VERSION "dbc-export 1 2026.26.6.5"

NS_ :

BS_:

BU_: APP APS BMS CC CMP CMPD CP DAS DI DIF DIR EPBL EPBR EVSE FC GTW HCML HCMR HVP ICR PCS PCS2 PLG PM PMF PMR PTC SCCM SCM SCS SDCR TAS UMC V2G VC VCBATT VCBATT0 VCBATT1 VCBATT2 VCFRONT VCFRONT1 VCFRONT2 VCLEFT VCRIGHT VCSEAT2L VCSEAT2R VCSEC

BO_ 1290 HVP_alertLog: 8 HVP
 SG_ HVP_alertID M : 0|7@1+ (1,0) [0|127] "" Vector__XXX
 SG_ HVP_alertSet : 15|1@1+ (1,0) [0|1] "" Vector__XXX
 SG_ HVP_a005_current m5 : 16|24@1- (0.001,0) [-8388.608|8388.607] "A" Vector__XXX
 SG_ HVP_a006_current m6 : 16|24@1- (0.001,0) [-8388.608|8388.607] "A" Vector__XXX
 SG_ HVP_a007_current m7 : 16|24@1- (0.001,0) [-8388.608|8388.607] "A" Vector__XXX
 SG_ HVP_a008_temperature m8 : 16|16@1- (0.01,0) [-327.68|327.67] "C" Vector__XXX
 SG_ HVP_a008_sensorId m8 : 32|6@1+ (1,1) [1|64] "" Vector__XXX
 SG_ HVP_a008_primaryChainSensor m8 : 38|1@1+ (1,0) [0|1] "" Vector__XXX
 SG_ HVP_a009_brickVoltage m9 : 16|16@1- (0.001,0) [-32.768|32.767] "V" Vector__XXX
 SG_ HVP_a009_brickId m9 : 32|7@1+ (1,1) [1|128] "" Vector__XXX
 SG_ HVP_a009_primaryChainSensor m9 : 39|1@1+ (1,0) [0|1] "" Vector__XXX
 SG_ HVP_a010_brickVoltage m10 : 16|16@1- (0.001,0) [-32.768|32.767] "V" Vector__XXX
 SG_ HVP_a010_brickId m10 : 32|7@1+ (1,1) [1|128] "" Vector__XXX
 SG_ HVP_a010_primaryChainSensor m10 : 39|1@1+ (1,0) [0|1] "" Vector__XXX
 SG_ HVP_a012_breakLocationA m12 : 16|5@1+ (1,0) [0|31] "" Vector__XXX
 SG_ HVP_a012_bmbCommStatusTypeA m12 : 21|2@1+ (1,0) [0|3] "" Vector__XXX
 SG_ HVP_a012_breakLocationB m12 : 24|5@1+ (1,0) [0|31] "" Vector__XXX
 SG_ HVP_a012_bmbCommStatusTypeB m12 : 29|2@1+ (1,0) [0|3] "" Vector__XXX
 SG_ HVP_a013_breakLocationA m13 : 16|5@1+ (1,0) [0|31] "" Vector__XXX
 SG_ HVP_a013_bmbCommStatusTypeA m13 : 21|2@1+ (1,0) [0|3] "" Vector__XXX
 SG_ HVP_a013_breakLocationB m13 : 24|5@1+ (1,0) [0|31] "" Vector__XXX
 SG_ HVP_a013_bmbCommStatusTypeB m13 : 29|2@1+ (1,0) [0|3] "" Vector__XXX
 SG_ HVP_a013_bmbChainBreakType m13 : 32|3@1+ (1,0) [0|7] "" Vector__XXX
 SG_ HVP_a018_dcLinkVoltage m18 : 16|16@1+ (0.01,0) [0|655.35] "V" Vector__XXX
 SG_ HVP_a018_battery12V m18 : 32|12@1+ (0.1,0) [0|409.5] "V" Vector__XXX
 SG_ HVP_a018_remainingPcsPowerCycles m18 : 44|2@1+ (1,0) [0|3] "" Vector__XXX
 SG_ HVP_a018_remainingPcsRecoveriesA m18 : 46|2@1+ (1,0) [0|3] "" Vector__XXX
 SG_ HVP_a018_hvcHardwareSupportsCycl m18 : 48|1@1+ (1,0) [0|1] "" Vector__XXX
 SG_ HVP_a018_pcsHardwareOkToBePowerC m18 : 49|1@1+ (1,0) [0|1] "" Vector__XXX
 SG_ HVP_a018_gpioLogicPowerEnable m18 : 50|1@1+ (1,0) [0|1] "" Vector__XXX
 SG_ HVP_a018_gpioDcDcEnable m18 : 51|1@1+ (1,0) [0|1] "" Vector__XXX
 SG_ HVP_a018_gpioChgEnable m18 : 52|1@1+ (1,0) [0|1] "" Vector__XXX
 SG_ HVP_a020_energyReserveV m20 : 16|16@1+ (0.001,0) [0|65.534] "V" Vector__XXX
 SG_ HVP_a020_shuntCurrentAux m20 : 32|16@1- (0.1,0) [-3276.8|3276.7] "A" Vector__XXX
 SG_ HVP_a020_shuntTemperature m20 : 48|16@1- (0.01,0) [-327.68|327.67] "C" Vector__XXX
 SG_ HVP_a021_pyroStatus m21 : 16|2@1+ (1,0) [0|3] "" Vector__XXX
 SG_ HVP_a021_ErTestFailed m21 : 18|1@1+ (1,0) [0|1] "" Vector__XXX
 SG_ HVP_a021_HighSideSwitchTestFaile m21 : 19|1@1+ (1,0) [0|1] "" Vector__XXX
 SG_ HVP_a021_LowSideSwitchTestFailed m21 : 20|1@1+ (1,0) [0|1] "" Vector__XXX
 SG_ HVP_a021_RefCurrentTestFailed m21 : 21|1@1+ (1,0) [0|1] "" Vector__XXX
 SG_ HVP_a021_PyroLeakTestFailed m21 : 22|1@1+ (1,0) [0|1] "" Vector__XXX
 SG_ HVP_a021_SquibResTestFailed m21 : 23|1@1+ (1,0) [0|1] "" Vector__XXX
 SG_ HVP_a021_VstTestFailed m21 : 24|1@1+ (1,0) [0|1] "" Vector__XXX
 SG_ HVP_a021_SquibResistance m21 : 25|16@1+ (0.001,0) [0|65.534] "Ohm" Vector__XXX
 SG_ HVP_a021_OneShotSequence m21 : 41|1@1+ (1,0) [0|1] "" Vector__XXX
 SG_ HVP_a021_HighSide m21 : 42|1@1+ (1,0) [0|1] "" Vector__XXX
 SG_ HVP_a021_LowSide m21 : 43|1@1+ (1,0) [0|1] "" Vector__XXX
 SG_ HVP_a021_Aout m21 : 44|14@1+ (0.001,0) [0|16.382] "V" Vector__XXX
 SG_ HVP_a022_pyroStatus m22 : 16|2@1+ (1,0) [0|3] "" Vector__XXX
 SG_ HVP_a022_PyroLeakTestFailed m22 : 18|1@1+ (1,0) [0|1] "" Vector__XXX
 SG_ HVP_a022_OneShotSequence m22 : 19|1@1+ (1,0) [0|1] "" Vector__XXX
 SG_ HVP_a022_HighSide m22 : 20|1@1+ (1,0) [0|1] "" Vector__XXX
 SG_ HVP_a022_LowSide m22 : 21|1@1+ (1,0) [0|1] "" Vector__XXX
 SG_ HVP_a022_Aout m22 : 24|14@1+ (0.001,0) [0|16.382] "V" Vector__XXX
 SG_ HVP_a022_SquibResistance m22 : 40|16@1+ (0.001,0) [0|65.534] "Ohm" Vector__XXX
 SG_ HVP_a024_voltage m24 : 16|16@1+ (0.1,0) [0|6553.5] "V" Vector__XXX
 SG_ HVP_a025_voltage1 m25 : 16|16@1+ (0.1,0) [0|6553.5] "V" Vector__XXX
 SG_ HVP_a025_voltage2 m25 : 32|16@1+ (0.1,0) [0|6553.5] "V" Vector__XXX
 SG_ HVP_a025_packVoltage m25 : 48|16@1+ (0.1,0) [0|6553.5] "V" Vector__XXX
 SG_ HVP_a026_hvilStatus m26 : 16|4@1+ (1,0) [0|15] "" Vector__XXX
 SG_ HVP_a026_inputVoltage m26 : 24|8@1+ (0.04,0) [0|10.2] "V" Vector__XXX
 SG_ HVP_a026_outputVoltage m26 : 32|8@1+ (0.04,0) [0|10.2] "V" Vector__XXX
 SG_ HVP_a026_internalVoltage m26 : 40|8@1+ (0.04,0) [0|10.16] "V" Vector__XXX
 SG_ HVP_a026_dirVoltage m26 : 48|8@1+ (0.04,0) [0|10.16] "V" Vector__XXX
 SG_ HVP_a026_difVoltage m26 : 56|8@1+ (0.04,0) [0|10.16] "V" Vector__XXX
 SG_ HVP_a028_packVoltage m28 : 16|16@1+ (0.1,0) [0|6553.5] "V" Vector__XXX
 SG_ HVP_a028_sumOfBrickV m28 : 32|16@1+ (0.1,0) [0|6553.5] "V" Vector__XXX
 SG_ HVP_a030_packPositiveLinkV m30 : 16|16@1- (0.1,0) [-3276.8|3276.7] "V" Vector__XXX
 SG_ HVP_a030_dcPositiveLinkV m30 : 32|16@1- (0.1,0) [-3276.8|3276.7] "V" Vector__XXX
 SG_ HVP_a031_packNegativeLinkV m31 : 16|16@1- (0.1,0) [-3276.8|3276.7] "V" Vector__XXX
 SG_ HVP_a031_dcNegativeLinkV m31 : 32|16@1- (0.1,0) [-3276.8|3276.7] "V" Vector__XXX
 SG_ HVP_a033_contactorPowerV m33 : 16|16@1+ (0.1,0) [0|6553.5] "V" Vector__XXX
 SG_ HVP_a033_coilCurrent m33 : 32|16@1+ (0.1,0) [0|6553.5] "A" Vector__XXX
 SG_ HVP_a033_pwmDutyCylePositive m33 : 48|8@1+ (1,0) [0|255] "Percentage" Vector__XXX
 SG_ HVP_a033_pwmDutyCyleNegative m33 : 56|8@1+ (1,0) [0|255] "Percentage" Vector__XXX
 SG_ HVP_a035_contactorPowerV m35 : 16|16@1+ (0.1,0) [0|6553.5] "V" Vector__XXX
 SG_ HVP_a035_coilCurrent m35 : 32|16@1+ (0.1,0) [0|6553.5] "A" Vector__XXX
 SG_ HVP_a035_pwmDutyCylePositive m35 : 48|8@1+ (1,0) [0|255] "Percentage" Vector__XXX
 SG_ HVP_a035_pwmDutyCyleNegative m35 : 56|8@1+ (1,0) [0|255] "Percentage" Vector__XXX
 SG_ HVP_a036_pyroFiringHandle m36 : 16|4@1+ (1,0) [0|15] "" Vector__XXX
 SG_ HVP_a036_pyroFiringTime m36 : 24|16@1+ (1,0) [0|65535] "" Vector__XXX
 SG_ HVP_a036_pyroFiringAttempt m36 : 40|4@1+ (1,0) [0|15] "" Vector__XXX
 SG_ HVP_a037_pyroFiringHandle m37 : 16|4@1+ (1,0) [0|15] "" Vector__XXX
 SG_ HVP_a039_posContactorFailed m39 : 16|1@1+ (1,0) [0|1] "" Vector__XXX
 SG_ HVP_a039_negContactorFailed m39 : 17|1@1+ (1,0) [0|1] "" Vector__XXX
 SG_ HVP_a040_powerVoltage m40 : 16|8@1+ (0.1,0) [0|25.5] "V" Vector__XXX
 SG_ HVP_a040_coilCurrent m40 : 24|8@1+ (0.1,0) [0|25.5] "A" Vector__XXX
 SG_ HVP_a040_posCtrVoltageDrop m40 : 32|15@1- (0.1,0) [-1638.4|1638.3] "V" Vector__XXX
 SG_ HVP_a040_negCtrVoltageDrop m40 : 47|15@1- (0.1,0) [-1638.4|1638.3] "V" Vector__XXX
 SG_ HVP_a040_posCtrAuxOpen m40 : 62|1@1+ (1,0) [0|1] "" Vector__XXX
 SG_ HVP_a040_negCtrAuxOpen m40 : 63|1@1+ (1,0) [0|1] "" Vector__XXX
 SG_ HVP_a041_overCurrent m41 : 16|1@1+ (1,0) [0|1] "" Vector__XXX
 SG_ HVP_a041_overChargeCurrent m41 : 17|1@1+ (1,0) [0|1] "" Vector__XXX
 SG_ HVP_a041_overDischargeCurrent m41 : 18|1@1+ (1,0) [0|1] "" Vector__XXX
 SG_ HVP_a041_overVoltage m41 : 19|1@1+ (1,0) [0|1] "" Vector__XXX
 SG_ HVP_a041_overTemperature m41 : 20|1@1+ (1,0) [0|1] "" Vector__XXX
 SG_ HVP_a041_underVoltage m41 : 21|1@1+ (1,0) [0|1] "" Vector__XXX
 SG_ HVP_a041_crashEvent m41 : 22|1@1+ (1,0) [0|1] "" Vector__XXX
 SG_ HVP_a041_packContactorHw m41 : 23|1@1+ (1,0) [0|1] "" Vector__XXX
 SG_ HVP_a041_notAllowedtoEnergize m41 : 24|1@1+ (1,0) [0|1] "" Vector__XXX
 SG_ HVP_a041_bmbMia m41 : 25|1@1+ (1,0) [0|1] "" Vector__XXX
 SG_ HVP_a041_hvilFault m41 : 26|1@1+ (1,0) [0|1] "" Vector__XXX
 SG_ HVP_a041_contactorStateWelded m41 : 27|1@1+ (1,0) [0|1] "" Vector__XXX
 SG_ HVP_a041_shuntHwMia m41 : 28|1@1+ (1,0) [0|1] "" Vector__XXX
 SG_ HVP_a041_shuntCurrentMia m41 : 29|1@1+ (1,0) [0|1] "" Vector__XXX
 SG_ HVP_a041_packVoltageMismatch m41 : 30|1@1+ (1,0) [0|1] "" Vector__XXX
 SG_ HVP_a041_gpoRequestActive m41 : 31|1@1+ (1,0) [0|1] "" Vector__XXX
 SG_ HVP_a041_fcContactorClosing m41 : 32|1@1+ (1,0) [0|1] "" Vector__XXX
 SG_ HVP_a041_fcContactorOpening m41 : 33|1@1+ (1,0) [0|1] "" Vector__XXX
 SG_ HVP_a041_resetRequestRequired m41 : 34|1@1+ (1,0) [0|1] "" Vector__XXX
 SG_ HVP_a041_pyroFault m41 : 35|1@1+ (1,0) [0|1] "" Vector__XXX
 SG_ HVP_a041_dcLinkOverVoltage m41 : 36|1@1+ (1,0) [0|1] "" Vector__XXX
 SG_ HVP_a042_overCurrent m42 : 16|1@1+ (1,0) [0|1] "" Vector__XXX
 SG_ HVP_a042_overChargeCurrent m42 : 17|1@1+ (1,0) [0|1] "" Vector__XXX
 SG_ HVP_a042_overDischargeCurrent m42 : 18|1@1+ (1,0) [0|1] "" Vector__XXX
 SG_ HVP_a042_overVoltage m42 : 19|1@1+ (1,0) [0|1] "" Vector__XXX
 SG_ HVP_a042_overTemperature m42 : 20|1@1+ (1,0) [0|1] "" Vector__XXX
 SG_ HVP_a042_crashEvent m42 : 21|1@1+ (1,0) [0|1] "" Vector__XXX
 SG_ HVP_a042_fcContactorHw m42 : 22|1@1+ (1,0) [0|1] "" Vector__XXX
 SG_ HVP_a042_notAllowedtoEnergize m42 : 23|1@1+ (1,0) [0|1] "" Vector__XXX
 SG_ HVP_a042_bmsHvsMia m42 : 24|1@1+ (1,0) [0|1] "" Vector__XXX
 SG_ HVP_a042_cpMia m42 : 25|1@1+ (1,0) [0|1] "" Vector__XXX
 SG_ HVP_a042_cpFault m42 : 26|1@1+ (1,0) [0|1] "" Vector__XXX
 SG_ HVP_a042_supply12V m42 : 27|1@1+ (1,0) [0|1] "" Vector__XXX
 SG_ HVP_a042_supplyVer m42 : 28|1@1+ (1,0) [0|1] "" Vector__XXX
 SG_ HVP_a042_packVoltageMismatch m42 : 29|1@1+ (1,0) [0|1] "" Vector__XXX
 SG_ HVP_a042_hvilFault m42 : 30|1@1+ (1,0) [0|1] "" Vector__XXX
 SG_ HVP_a042_contactorStateWelded m42 : 31|1@1+ (1,0) [0|1] "" Vector__XXX
 SG_ HVP_a042_shuntHwMia m42 : 32|1@1+ (1,0) [0|1] "" Vector__XXX
 SG_ HVP_a042_shuntCurrentMia m42 : 33|1@1+ (1,0) [0|1] "" Vector__XXX
 SG_ HVP_a042_packContactorClosing m42 : 34|1@1+ (1,0) [0|1] "" Vector__XXX
 SG_ HVP_a042_packContactorOpening m42 : 35|1@1+ (1,0) [0|1] "" Vector__XXX
 SG_ HVP_a042_resetRequestRequired m42 : 36|1@1+ (1,0) [0|1] "" Vector__XXX
 SG_ HVP_a042_cpVersionMismatch m42 : 37|1@1+ (1,0) [0|1] "" Vector__XXX
 SG_ HVP_a043_overCurrent m43 : 16|1@1+ (1,0) [0|1] "" Vector__XXX
 SG_ HVP_a043_overChargeCurrent m43 : 17|1@1+ (1,0) [0|1] "" Vector__XXX
 SG_ HVP_a043_overDischargeCurrent m43 : 18|1@1+ (1,0) [0|1] "" Vector__XXX
 SG_ HVP_a043_overVoltage m43 : 19|1@1+ (1,0) [0|1] "" Vector__XXX
 SG_ HVP_a043_overTemperature m43 : 20|1@1+ (1,0) [0|1] "" Vector__XXX
 SG_ HVP_a043_underVoltage m43 : 21|1@1+ (1,0) [0|1] "" Vector__XXX
 SG_ HVP_a043_crashEvent m43 : 22|1@1+ (1,0) [0|1] "" Vector__XXX
 SG_ HVP_a043_packContactorHw m43 : 23|1@1+ (1,0) [0|1] "" Vector__XXX
 SG_ HVP_a043_notAllowedtoEnergize m43 : 24|1@1+ (1,0) [0|1] "" Vector__XXX
 SG_ HVP_a043_bmbMia m43 : 25|1@1+ (1,0) [0|1] "" Vector__XXX
 SG_ HVP_a043_contactorOpened m43 : 26|1@1+ (1,0) [0|1] "" Vector__XXX
 SG_ HVP_a044_overCurrent m44 : 16|1@1+ (1,0) [0|1] "" Vector__XXX
 SG_ HVP_a044_overChargeCurrent m44 : 17|1@1+ (1,0) [0|1] "" Vector__XXX
 SG_ HVP_a044_overDischargeCurrent m44 : 18|1@1+ (1,0) [0|1] "" Vector__XXX
 SG_ HVP_a044_overVoltage m44 : 19|1@1+ (1,0) [0|1] "" Vector__XXX
 SG_ HVP_a044_overTemperature m44 : 20|1@1+ (1,0) [0|1] "" Vector__XXX
 SG_ HVP_a044_crashEvent m44 : 21|1@1+ (1,0) [0|1] "" Vector__XXX
 SG_ HVP_a044_fcContactorHw m44 : 22|1@1+ (1,0) [0|1] "" Vector__XXX
 SG_ HVP_a044_notAllowedtoEnergize m44 : 23|1@1+ (1,0) [0|1] "" Vector__XXX
 SG_ HVP_a044_bmsHvsMia m44 : 24|1@1+ (1,0) [0|1] "" Vector__XXX
 SG_ HVP_a044_cpMia m44 : 25|1@1+ (1,0) [0|1] "" Vector__XXX
 SG_ HVP_a044_cpFault m44 : 26|1@1+ (1,0) [0|1] "" Vector__XXX
 SG_ HVP_a044_supply12V m44 : 27|1@1+ (1,0) [0|1] "" Vector__XXX
 SG_ HVP_a044_supplyVer m44 : 28|1@1+ (1,0) [0|1] "" Vector__XXX
 SG_ HVP_a044_packVoltageMismatch m44 : 29|1@1+ (1,0) [0|1] "" Vector__XXX
 SG_ HVP_a044_contactorOpened m44 : 30|1@1+ (1,0) [0|1] "" Vector__XXX
 SG_ HVP_a044_cpVersionMismatch m44 : 31|1@1+ (1,0) [0|1] "" Vector__XXX
 SG_ HVP_a045_dcLinkVoltage m45 : 16|16@1+ (0.1,0) [0|6553.5] "V" Vector__XXX
 SG_ HVP_a046_shuntCurrent m46 : 16|16@1- (0.1,0) [-3276.8|3276.7] "A" Vector__XXX
 SG_ HVP_a046_shuntTemperature m46 : 32|16@1- (0.01,0) [-327.68|327.67] "C" Vector__XXX
 SG_ HVP_a046_asicTemperature m46 : 48|16@1- (0.01,0) [-327.68|327.67] "C" Vector__XXX
 SG_ HVP_a047_shuntCurrent m47 : 16|16@1- (0.1,0) [-3276.8|3276.7] "A" Vector__XXX
 SG_ HVP_a047_auxCurrent m47 : 32|16@1- (0.1,0) [-3276.8|3276.7] "A" Vector__XXX
 SG_ HVP_a049_contactorPowerV m49 : 16|16@1+ (0.1,0) [0|6553.5] "V" Vector__XXX
 SG_ HVP_a049_coilCurrent m49 : 32|16@1+ (0.1,0) [0|6553.5] "A" Vector__XXX
 SG_ HVP_a049_posCtrState m49 : 48|3@1+ (1,0) [1|7] "" Vector__XXX
 SG_ HVP_a049_negCtrState m49 : 51|3@1+ (1,0) [1|7] "" Vector__XXX
 SG_ HVP_a050_contactorPowerV m50 : 16|16@1+ (0.1,0) [0|6553.5] "V" Vector__XXX
 SG_ HVP_a050_coilCurrent m50 : 32|16@1+ (0.1,0) [0|6553.5] "A" Vector__XXX
 SG_ HVP_a050_posCtrState m50 : 48|3@1+ (1,0) [1|7] "" Vector__XXX
 SG_ HVP_a050_negCtrState m50 : 51|3@1+ (1,0) [1|7] "" Vector__XXX
 SG_ HVP_a051_shuntTemperature m51 : 16|16@1- (0.01,0) [-327.68|327.67] "C" Vector__XXX
 SG_ HVP_a051_shuntCurrent m51 : 32|16@1- (0.1,0) [-3276.8|3276.7] "A" Vector__XXX
 SG_ HVP_a051_energyReserveV m51 : 48|16@1+ (0.001,0) [0|65.534] "V" Vector__XXX
 SG_ HVP_a053_packVoltage m53 : 16|16@1+ (0.01,0) [0|655.35] "V" Vector__XXX
 SG_ HVP_a053_dcLinkVoltage m53 : 32|16@1+ (0.01,0) [0|655.35] "V" Vector__XXX
 SG_ HVP_a056_diagnosis m56 : 16|2@1+ (1,0) [1|3] "" Vector__XXX
 SG_ HVP_a056_shuntCurrent m56 : 24|16@1- (0.1,0) [-3276.8|3276.7] "A" Vector__XXX
 SG_ HVP_a056_posPackContactorState m56 : 40|3@1+ (1,0) [1|7] "" Vector__XXX
 SG_ HVP_a056_negPackContactorState m56 : 43|3@1+ (1,0) [1|7] "" Vector__XXX
 SG_ HVP_a056_posFcContactorState m56 : 48|3@1+ (1,0) [1|7] "" Vector__XXX
 SG_ HVP_a056_negFcContactorState m56 : 51|3@1+ (1,0) [1|7] "" Vector__XXX
 SG_ HVP_a058_VrefSample m58 : 16|16@1+ (0.0001,0) [0|6.5535] "V" Vector__XXX
 SG_ HVP_a058_bmbDeviceId m58 : 32|4@1+ (1,1) [1|16] "" Vector__XXX
 SG_ HVP_a058_VrefStatus m58 : 36|2@1+ (1,0) [0|3] "" Vector__XXX
 SG_ HVP_a058_VrefType m58 : 38|2@1+ (1,0) [0|3] "" Vector__XXX
 SG_ HVP_a060_stackVoltage m60 : 16|16@1+ (0.00128,0) [0|83.8848] "V" Vector__XXX
 SG_ HVP_a060_sumBrickVoltage m60 : 32|16@1+ (0.00128,0) [0|83.8848] "V" Vector__XXX
 SG_ HVP_a060_stackId m60 : 48|8@1+ (1,1) [1|256] "" Vector__XXX
 SG_ HVP_a062_bmbDeviceMask m62 : 16|16@1+ (1,0) [0|65535] "" Vector__XXX
 SG_ HVP_a067_hvilTypeFromHvp m67 : 16|2@1+ (1,0) [0|3] "" Vector__XXX
 SG_ HVP_a067_hvilTypeFromGateway m67 : 18|2@1+ (1,0) [0|3] "" Vector__XXX
 SG_ HVP_a067_hvilTypeIsFromCal m67 : 20|1@1+ (1,0) [0|1] "" Vector__XXX
 SG_ HVP_a068_shuntTemperature m68 : 16|16@1- (0.01,0) [-327.68|327.67] "C" Vector__XXX
 SG_ HVP_a068_shuntCurrent m68 : 32|16@1- (0.1,0) [-3276.8|3276.7] "A" Vector__XXX
 SG_ HVP_a068_energyReserveV m68 : 48|16@1+ (0.001,0) [0|65.534] "V" Vector__XXX

BO_ 938 HVP_alertMatrix: 8 HVP
 SG_ HVP_matrixIndex M : 0|4@1+ (1,0) [0|15] "" Vector__XXX
 SG_ HVP_w001_WatchdogReset m0 : 4|1@1+ (1,0) [0|1] "" Vector__XXX
 SG_ HVP_w002_UnusedAlert2 m0 : 5|1@1+ (1,0) [0|1] "" Vector__XXX
 SG_ HVP_w003_SwAssertion m0 : 6|1@1+ (1,0) [0|1] "" Vector__XXX
 SG_ HVP_w004_CrashEvent m0 : 7|1@1+ (1,0) [0|1] "" Vector__XXX
 SG_ HVP_w005_OverDchgCurrentFault m0 : 8|1@1+ (1,0) [0|1] "" Vector__XXX
 SG_ HVP_w006_OverChargeCurrentFault m0 : 9|1@1+ (1,0) [0|1] "" Vector__XXX
 SG_ HVP_w007_OverCurrentFault m0 : 10|1@1+ (1,0) [0|1] "" Vector__XXX
 SG_ HVP_w008_OverTemperatureFault m0 : 11|1@1+ (1,0) [0|1] "" Vector__XXX
 SG_ HVP_w009_OverVoltageFault m0 : 12|1@1+ (1,0) [0|1] "" Vector__XXX
 SG_ HVP_w010_UnderVoltageFault m0 : 13|1@1+ (1,0) [0|1] "" Vector__XXX
 SG_ HVP_w011_PrimaryBmbMiaFault m0 : 14|1@1+ (1,0) [0|1] "" Vector__XXX
 SG_ HVP_w012_BmbDataIntegrityLoss m0 : 15|1@1+ (1,0) [0|1] "" Vector__XXX
 SG_ HVP_w013_BmbCommunication m0 : 16|1@1+ (1,0) [0|1] "" Vector__XXX
 SG_ HVP_w014_BmsMiaOnHviFault m0 : 17|1@1+ (1,0) [0|1] "" Vector__XXX
 SG_ HVP_w015_CpMiaFault m0 : 18|1@1+ (1,0) [0|1] "" Vector__XXX
 SG_ HVP_w016_PcsMiaFault m0 : 19|1@1+ (1,0) [0|1] "" Vector__XXX
 SG_ HVP_w017_GtwMiaFault m0 : 20|1@1+ (1,0) [0|1] "" Vector__XXX
 SG_ HVP_w018_powerCyclingPcs m0 : 21|1@1+ (1,0) [0|1] "" Vector__XXX
 SG_ HVP_w019_CpFault m0 : 22|1@1+ (1,0) [0|1] "" Vector__XXX
 SG_ HVP_w020_ShuntHwMiaFault m0 : 23|1@1+ (1,0) [0|1] "" Vector__XXX
 SG_ HVP_w021_PyroMiaFault m0 : 24|1@1+ (1,0) [0|1] "" Vector__XXX
 SG_ HVP_w022_PyroMiaWarning m0 : 25|1@1+ (1,0) [0|1] "" Vector__XXX
 SG_ HVP_w023_BmbResetRecovery m0 : 26|1@1+ (1,0) [0|1] "" Vector__XXX
 SG_ HVP_w024_Supply12vFault m0 : 27|1@1+ (1,0) [0|1] "" Vector__XXX
 SG_ HVP_w025_VerSupplyFault m0 : 28|1@1+ (1,0) [0|1] "" Vector__XXX
 SG_ HVP_w026_HvilFault m0 : 29|1@1+ (1,0) [0|1] "" Vector__XXX
 SG_ HVP_w027_BmsMiaOnHvsFault m0 : 30|1@1+ (1,0) [0|1] "" Vector__XXX
 SG_ HVP_w028_PackVoltMismatchFault m0 : 31|1@1+ (1,0) [0|1] "" Vector__XXX
 SG_ HVP_w029_EnsMiaFault m0 : 32|1@1+ (1,0) [0|1] "" Vector__XXX
 SG_ HVP_w030_PackPosCtrArcFault m0 : 33|1@1+ (1,0) [0|1] "" Vector__XXX
 SG_ HVP_w031_packNegCtrArcFault m0 : 34|1@1+ (1,0) [0|1] "" Vector__XXX
 SG_ HVP_w032_ShuntHwAndBmsMiaFault m0 : 35|1@1+ (1,0) [0|1] "" Vector__XXX
 SG_ HVP_w033_fcContHwFault m0 : 36|1@1+ (1,0) [0|1] "" Vector__XXX
 SG_ HVP_w034_cpMismatchFault m0 : 37|1@1+ (1,0) [0|1] "" Vector__XXX
 SG_ HVP_w035_packContHwFault m0 : 38|1@1+ (1,0) [0|1] "" Vector__XXX
 SG_ HVP_w036_pyroFuseBlown m0 : 39|1@1+ (1,0) [0|1] "" Vector__XXX
 SG_ HVP_w037_pyroFuseFailedToBlow m0 : 40|1@1+ (1,0) [0|1] "" Vector__XXX
 SG_ HVP_w038_CpilFault m0 : 41|1@1+ (1,0) [0|1] "" Vector__XXX
 SG_ HVP_w039_PackContactorFellOpen m0 : 42|1@1+ (1,0) [0|1] "" Vector__XXX
 SG_ HVP_w040_FcContactorFellOpen m0 : 43|1@1+ (1,0) [0|1] "" Vector__XXX
 SG_ HVP_w041_packCtrCloseBlocked m0 : 44|1@1+ (1,0) [0|1] "" Vector__XXX
 SG_ HVP_w042_fcCtrCloseBlocked m0 : 45|1@1+ (1,0) [0|1] "" Vector__XXX
 SG_ HVP_w043_packContactorForceOpen m0 : 46|1@1+ (1,0) [0|1] "" Vector__XXX
 SG_ HVP_w044_fcContactorForceOpen m0 : 47|1@1+ (1,0) [0|1] "" Vector__XXX
 SG_ HVP_w045_dcLinkOverVoltage m0 : 48|1@1+ (1,0) [0|1] "" Vector__XXX
 SG_ HVP_w046_shuntOverTemperature m0 : 49|1@1+ (1,0) [0|1] "" Vector__XXX
 SG_ HVP_w047_passivePyroDeploy m0 : 50|1@1+ (1,0) [0|1] "" Vector__XXX
 SG_ HVP_w048_swUnsupportedBmbAsicTyp m0 : 51|1@1+ (1,0) [0|1] "" Vector__XXX
 SG_ HVP_w049_packCtrCloseFailed m0 : 52|1@1+ (1,0) [0|1] "" Vector__XXX
 SG_ HVP_w050_fcCtrCloseFailed m0 : 53|1@1+ (1,0) [0|1] "" Vector__XXX
 SG_ HVP_w051_shuntThermistorMia m0 : 54|1@1+ (1,0) [0|1] "" Vector__XXX
 SG_ HVP_w052_BmbStatusRegError m0 : 55|1@1+ (1,0) [0|1] "" Vector__XXX
 SG_ HVP_w053_hvVoltageSensorRational m0 : 56|1@1+ (1,0) [0|1] "" Vector__XXX
 SG_ HVP_w054_swMissingConfigBlock m0 : 57|1@1+ (1,0) [0|1] "" Vector__XXX
 SG_ HVP_w055_swMissingPartNumber m0 : 58|1@1+ (1,0) [0|1] "" Vector__XXX
 SG_ HVP_w056_contactorFailedToOpen m0 : 59|1@1+ (1,0) [0|1] "" Vector__XXX
 SG_ HVP_w057_BatmanDiagnosticsError m0 : 60|1@1+ (1,0) [0|1] "" Vector__XXX
 SG_ HVP_w058_BmbVrefBad m0 : 61|1@1+ (1,0) [0|1] "" Vector__XXX
 SG_ HVP_w059_BmbVrefWarning m0 : 62|1@1+ (1,0) [0|1] "" Vector__XXX
 SG_ HVP_w060_StackVoltageSense m0 : 63|1@1+ (1,0) [0|1] "" Vector__XXX
 SG_ HVP_w061_ShuntCurrentRationality m1 : 4|1@1+ (1,0) [0|1] "" Vector__XXX
 SG_ HVP_w062_BmbOtpConfigError m1 : 5|1@1+ (1,0) [0|1] "" Vector__XXX
 SG_ HVP_w063_BmbBrickVRationality m1 : 6|1@1+ (1,0) [0|1] "" Vector__XXX
 SG_ HVP_w064_BmbAuxVRationality m1 : 7|1@1+ (1,0) [0|1] "" Vector__XXX
 SG_ HVP_w065_FastOpenVshDetected m1 : 8|1@1+ (1,0) [0|1] "" Vector__XXX
 SG_ HVP_w067_HvilCalNodeMismatch m1 : 10|1@1+ (1,0) [0|1] "" Vector__XXX
 SG_ HVP_w068_shuntUnexpectedThermist m1 : 11|1@1+ (1,0) [0|1] "" Vector__XXX
 SG_ HVP_w069_hviCanFrameRxDropped m1 : 12|1@1+ (1,0) [0|1] "" Vector__XXX
 SG_ HVP_w070_hvsCanFrameRxDropped m1 : 13|1@1+ (1,0) [0|1] "" Vector__XXX
 SG_ HVP_w071_PassivePyroVrefRational m1 : 14|1@1+ (1,0) [0|1] "" Vector__XXX

BO_ 522 HVP_contactorState: 6 HVP
 SG_ HVP_packContNegativeState : 0|3@1+ (1,0) [1|7] "" Vector__XXX
 SG_ HVP_packContPositiveState : 3|3@1+ (1,0) [1|7] "" Vector__XXX
 SG_ HVP_fcContPositiveAuxOpen : 6|1@1+ (1,0) [0|1] "" Vector__XXX
 SG_ HVP_fcContNegativeAuxOpen : 7|1@1+ (1,0) [0|1] "" Vector__XXX
 SG_ HVP_packContactorSetState : 8|4@1+ (1,0) [1|15] "" Vector__XXX
 SG_ HVP_fcContNegativeState : 12|3@1+ (1,0) [1|7] "" Vector__XXX
 SG_ HVP_contactorsBlocked : 15|1@1+ (1,0) [0|1] "" Vector__XXX
 SG_ HVP_fcContPositiveState : 16|3@1+ (1,0) [1|7] "" Vector__XXX
 SG_ HVP_fcContactorSetState : 19|4@1+ (1,0) [1|15] "" Vector__XXX
 SG_ HVP_fcCtrsRequestStatus : 24|2@1+ (1,0) [0|3] "" Vector__XXX
 SG_ HVP_fcCtrsResetRequestRequired : 26|1@1+ (1,0) [0|1] "" Vector__XXX
 SG_ HVP_fcCtrsOpenNowRequested : 27|1@1+ (1,0) [0|1] "" Vector__XXX
 SG_ HVP_fcCtrsOpenRequested : 28|1@1+ (1,0) [0|1] "" Vector__XXX
 SG_ HVP_fcCtrsClosingAllowed : 29|1@1+ (1,0) [0|1] "" Vector__XXX
 SG_ HVP_packCtrsRequestStatus : 30|2@1+ (1,0) [0|3] "" Vector__XXX
 SG_ HVP_packCtrsResetRequestRequired : 32|1@1+ (1,0) [0|1] "" Vector__XXX
 SG_ HVP_packCtrsOpenNowRequested : 33|1@1+ (1,0) [0|1] "" Vector__XXX
 SG_ HVP_packCtrsOpenRequested : 34|1@1+ (1,0) [0|1] "" Vector__XXX
 SG_ HVP_packCtrsClosingAllowed : 35|1@1+ (1,0) [0|1] "" Vector__XXX
 SG_ HVP_dcLinkAllowedToEnergize : 36|1@1+ (1,0) [0|1] "" Vector__XXX
 SG_ HVP_pyroTestInProgress : 37|1@1+ (1,0) [0|1] "" Vector__XXX
 SG_ HVP_hvilDiag : 40|4@1+ (1,0) [0|15] "" Vector__XXX
 SG_ HVP_fcLinkAllowedToEnergize : 44|2@1+ (1,0) [0|3] "" Vector__XXX

BO_ 1962 HVP_debugMessage: 8 HVP
 SG_ HVP_debugMessageMultiplexer M : 0|4@1+ (1,0) [0|15] "" Vector__XXX
 SG_ HVP_ecuLogUploadRequest m1 : 4|2@1+ (1,0) [0|3] "" Vector__XXX
 SG_ HVP_dcLinkVoltage m1 : 8|16@1- (0.1,0) [-3276.8|3276.7] "V" Vector__XXX
 SG_ HVP_packVoltage m1 : 24|16@1- (0.1,0) [-3276.8|3276.7] "V" Vector__XXX
 SG_ HVP_fcLinkVoltage m1 : 40|16@1- (0.1,0) [-3276.8|3276.7] "V" Vector__XXX
 SG_ HVP_10HzTask_stackUsage m1 : 56|7@1+ (1,0) [0|100] "%" Vector__XXX
 SG_ HVP_packContVoltage m2 : 4|12@1+ (0.1,0) [0|30] "V" Vector__XXX
 SG_ HVP_packNegativeV m2 : 16|16@1- (0.1,0) [-550|550] "V" Vector__XXX
 SG_ HVP_packPositiveV m2 : 32|16@1- (0.1,0) [-550|550] "V" Vector__XXX
 SG_ HVP_pyroAnalog m2 : 48|12@1+ (0.1,0) [0|3] "V" Vector__XXX
 SG_ HVP_shuntSetTCRCoeffA m2 : 60|1@1+ (1,0) [0|1] "" Vector__XXX
 SG_ HVP_shuntSetTCRCoeffB m2 : 61|1@1+ (1,0) [0|1] "" Vector__XXX
 SG_ HVP_shuntSetTCRCoeffC m2 : 62|1@1+ (1,0) [0|1] "" Vector__XXX
 SG_ HVP_shuntSetTCRCoeffD m2 : 63|1@1+ (1,0) [0|1] "" Vector__XXX
 SG_ HVP_fcContCoilCurrent m4 : 4|12@1+ (0.1,0) [0|7.5] "A" Vector__XXX
 SG_ HVP_fcContVoltage m4 : 16|12@1+ (0.1,0) [0|30] "V" Vector__XXX
 SG_ HVP_hvilInVoltage m4 : 28|12@1+ (0.1,0) [0|30] "V" Vector__XXX
 SG_ HVP_hvilOutVoltage m4 : 40|12@1+ (0.1,0) [0|30] "V" Vector__XXX
 SG_ HVP_shuntGainInvalidCountDbg m4 : 56|8@1+ (1,0) [0|255] "counts" Vector__XXX
 SG_ HVP_passivePyroRefVoltageMax m5 : 4|10@1+ (0.001,0.7) [0.7|1.722] "V" Vector__XXX
 SG_ HVP_passivePyroRefVoltageMin m5 : 14|10@1+ (0.001,0.7) [0.7|1.722] "V" Vector__XXX
 SG_ HVP_packContCoilCurrent m5 : 24|12@1+ (0.1,0) [0|7.5] "A" Vector__XXX
 SG_ HVP_battery12V m5 : 36|12@1+ (0.1,0) [0|30] "V" Vector__XXX
 SG_ HVP_fcLinkPositiveV m5 : 48|16@1- (0.1,0) [-550|550] "V" Vector__XXX

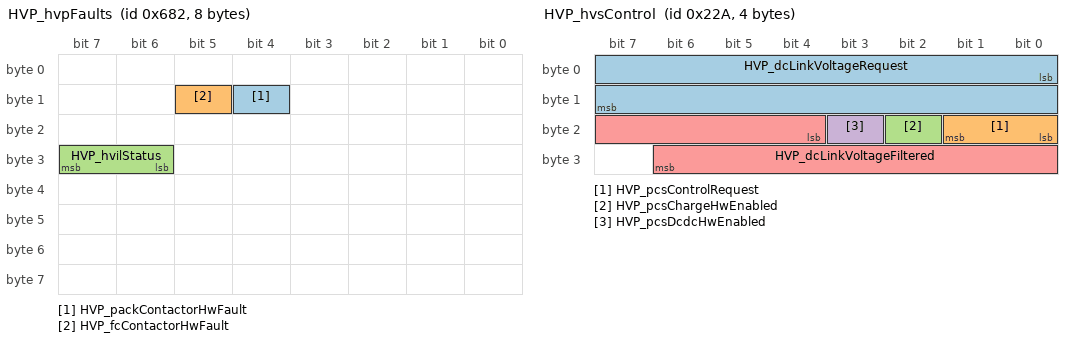
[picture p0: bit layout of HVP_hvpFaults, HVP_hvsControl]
BO_ 1666 HVP_hvpFaults: 8 HVP
 SG_ HVP_packContactorHwFault : 12|1@1+ (1,0) [0|1] "" Vector__XXX
 SG_ HVP_fcContactorHwFault : 13|1@1+ (1,0) [0|1] "" Vector__XXX
 SG_ HVP_hvilStatus : 30|2@1+ (1,0) [0|2] "" Vector__XXX

BO_ 554 HVP_hvsControl: 4 HVP
 SG_ HVP_dcLinkVoltageRequest : 0|16@1- (0.1,0) [-550|550] "V" Vector__XXX
 SG_ HVP_pcsControlRequest : 16|2@1+ (1,0) [0|3] "" Vector__XXX
 SG_ HVP_pcsChargeHwEnabled : 18|1@1+ (1,0) [0|1] "" Vector__XXX
 SG_ HVP_pcsDcdcHwEnabled : 19|1@1+ (1,0) [0|1] "" Vector__XXX
 SG_ HVP_dcLinkVoltageFiltered : 20|11@1- (1,0) [-550|550] "V" Vector__XXX

BO_ 784 HVP_info: 8 HVP
 SG_ HVP_infoIndex M : 0|8@1+ (1,0) [0|255] "" Vector__XXX
 SG_ HVP_buildType m10 : 8|3@1+ (1,0) [0|7] "" Vector__XXX
 SG_ HVP_buildConfigId m10 : 16|16@1+ (1,0) [0|65535] "" Vector__XXX
 SG_ HVP_hardwareId m10 : 32|16@1+ (1,0) [0|65535] "" Vector__XXX
 SG_ HVP_componentId m10 : 48|16@1+ (1,0) [0|65535] "" Vector__XXX
 SG_ HVP_pcbaId m11 : 16|8@1+ (1,0) [0|255] "" Vector__XXX
 SG_ HVP_assemblyId m11 : 24|8@1+ (1,0) [0|255] "" Vector__XXX
 SG_ HVP_usageId m11 : 32|16@1+ (1,0) [0|65535] "" Vector__XXX
 SG_ HVP_subUsageId m11 : 48|16@1+ (1,0) [0|65535] "" Vector__XXX
 SG_ HVP_platformType m13 : 8|8@1+ (1,0) [0|255] "" Vector__XXX
 SG_ HVP_appCrc m13 : 32|32@1+ (1,0) [0|4294967295] "" Vector__XXX
 SG_ HVP_appGitHash m17 : 8|56@1+ (1,0) [0|7.20575940379e+16] "" Vector__XXX
 SG_ HVP_bootGitHash m18 : 8|56@1+ (1,0) [0|7.20575940379e+16] "" Vector__XXX
 SG_ HVP_bootUdsProtoVersion m20 : 8|8@1+ (1,0) [0|255] "" Vector__XXX
 SG_ HVP_bootCrc m20 : 32|32@1+ (1,0) [0|4294967295] "" Vector__XXX

BO_ 1914 HVP_log1hz: 8 HVP
 SG_ HVP_log1HzIndex M : 0|3@1+ (1,0) [0|7] "" Vector__XXX
 SG_ HVP_bmbAsicType m0 : 3|2@1+ (1,0) [0|3] "" Vector__XXX
 SG_ HVP_shuntCurrentAuxLog m0 : 8|24@1- (0.001,0) [-8388.607|8388.607] "A" Vector__XXX
 SG_ HVP_pyroSquibResistance m0 : 32|16@1+ (0.001,0) [0|65.534] "Ohm" Vector__XXX
 SG_ HVP_shuntAsicChipXCoordinate m0 : 48|8@1+ (1,0) [0|255] "" Vector__XXX
 SG_ HVP_shuntAsicChipYCoordinate m0 : 56|8@1+ (1,0) [0|255] "" Vector__XXX
 SG_ HVP_hvilCalType m1 : 3|2@1+ (1,0) [0|3] "" Vector__XXX
 SG_ HVP_gpioPcsDcdcPwmEnable m1 : 5|1@1+ (1,0) [0|1] "" Vector__XXX
 SG_ HVP_gpioPcsChargePwmEnable m1 : 6|1@1+ (1,0) [0|1] "" Vector__XXX
 SG_ HVP_gpioPcsEnable m1 : 7|1@1+ (1,0) [0|1] "" Vector__XXX
 SG_ HVP_shuntAsicChipWaferNumber m1 : 8|8@1+ (1,0) [0|255] "" Vector__XXX
 SG_ HVP_energyReserveMin m1 : 16|16@1- (0.001,0) [-32.768|32.767] "V" Vector__XXX
 SG_ HVP_energyReserveMax m1 : 32|16@1- (0.001,0) [-32.768|32.767] "V" Vector__XXX
 SG_ HVP_energyReserveAvg m1 : 48|16@1- (0.001,0) [-32.768|32.767] "V" Vector__XXX

BO_ 1553 HVP_udsResponse: 8 HVP
 SG_ HVP_udsResponseData : 7|64@0+ (1,0) [0|1.84467440737e+19] "" Vector__XXX

BO_ 1208 ICR_alertLog: 8 ICR
 SG_ ICR_alertID M : 0|8@1+ (1,0) [0|255] "" Vector__XXX
 SG_ ICR_alertState : 15|1@1+ (1,0) [0|1] "" Vector__XXX
 SG_ ICR_a001_watchdogTaskAppDPM m1 : 16|1@1+ (1,0) [0|1] "" Vector__XXX
 SG_ ICR_a001_watchdogTaskMMWControl m1 : 17|1@1+ (1,0) [0|1] "" Vector__XXX
 SG_ ICR_a001_watchdogTaskSentinelInt m1 : 18|1@1+ (1,0) [0|1] "" Vector__XXX
 SG_ ICR_a001_watchdogTaskSentinelMod m1 : 19|1@1+ (1,0) [0|1] "" Vector__XXX
 SG_ ICR_a001_watchdogTaskComTXRAD m1 : 20|1@1+ (1,0) [0|1] "" Vector__XXX
 SG_ ICR_a001_watchdogTaskComRX m1 : 21|1@1+ (1,0) [0|1] "" Vector__XXX
 SG_ ICR_a001_watchdogTaskComTXVEH m1 : 22|1@1+ (1,0) [0|1] "" Vector__XXX
 SG_ ICR_a001_watchdogTaskComUDS m1 : 23|1@1+ (1,0) [0|1] "" Vector__XXX
 SG_ ICR_a001_watchdogTaskCommonError m1 : 24|1@1+ (1,0) [0|1] "" Vector__XXX
 SG_ ICR_a001_watchdogTaskUARTLog m1 : 25|1@1+ (1,0) [0|1] "" Vector__XXX
 SG_ ICR_a001_watchdogTaskDataDump m1 : 26|1@1+ (1,0) [0|1] "" Vector__XXX
 SG_ ICR_a001_watchdogRTOSAppRun10MS m1 : 27|1@1+ (1,0) [0|1] "" Vector__XXX
 SG_ ICR_a001_watchdogRTOSAppRun1MS m1 : 28|1@1+ (1,0) [0|1] "" Vector__XXX
 SG_ ICR_a001_InternalWatchdog m1 : 29|1@1+ (1,0) [0|1] "" Vector__XXX
 SG_ ICR_a015_NVMMMemOverflow m15 : 16|1@1+ (1,0) [0|1] "" Vector__XXX
 SG_ ICR_a015_NVMMFilesystemError m15 : 17|1@1+ (1,0) [0|1] "" Vector__XXX
 SG_ ICR_a015_NVMMRecordIDError m15 : 18|1@1+ (1,0) [0|1] "" Vector__XXX
 SG_ ICR_a059_voltageDrop m59 : 16|12@1+ (0.005443676,0) [0|22.29185322] "V" Vector__XXX
 SG_ ICR_a059_resistanceEstimate m59 : 28|12@1+ (0.00244,0) [0|9.9918] "Ohms" Vector__XXX
 SG_ ICR_a059_current m59 : 40|12@1+ (0.05,0) [0|204.75] "A" Vector__XXX
 SG_ ICR_a063_switchChannel m63 : 16|8@1+ (1,0) [0|255] "" Vector__XXX
 SG_ ICR_a063_switchType m63 : 24|8@1+ (1,0) [0|255] "" Vector__XXX
 SG_ ICR_a063_ADCVoltage m63 : 32|8@1+ (0.025,0) [0|6.375] "V" Vector__XXX
 SG_ ICR_a063_disconnected m63 : 40|1@1+ (1,0) [0|1] "" Vector__XXX
 SG_ ICR_a063_indeterminate m63 : 41|1@1+ (1,0) [0|1] "" Vector__XXX
 SG_ ICR_a063_stuckActive m63 : 42|1@1+ (1,0) [0|1] "" Vector__XXX
 SG_ ICR_a063_faulted m63 : 43|1@1+ (1,0) [0|1] "" Vector__XXX
 SG_ ICR_a133_nearClutter m133 : 16|8@1- (0.2,0) [-25.6|25.4] "dB" Vector__XXX
 SG_ ICR_a133_farClutter m133 : 24|8@1- (0.2,0) [-25.6|25.4] "dB" Vector__XXX
 SG_ ICR_a137_nearClutter m137 : 16|8@1- (0.2,0) [-25.6|25.4] "dB" Vector__XXX
 SG_ ICR_a137_farClutter m137 : 24|8@1- (0.2,0) [-25.6|25.4] "dB" Vector__XXX
 SG_ ICR_a139_nearClutter m139 : 16|8@1- (0.2,0) [-25.6|25.4] "dB" Vector__XXX
 SG_ ICR_a139_farClutter m139 : 24|8@1- (0.2,0) [-25.6|25.4] "dB" Vector__XXX
 SG_ ICR_a141_pmicQualityExcursion m141 : 16|1@1+ (1,0) [0|1] "" Vector__XXX
 SG_ ICR_a141_calDataNotCalibratedOrP m141 : 17|1@1+ (1,0) [0|1] "" Vector__XXX
 SG_ ICR_a141_calDataValRXPhaseAboveM m141 : 18|1@1+ (1,0) [0|1] "" Vector__XXX
 SG_ ICR_a141_calDataValRXPhaseMissin m141 : 19|1@1+ (1,0) [0|1] "" Vector__XXX
 SG_ ICR_a141_calDataValRangeBiasAbov m141 : 20|1@1+ (1,0) [0|1] "" Vector__XXX

BO_ 952 ICR_alertMatrix: 8 ICR
 SG_ ICR_matrixIndex M : 0|4@1+ (1,0) [0|15] "" Vector__XXX
 SG_ ICR_a001_WatchdogReset m0 : 4|1@1+ (1,0) [0|1] "" Vector__XXX
 SG_ ICR_a002_PowerLossReset m0 : 5|1@1+ (1,0) [0|1] "" Vector__XXX
 SG_ ICR_a003_SWAssertion m0 : 6|1@1+ (1,0) [0|1] "" Vector__XXX
 SG_ ICR_a005_CANTXError m0 : 8|1@1+ (1,0) [0|1] "" Vector__XXX
 SG_ ICR_a006_CANTX_cyclicError m0 : 9|1@1+ (1,0) [0|1] "" Vector__XXX
 SG_ ICR_a012_CPUReset m0 : 15|1@1+ (1,0) [0|1] "" Vector__XXX
 SG_ ICR_a013_AlertManagerFault m0 : 16|1@1+ (1,0) [0|1] "" Vector__XXX
 SG_ ICR_a015_NVMMError m0 : 18|1@1+ (1,0) [0|1] "" Vector__XXX
 SG_ ICR_a016_NVMMRecordError m0 : 19|1@1+ (1,0) [0|1] "" Vector__XXX
 SG_ ICR_a021_TaskSchedulerError m0 : 24|1@1+ (1,0) [0|1] "" Vector__XXX
 SG_ ICR_a022_TaskInitError m0 : 25|1@1+ (1,0) [0|1] "" Vector__XXX
 SG_ ICR_a029_CoreDump m0 : 32|1@1+ (1,0) [0|1] "" Vector__XXX
 SG_ ICR_a030_ECULogUploadRequest m0 : 33|1@1+ (1,0) [0|1] "" Vector__XXX
 SG_ ICR_a031_UDSActive m0 : 34|1@1+ (1,0) [0|1] "" Vector__XXX
 SG_ ICR_a041_HighCPULoad m0 : 44|1@1+ (1,0) [0|1] "" Vector__XXX
 SG_ ICR_a042_HighStackUsage m0 : 45|1@1+ (1,0) [0|1] "" Vector__XXX
 SG_ ICR_a043_Task1msError m0 : 46|1@1+ (1,0) [0|1] "" Vector__XXX
 SG_ ICR_a044_Task10msError m0 : 47|1@1+ (1,0) [0|1] "" Vector__XXX
 SG_ ICR_a045_Task100msError m0 : 48|1@1+ (1,0) [0|1] "" Vector__XXX
 SG_ ICR_a046_Task1000msError m0 : 49|1@1+ (1,0) [0|1] "" Vector__XXX
 SG_ ICR_a058_inputRHighSyncDebug m0 : 61|1@1+ (1,0) [0|1] "" Vector__XXX
 SG_ ICR_a059_inputResistanceHigh m0 : 62|1@1+ (1,0) [0|1] "" Vector__XXX
 SG_ ICR_a060_engineeringBuild m0 : 63|1@1+ (1,0) [0|1] "" Vector__XXX
 SG_ ICR_a061_XCPConnected m1 : 4|1@1+ (1,0) [0|1] "" Vector__XXX
 SG_ ICR_a062_XCPWasConnected m1 : 5|1@1+ (1,0) [0|1] "" Vector__XXX
 SG_ ICR_a063_SwitchFault m1 : 6|1@1+ (1,0) [0|1] "" Vector__XXX
 SG_ ICR_a064_busSleepReqTimeout m1 : 7|1@1+ (1,0) [0|1] "" Vector__XXX
 SG_ ICR_a133_radarBlocked m2 : 16|1@1+ (1,0) [0|1] "" Vector__XXX
 SG_ ICR_a134_radarPgood m2 : 17|1@1+ (1,0) [0|1] "" Vector__XXX
 SG_ ICR_a135_radarTxBallBreak m2 : 18|1@1+ (1,0) [0|1] "" Vector__XXX
 SG_ ICR_a136_radarHighTemperature m2 : 19|1@1+ (1,0) [0|1] "" Vector__XXX
 SG_ ICR_a137_radarBlocked m2 : 20|1@1+ (1,0) [0|1] "" Vector__XXX
 SG_ ICR_a138_DriverSideMismatch m2 : 21|1@1+ (1,0) [0|1] "" Vector__XXX
 SG_ ICR_a139_AbnormalBlockageDetecte m2 : 22|1@1+ (1,0) [0|1] "" Vector__XXX
 SG_ ICR_a140_OccupancyExceptionEncou m2 : 23|1@1+ (1,0) [0|1] "" Vector__XXX
 SG_ ICR_a141_RequiresReplacement m2 : 24|1@1+ (1,0) [0|1] "" Vector__XXX
 SG_ ICR_a142_ModeOverrideActive m2 : 25|1@1+ (1,0) [0|1] "" Vector__XXX
 SG_ ICR_a143_DSPCoreSkipped m2 : 26|1@1+ (1,0) [0|1] "" Vector__XXX
 SG_ ICR_a144_OccupancyNotificationAl m2 : 27|1@1+ (1,0) [0|1] "" Vector__XXX

BO_ 941 ICR_info: 8 ICR
 SG_ ICR_infoIndex M : 0|8@1+ (1,0) [0|255] "" Vector__XXX
 SG_ ICR_infoBuildType m10 : 8|3@1+ (1,0) [0|7] "" Vector__XXX
 SG_ ICR_infoPcbaId m11 : 32|8@1+ (1,0) [0|255] "" Vector__XXX
 SG_ ICR_infoAssemblyId m11 : 40|8@1+ (1,0) [0|255] "" Vector__XXX
 SG_ ICR_infoUsageId m11 : 48|16@1+ (1,0) [0|65535] "" Vector__XXX
 SG_ ICR_infoAppCrc m13 : 8|32@1+ (1,0) [0|4294967295] "" Vector__XXX
 SG_ ICR_infoBoardPartNumber17 m25 : 8|56@1+ (1,0) [0|7.20575940379e+16] "" Vector__XXX
 SG_ ICR_infoBoardPartNumber814 m26 : 8|56@1+ (1,0) [0|7.20575940379e+16] "" Vector__XXX
 SG_ ICR_infoBoardPartNumber1520 m27 : 8|48@1+ (1,0) [0|281474976710655] "" Vector__XXX

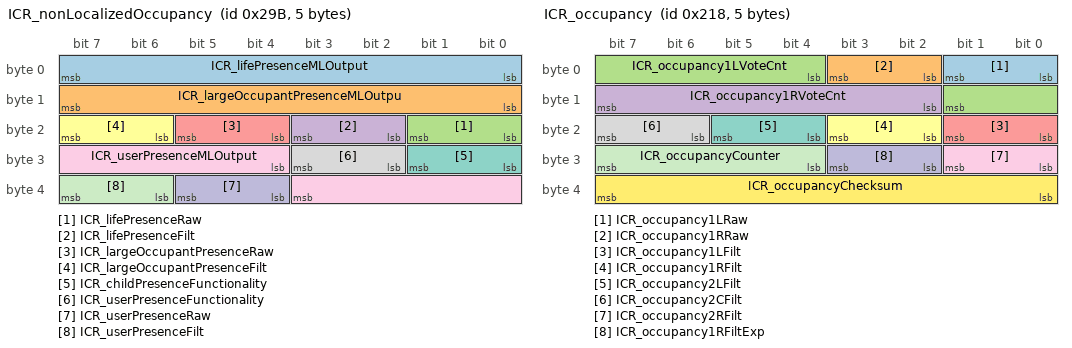
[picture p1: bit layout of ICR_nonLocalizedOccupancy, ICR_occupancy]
BO_ 667 ICR_nonLocalizedOccupancy: 5 ICR
 SG_ ICR_lifePresenceMLOutput : 0|8@1+ (0.004,0) [0|1.016] "points" Vector__XXX
 SG_ ICR_largeOccupantPresenceMLOutpu : 8|8@1+ (0.004,0) [0|1.016] "points" Vector__XXX
 SG_ ICR_lifePresenceRaw : 16|2@1+ (1,0) [1|3] "" Vector__XXX
 SG_ ICR_lifePresenceFilt : 18|2@1+ (1,0) [1|3] "" Vector__XXX
 SG_ ICR_largeOccupantPresenceRaw : 20|2@1+ (1,0) [0|2] "" Vector__XXX
 SG_ ICR_largeOccupantPresenceFilt : 22|2@1+ (1,0) [0|2] "" Vector__XXX
 SG_ ICR_childPresenceFunctionality : 24|2@1+ (1,0) [0|3] "" Vector__XXX
 SG_ ICR_userPresenceFunctionality : 26|2@1+ (1,0) [0|3] "" Vector__XXX
 SG_ ICR_userPresenceMLOutput : 28|8@1+ (0.004,0) [0|1.016] "points" Vector__XXX
 SG_ ICR_userPresenceRaw : 36|2@1+ (1,0) [0|2] "" Vector__XXX
 SG_ ICR_userPresenceFilt : 38|2@1+ (1,0) [0|2] "" Vector__XXX

BO_ 536 ICR_occupancy: 5 ICR
 SG_ ICR_occupancy1LRaw : 0|2@1+ (1,0) [0|2] "" Vector__XXX
 SG_ ICR_occupancy1RRaw : 2|2@1+ (1,0) [0|2] "" Vector__XXX
 SG_ ICR_occupancy1LVoteCnt : 4|6@1- (1,0) [-32|31] "" Vector__XXX
 SG_ ICR_occupancy1RVoteCnt : 10|6@1- (1,0) [-32|31] "" Vector__XXX
 SG_ ICR_occupancy1LFilt : 16|2@1+ (1,0) [0|2] "" Vector__XXX
 SG_ ICR_occupancy1RFilt : 18|2@1+ (1,0) [0|2] "" Vector__XXX
 SG_ ICR_occupancy2LFilt : 20|2@1+ (1,0) [0|2] "" Vector__XXX
 SG_ ICR_occupancy2CFilt : 22|2@1+ (1,0) [0|2] "" Vector__XXX
 SG_ ICR_occupancy2RFilt : 24|2@1+ (1,0) [0|2] "" Vector__XXX
 SG_ ICR_occupancy1RFiltExp : 26|2@1+ (1,0) [0|2] "" Vector__XXX
 SG_ ICR_occupancyCounter : 28|4@1+ (1,0) [0|15] "" Vector__XXX
 SG_ ICR_occupancyChecksum : 32|8@1+ (1,0) [0|255] "" Vector__XXX

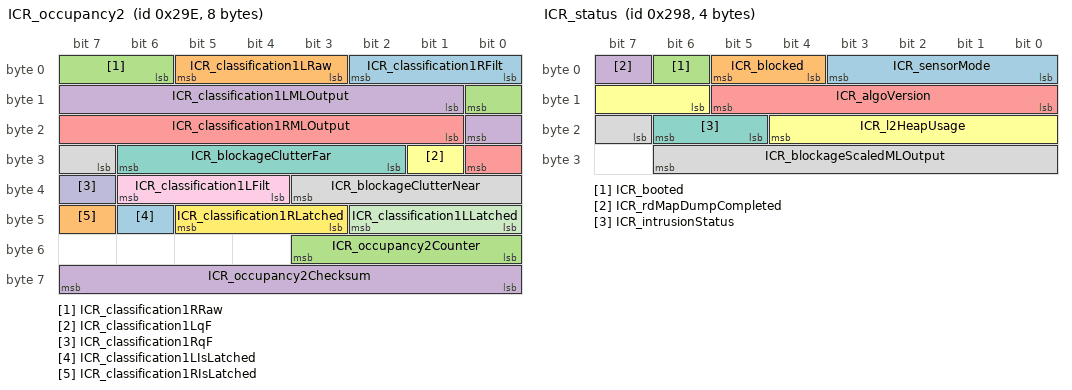
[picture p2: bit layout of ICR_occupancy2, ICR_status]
BO_ 670 ICR_occupancy2: 8 ICR
 SG_ ICR_classification1RFilt : 0|3@1+ (1,0) [1|7] "" Vector__XXX
 SG_ ICR_classification1LRaw : 3|3@1+ (1,0) [1|7] "" Vector__XXX
 SG_ ICR_classification1RRaw : 6|3@1+ (1,0) [1|7] "" Vector__XXX
 SG_ ICR_classification1LMLOutput : 9|8@1+ (0.004,0) [0|1.016] "points" Vector__XXX
 SG_ ICR_classification1RMLOutput : 17|8@1+ (0.004,0) [0|1.016] "points" Vector__XXX
 SG_ ICR_classification1LqF : 25|1@1+ (1,0) [0|1] "" Vector__XXX
 SG_ ICR_blockageClutterFar : 26|5@1- (0.5,-1.5) [-9|6] "dB" Vector__XXX
 SG_ ICR_blockageClutterNear : 31|5@1- (0.5,-1.5) [-9|6] "dB" Vector__XXX
 SG_ ICR_classification1LFilt : 36|3@1+ (1,0) [1|7] "" Vector__XXX
 SG_ ICR_classification1RqF : 39|1@1+ (1,0) [0|1] "" Vector__XXX
 SG_ ICR_classification1LLatched : 40|3@1+ (1,0) [1|7] "" Vector__XXX
 SG_ ICR_classification1RLatched : 43|3@1+ (1,0) [1|7] "" Vector__XXX
 SG_ ICR_classification1LIsLatched : 46|1@1+ (1,0) [0|1] "" Vector__XXX
 SG_ ICR_classification1RIsLatched : 47|1@1+ (1,0) [0|1] "" Vector__XXX
 SG_ ICR_occupancy2Counter : 48|4@1+ (1,0) [0|15] "" Vector__XXX
 SG_ ICR_occupancy2Checksum : 56|8@1+ (1,0) [0|255] "" Vector__XXX

BO_ 664 ICR_status: 4 ICR
 SG_ ICR_sensorMode : 0|4@1+ (1,0) [0|15] "" Vector__XXX
 SG_ ICR_blocked : 4|2@1+ (1,0) [1|3] "" Vector__XXX
 SG_ ICR_booted : 6|1@1+ (1,0) [0|1] "" Vector__XXX
 SG_ ICR_rdMapDumpCompleted : 7|1@1+ (1,0) [0|1] "" Vector__XXX
 SG_ ICR_algoVersion : 8|6@1+ (1,0) [0|63] "" Vector__XXX
 SG_ ICR_l2HeapUsage : 14|7@1+ (1,0) [0|127] "PCT" Vector__XXX
 SG_ ICR_intrusionStatus : 21|2@1+ (1,0) [0|3] "" Vector__XXX
 SG_ ICR_blockageScaledMLOutput : 23|8@1+ (0.004,0) [0|1.02] "points" Vector__XXX

BO_ 1624 ICR_udsResponse: 8 ICR
 SG_ ICR_udsResponseData : 7|64@0+ (1,0) [0|1.84467440737e+19] "" Vector__XXX

BO_ 1012 LS_lightShow: 8 GTW
 SG_ LS_lightShowIndex M : 0|5@1+ (1,0) [0|31] "" Vector__XXX
 SG_ LS_lightLeftRampedChannel1Reques m0 : 5|1@1+ (1,0) [0|1] "" Vector__XXX
 SG_ LS_lightLeftRampedChannel1Durati m0 : 6|2@1+ (1,0) [0|3] "" Vector__XXX
 SG_ LS_lightLeftRampedChannel2Reques m0 : 8|1@1+ (1,0) [0|1] "" Vector__XXX
 SG_ LS_lightLeftRampedChannel2Durati m0 : 9|2@1+ (1,0) [0|3] "" Vector__XXX
 SG_ LS_lightLeftRampedChannel3Reques m0 : 11|1@1+ (1,0) [0|1] "" Vector__XXX
 SG_ LS_lightLeftRampedChannel3Durati m0 : 12|2@1+ (1,0) [0|3] "" Vector__XXX
 SG_ LS_lightLeftRampedChannel4Reques m0 : 14|1@1+ (1,0) [0|1] "" Vector__XXX
 SG_ LS_lightLeftRampedChannel4Durati m0 : 16|2@1+ (1,0) [0|3] "" Vector__XXX
 SG_ LS_lightLeftRampedChannel5Reques m0 : 18|1@1+ (1,0) [0|1] "" Vector__XXX
 SG_ LS_lightLeftRampedChannel5Durati m0 : 19|2@1+ (1,0) [0|3] "" Vector__XXX
 SG_ LS_lightLeftRampedChannel6Reques m0 : 21|1@1+ (1,0) [0|1] "" Vector__XXX
 SG_ LS_lightLeftRampedChannel6Durati m0 : 22|2@1+ (1,0) [0|3] "" Vector__XXX
 SG_ LS_lightLeftRampedChannel7Reques m0 : 24|1@1+ (1,0) [0|1] "" Vector__XXX
 SG_ LS_lightLeftRampedChannel7Durati m0 : 25|2@1+ (1,0) [0|3] "" Vector__XXX
 SG_ LS_lightRightRampedChannel1Reque m0 : 27|1@1+ (1,0) [0|1] "" Vector__XXX
 SG_ LS_lightRightRampedChannel1Durat m0 : 28|2@1+ (1,0) [0|3] "" Vector__XXX
 SG_ LS_lightRightRampedChannel2Reque m0 : 30|1@1+ (1,0) [0|1] "" Vector__XXX
 SG_ LS_lightRightRampedChannel2Durat m0 : 31|2@1+ (1,0) [0|3] "" Vector__XXX
 SG_ LS_lightRightRampedChannel3Reque m0 : 33|1@1+ (1,0) [0|1] "" Vector__XXX
 SG_ LS_lightRightRampedChannel3Durat m0 : 34|2@1+ (1,0) [0|3] "" Vector__XXX
 SG_ LS_lightRightRampedChannel4Reque m0 : 36|1@1+ (1,0) [0|1] "" Vector__XXX
 SG_ LS_lightRightRampedChannel4Durat m0 : 37|2@1+ (1,0) [0|3] "" Vector__XXX
 SG_ LS_lightRightRampedChannel5Reque m0 : 39|1@1+ (1,0) [0|1] "" Vector__XXX
 SG_ LS_lightRightRampedChannel5Durat m0 : 40|2@1+ (1,0) [0|3] "" Vector__XXX
 SG_ LS_lightRightRampedChannel6Reque m0 : 42|1@1+ (1,0) [0|1] "" Vector__XXX
 SG_ LS_lightRightRampedChannel6Durat m0 : 43|2@1+ (1,0) [0|3] "" Vector__XXX
 SG_ LS_lightRightRampedChannel7Reque m0 : 45|1@1+ (1,0) [0|1] "" Vector__XXX
 SG_ LS_lightRightRampedChannel7Durat m0 : 46|2@1+ (1,0) [0|3] "" Vector__XXX
 SG_ LS_lightRearTurnLeftRequest m0 : 48|1@1+ (1,0) [0|1] "" Vector__XXX
 SG_ LS_lightRearTurnRightRequest m0 : 49|1@1+ (1,0) [0|1] "" Vector__XXX
 SG_ LS_lightSideRepeaterLeftRequest m0 : 50|1@1+ (1,0) [0|1] "" Vector__XXX
 SG_ LS_lightSideRepeaterRightRequest m0 : 51|1@1+ (1,0) [0|1] "" Vector__XXX
 SG_ LS_lightSideMarkerLeftRequest m0 : 52|1@1+ (1,0) [0|1] "" Vector__XXX
 SG_ LS_lightSideMarkerRightRequest m0 : 53|1@1+ (1,0) [0|1] "" Vector__XXX
 SG_ LS_lightFrontFogLeftRequest m0 : 54|1@1+ (1,0) [0|1] "" Vector__XXX
 SG_ LS_lightFrontFogRightRequest m0 : 55|1@1+ (1,0) [0|1] "" Vector__XXX
 SG_ LS_lightRearFogRequest m0 : 56|1@1+ (1,0) [0|1] "" Vector__XXX
 SG_ LS_lightBrakeRequest m0 : 57|1@1+ (1,0) [0|1] "" Vector__XXX
 SG_ LS_lightTailLeftRequest m0 : 58|1@1+ (1,0) [0|1] "" Vector__XXX
 SG_ LS_lightTailRightRequest m0 : 59|1@1+ (1,0) [0|1] "" Vector__XXX
 SG_ LS_lightLicensePlateRequest m0 : 60|1@1+ (1,0) [0|1] "" Vector__XXX
 SG_ LS_lightReverseRequest m0 : 61|1@1+ (1,0) [0|1] "" Vector__XXX
 SG_ LS_lightAuxParkLeftRequest m0 : 62|1@1+ (1,0) [0|1] "" Vector__XXX
 SG_ LS_lightAuxParkRightRequest m0 : 63|1@1+ (1,0) [0|1] "" Vector__XXX
 SG_ LS_mirrorRequestLeft m1 : 5|3@1+ (1,0) [0|7] "" Vector__XXX
 SG_ LS_mirrorRequestRight m1 : 8|3@1+ (1,0) [0|7] "" Vector__XXX
 SG_ LS_liftgateRequest m1 : 11|3@1+ (1,0) [0|7] "" Vector__XXX
 SG_ LS_windowRequestLF m1 : 16|3@1+ (1,0) [0|7] "" Vector__XXX
 SG_ LS_windowRequestLR m1 : 19|3@1+ (1,0) [0|7] "" Vector__XXX
 SG_ LS_windowRequestRF m1 : 24|3@1+ (1,0) [0|7] "" Vector__XXX
 SG_ LS_windowRequestRR m1 : 27|3@1+ (1,0) [0|7] "" Vector__XXX
 SG_ LS_presentingHandleRequestLF m1 : 32|3@1+ (1,0) [0|7] "" Vector__XXX
 SG_ LS_presentingHandleRequestLR m1 : 35|3@1+ (1,0) [0|7] "" Vector__XXX
 SG_ LS_presentingHandleRequestRF m1 : 40|3@1+ (1,0) [0|7] "" Vector__XXX
 SG_ LS_presentingHandleRequestRR m1 : 43|3@1+ (1,0) [0|7] "" Vector__XXX
 SG_ LS_powerFrontDoorRequestLeft m1 : 46|3@1+ (1,0) [0|7] "" Vector__XXX
 SG_ LS_powerFrontDoorRequestRight m1 : 49|3@1+ (1,0) [0|7] "" Vector__XXX
 SG_ LS_falconDoorRequestLeft m1 : 52|3@1+ (1,0) [0|7] "" Vector__XXX
 SG_ LS_falconDoorRequestRight m1 : 55|3@1+ (1,0) [0|7] "" Vector__XXX
 SG_ LS_chargePortRequest m1 : 58|2@1+ (1,0) [0|2] "" Vector__XXX
 SG_ LS_chargePortRaveRequest m1 : 60|1@1+ (1,0) [0|1] "" Vector__XXX
 SG_ LS_suspensionRequest m1 : 61|2@1+ (1,0) [0|2] "" Vector__XXX
 SG_ LS_rgbIPFLRed m2 : 8|8@1+ (1,0) [0|255] "" Vector__XXX
 SG_ LS_rgbIPFLGreen m2 : 16|8@1+ (1,0) [0|255] "" Vector__XXX
 SG_ LS_rgbIPFLBlue m2 : 24|8@1+ (1,0) [0|255] "" Vector__XXX
 SG_ LS_rgbIPFRRed m2 : 32|8@1+ (1,0) [0|255] "" Vector__XXX
 SG_ LS_rgbIPFRGreen m2 : 40|8@1+ (1,0) [0|255] "" Vector__XXX
 SG_ LS_rgbIPFRBlue m2 : 48|8@1+ (1,0) [0|255] "" Vector__XXX
 SG_ LS_rgbDoorFLForeRed m3 : 8|8@1+ (1,0) [0|255] "" Vector__XXX
 SG_ LS_rgbDoorFLForeGreen m3 : 16|8@1+ (1,0) [0|255] "" Vector__XXX
 SG_ LS_rgbDoorFLForeBlue m3 : 24|8@1+ (1,0) [0|255] "" Vector__XXX
 SG_ LS_rgbDoorFLAftRed m3 : 32|8@1+ (1,0) [0|255] "" Vector__XXX
 SG_ LS_rgbDoorFLAftGreen m3 : 40|8@1+ (1,0) [0|255] "" Vector__XXX
 SG_ LS_rgbDoorFLAftBlue m3 : 48|8@1+ (1,0) [0|255] "" Vector__XXX
 SG_ LS_rgbDoorFRForeRed m4 : 8|8@1+ (1,0) [0|255] "" Vector__XXX
 SG_ LS_rgbDoorFRForeGreen m4 : 16|8@1+ (1,0) [0|255] "" Vector__XXX
 SG_ LS_rgbDoorFRForeBlue m4 : 24|8@1+ (1,0) [0|255] "" Vector__XXX
 SG_ LS_rgbDoorFRAftRed m4 : 32|8@1+ (1,0) [0|255] "" Vector__XXX
 SG_ LS_rgbDoorFRAftGreen m4 : 40|8@1+ (1,0) [0|255] "" Vector__XXX
 SG_ LS_rgbDoorFRAftBlue m4 : 48|8@1+ (1,0) [0|255] "" Vector__XXX
 SG_ LS_rgbDoorRLForeRed m5 : 8|8@1+ (1,0) [0|255] "" Vector__XXX
 SG_ LS_rgbDoorRLForeGreen m5 : 16|8@1+ (1,0) [0|255] "" Vector__XXX
 SG_ LS_rgbDoorRLForeBlue m5 : 24|8@1+ (1,0) [0|255] "" Vector__XXX
 SG_ LS_rgbDoorRLAftRed m5 : 32|8@1+ (1,0) [0|255] "" Vector__XXX
 SG_ LS_rgbDoorRLAftGreen m5 : 40|8@1+ (1,0) [0|255] "" Vector__XXX
 SG_ LS_rgbDoorRLAftBlue m5 : 48|8@1+ (1,0) [0|255] "" Vector__XXX
 SG_ LS_rgbDoorRRForeRed m6 : 8|8@1+ (1,0) [0|255] "" Vector__XXX
 SG_ LS_rgbDoorRRForeGreen m6 : 16|8@1+ (1,0) [0|255] "" Vector__XXX
 SG_ LS_rgbDoorRRForeBlue m6 : 24|8@1+ (1,0) [0|255] "" Vector__XXX
 SG_ LS_rgbDoorRRAftRed m6 : 32|8@1+ (1,0) [0|255] "" Vector__XXX
 SG_ LS_rgbDoorRRAftGreen m6 : 40|8@1+ (1,0) [0|255] "" Vector__XXX
 SG_ LS_rgbDoorRRAftBlue m6 : 48|8@1+ (1,0) [0|255] "" Vector__XXX
 SG_ LS_frontMatrix0 m7 : 8|8@1+ (1,0) [0|255] "" Vector__XXX
 SG_ LS_frontMatrix1 m7 : 16|8@1+ (1,0) [0|255] "" Vector__XXX
 SG_ LS_frontMatrix2 m7 : 24|8@1+ (1,0) [0|255] "" Vector__XXX
 SG_ LS_frontMatrix3 m7 : 32|8@1+ (1,0) [0|255] "" Vector__XXX
 SG_ LS_frontMatrix4 m7 : 40|8@1+ (1,0) [0|255] "" Vector__XXX
 SG_ LS_frontMatrix5 m7 : 48|8@1+ (1,0) [0|255] "" Vector__XXX
 SG_ LS_frontMatrix6 m7 : 56|8@1+ (1,0) [0|255] "" Vector__XXX
 SG_ LS_frontMatrix7 m8 : 8|8@1+ (1,0) [0|255] "" Vector__XXX
 SG_ LS_frontMatrix8 m8 : 16|8@1+ (1,0) [0|255] "" Vector__XXX
 SG_ LS_frontMatrix9 m8 : 24|8@1+ (1,0) [0|255] "" Vector__XXX
 SG_ LS_frontMatrix10 m8 : 32|8@1+ (1,0) [0|255] "" Vector__XXX
 SG_ LS_frontMatrix11 m8 : 40|8@1+ (1,0) [0|255] "" Vector__XXX
 SG_ LS_frontMatrix12 m8 : 48|8@1+ (1,0) [0|255] "" Vector__XXX
 SG_ LS_frontMatrix13 m8 : 56|8@1+ (1,0) [0|255] "" Vector__XXX
 SG_ LS_frontMatrix14 m9 : 8|8@1+ (1,0) [0|255] "" Vector__XXX
 SG_ LS_frontMatrix15 m9 : 16|8@1+ (1,0) [0|255] "" Vector__XXX
 SG_ LS_frontMatrix16 m9 : 24|8@1+ (1,0) [0|255] "" Vector__XXX
 SG_ LS_frontMatrix17 m9 : 32|8@1+ (1,0) [0|255] "" Vector__XXX
 SG_ LS_frontMatrix18 m9 : 40|8@1+ (1,0) [0|255] "" Vector__XXX
 SG_ LS_frontMatrix19 m9 : 48|8@1+ (1,0) [0|255] "" Vector__XXX
 SG_ LS_frontMatrix20 m9 : 56|8@1+ (1,0) [0|255] "" Vector__XXX
 SG_ LS_frontMatrix21 m10 : 8|8@1+ (1,0) [0|255] "" Vector__XXX
 SG_ LS_frontMatrix22 m10 : 16|8@1+ (1,0) [0|255] "" Vector__XXX
 SG_ LS_frontMatrix23 m10 : 24|8@1+ (1,0) [0|255] "" Vector__XXX
 SG_ LS_frontMatrix24 m10 : 32|8@1+ (1,0) [0|255] "" Vector__XXX
 SG_ LS_frontMatrix25 m10 : 40|8@1+ (1,0) [0|255] "" Vector__XXX
 SG_ LS_frontMatrix26 m10 : 48|8@1+ (1,0) [0|255] "" Vector__XXX
 SG_ LS_frontMatrix27 m10 : 56|8@1+ (1,0) [0|255] "" Vector__XXX
 SG_ LS_frontMatrix28 m11 : 8|8@1+ (1,0) [0|255] "" Vector__XXX
 SG_ LS_frontMatrix29 m11 : 16|8@1+ (1,0) [0|255] "" Vector__XXX
 SG_ LS_frontMatrix30 m11 : 24|8@1+ (1,0) [0|255] "" Vector__XXX
 SG_ LS_frontMatrix31 m11 : 32|8@1+ (1,0) [0|255] "" Vector__XXX
 SG_ LS_frontMatrix32 m11 : 40|8@1+ (1,0) [0|255] "" Vector__XXX
 SG_ LS_frontMatrix33 m11 : 48|8@1+ (1,0) [0|255] "" Vector__XXX
 SG_ LS_frontMatrix34 m11 : 56|8@1+ (1,0) [0|255] "" Vector__XXX
 SG_ LS_frontMatrix35 m12 : 8|8@1+ (1,0) [0|255] "" Vector__XXX
 SG_ LS_frontMatrix36 m12 : 16|8@1+ (1,0) [0|255] "" Vector__XXX
 SG_ LS_frontMatrix37 m12 : 24|8@1+ (1,0) [0|255] "" Vector__XXX
 SG_ LS_frontMatrix38 m12 : 32|8@1+ (1,0) [0|255] "" Vector__XXX
 SG_ LS_frontMatrix39 m12 : 40|8@1+ (1,0) [0|255] "" Vector__XXX
 SG_ LS_frontMatrix40 m12 : 48|8@1+ (1,0) [0|255] "" Vector__XXX
 SG_ LS_frontMatrix41 m12 : 56|8@1+ (1,0) [0|255] "" Vector__XXX
 SG_ LS_frontMatrix42 m13 : 8|8@1+ (1,0) [0|255] "" Vector__XXX
 SG_ LS_frontMatrix43 m13 : 16|8@1+ (1,0) [0|255] "" Vector__XXX
 SG_ LS_frontMatrix44 m13 : 24|8@1+ (1,0) [0|255] "" Vector__XXX
 SG_ LS_frontMatrix45 m13 : 32|8@1+ (1,0) [0|255] "" Vector__XXX
 SG_ LS_frontMatrix46 m13 : 40|8@1+ (1,0) [0|255] "" Vector__XXX
 SG_ LS_frontMatrix47 m13 : 48|8@1+ (1,0) [0|255] "" Vector__XXX
 SG_ LS_frontMatrix48 m13 : 56|8@1+ (1,0) [0|255] "" Vector__XXX
 SG_ LS_frontMatrix49 m14 : 8|8@1+ (1,0) [0|255] "" Vector__XXX
 SG_ LS_frontMatrix50 m14 : 16|8@1+ (1,0) [0|255] "" Vector__XXX
 SG_ LS_frontMatrix51 m14 : 24|8@1+ (1,0) [0|255] "" Vector__XXX
 SG_ LS_frontMatrix52 m14 : 32|8@1+ (1,0) [0|255] "" Vector__XXX
 SG_ LS_frontMatrix53 m14 : 40|8@1+ (1,0) [0|255] "" Vector__XXX
 SG_ LS_frontMatrix54 m14 : 48|8@1+ (1,0) [0|255] "" Vector__XXX
 SG_ LS_frontMatrix55 m14 : 56|8@1+ (1,0) [0|255] "" Vector__XXX
 SG_ LS_frontMatrix56 m15 : 8|8@1+ (1,0) [0|255] "" Vector__XXX
 SG_ LS_frontMatrix57 m15 : 16|8@1+ (1,0) [0|255] "" Vector__XXX
 SG_ LS_frontMatrix58 m15 : 24|8@1+ (1,0) [0|255] "" Vector__XXX
 SG_ LS_frontMatrix59 m15 : 32|8@1+ (1,0) [0|255] "" Vector__XXX
 SG_ LS_rearMatrix0 m15 : 40|8@1+ (1,0) [0|255] "" Vector__XXX
 SG_ LS_rearMatrix1 m15 : 48|8@1+ (1,0) [0|255] "" Vector__XXX
 SG_ LS_rearMatrix2 m15 : 56|8@1+ (1,0) [0|255] "" Vector__XXX
 SG_ LS_rearMatrix3 m16 : 8|8@1+ (1,0) [0|255] "" Vector__XXX
 SG_ LS_rearMatrix4 m16 : 16|8@1+ (1,0) [0|255] "" Vector__XXX
 SG_ LS_rearMatrix5 m16 : 24|8@1+ (1,0) [0|255] "" Vector__XXX
 SG_ LS_rearMatrix6 m16 : 32|8@1+ (1,0) [0|255] "" Vector__XXX
 SG_ LS_rearMatrix7 m16 : 40|8@1+ (1,0) [0|255] "" Vector__XXX
 SG_ LS_rearMatrix8 m16 : 48|8@1+ (1,0) [0|255] "" Vector__XXX
 SG_ LS_rearMatrix9 m16 : 56|8@1+ (1,0) [0|255] "" Vector__XXX
 SG_ LS_rearMatrix10 m17 : 8|8@1+ (1,0) [0|255] "" Vector__XXX
 SG_ LS_rearMatrix11 m17 : 16|8@1+ (1,0) [0|255] "" Vector__XXX
 SG_ LS_rearMatrix12 m17 : 24|8@1+ (1,0) [0|255] "" Vector__XXX
 SG_ LS_rearMatrix13 m17 : 32|8@1+ (1,0) [0|255] "" Vector__XXX
 SG_ LS_rearMatrix14 m17 : 40|8@1+ (1,0) [0|255] "" Vector__XXX
 SG_ LS_rearMatrix15 m17 : 48|8@1+ (1,0) [0|255] "" Vector__XXX
 SG_ LS_rearMatrix16 m17 : 56|8@1+ (1,0) [0|255] "" Vector__XXX
 SG_ LS_rearMatrix17 m18 : 8|8@1+ (1,0) [0|255] "" Vector__XXX
 SG_ LS_rearMatrix18 m18 : 16|8@1+ (1,0) [0|255] "" Vector__XXX
 SG_ LS_rearMatrix19 m18 : 24|8@1+ (1,0) [0|255] "" Vector__XXX
 SG_ LS_rearMatrix20 m18 : 32|8@1+ (1,0) [0|255] "" Vector__XXX
 SG_ LS_rearMatrix21 m18 : 40|8@1+ (1,0) [0|255] "" Vector__XXX
 SG_ LS_rearMatrix22 m18 : 48|8@1+ (1,0) [0|255] "" Vector__XXX
 SG_ LS_rearMatrix23 m18 : 56|8@1+ (1,0) [0|255] "" Vector__XXX
 SG_ LS_rearMatrix24 m19 : 8|8@1+ (1,0) [0|255] "" Vector__XXX
 SG_ LS_rearMatrix25 m19 : 16|8@1+ (1,0) [0|255] "" Vector__XXX
 SG_ LS_rearMatrix26 m19 : 24|8@1+ (1,0) [0|255] "" Vector__XXX
 SG_ LS_rearMatrix27 m19 : 32|8@1+ (1,0) [0|255] "" Vector__XXX
 SG_ LS_rearMatrix28 m19 : 40|8@1+ (1,0) [0|255] "" Vector__XXX
 SG_ LS_rearMatrix29 m19 : 48|8@1+ (1,0) [0|255] "" Vector__XXX
 SG_ LS_rearMatrix30 m19 : 56|8@1+ (1,0) [0|255] "" Vector__XXX
 SG_ LS_rearMatrix31 m20 : 8|8@1+ (1,0) [0|255] "" Vector__XXX
 SG_ LS_rearMatrix32 m20 : 16|8@1+ (1,0) [0|255] "" Vector__XXX
 SG_ LS_rearMatrix33 m20 : 24|8@1+ (1,0) [0|255] "" Vector__XXX
 SG_ LS_rearMatrix34 m20 : 32|8@1+ (1,0) [0|255] "" Vector__XXX
 SG_ LS_rearMatrix35 m20 : 40|8@1+ (1,0) [0|255] "" Vector__XXX
 SG_ LS_rearMatrix36 m20 : 48|8@1+ (1,0) [0|255] "" Vector__XXX
 SG_ LS_rearMatrix37 m20 : 56|8@1+ (1,0) [0|255] "" Vector__XXX
 SG_ LS_rearMatrix38 m21 : 8|8@1+ (1,0) [0|255] "" Vector__XXX
 SG_ LS_rearMatrix39 m21 : 16|8@1+ (1,0) [0|255] "" Vector__XXX
 SG_ LS_rearMatrix40 m21 : 24|8@1+ (1,0) [0|255] "" Vector__XXX
 SG_ LS_rearMatrix41 m21 : 32|8@1+ (1,0) [0|255] "" Vector__XXX
 SG_ LS_rearMatrix42 m21 : 40|8@1+ (1,0) [0|255] "" Vector__XXX
 SG_ LS_rearMatrix43 m21 : 48|8@1+ (1,0) [0|255] "" Vector__XXX
 SG_ LS_rearMatrix44 m21 : 56|8@1+ (1,0) [0|255] "" Vector__XXX
 SG_ LS_rearMatrix45 m22 : 8|8@1+ (1,0) [0|255] "" Vector__XXX
 SG_ LS_rearMatrix46 m22 : 16|8@1+ (1,0) [0|255] "" Vector__XXX
 SG_ LS_rearMatrix47 m22 : 24|8@1+ (1,0) [0|255] "" Vector__XXX
 SG_ LS_rearMatrix48 m22 : 32|8@1+ (1,0) [0|255] "" Vector__XXX
 SG_ LS_rearMatrix49 m22 : 40|8@1+ (1,0) [0|255] "" Vector__XXX
 SG_ LS_rearMatrix50 m22 : 48|8@1+ (1,0) [0|255] "" Vector__XXX
 SG_ LS_rearMatrix51 m22 : 56|8@1+ (1,0) [0|255] "" Vector__XXX
 SG_ LS_rearMatrix52 m23 : 8|8@1+ (1,0) [0|255] "" Vector__XXX
 SG_ LS_rearMatrix53 m23 : 16|8@1+ (1,0) [0|255] "" Vector__XXX
 SG_ LS_rearMatrix54 m23 : 24|8@1+ (1,0) [0|255] "" Vector__XXX
 SG_ LS_rearMatrix55 m23 : 32|8@1+ (1,0) [0|255] "" Vector__XXX
 SG_ LS_rearMatrix56 m23 : 40|8@1+ (1,0) [0|255] "" Vector__XXX
 SG_ LS_rearMatrix57 m23 : 48|8@1+ (1,0) [0|255] "" Vector__XXX
 SG_ LS_rearMatrix58 m23 : 56|8@1+ (1,0) [0|255] "" Vector__XXX
 SG_ LS_rearMatrix59 m24 : 8|8@1+ (1,0) [0|255] "" Vector__XXX
 SG_ LS_offroadLightBar0 m24 : 16|8@1+ (1,0) [0|255] "" Vector__XXX
 SG_ LS_offroadLightBar1 m24 : 24|8@1+ (1,0) [0|255] "" Vector__XXX
 SG_ LS_offroadLightBar2 m24 : 32|8@1+ (1,0) [0|255] "" Vector__XXX
 SG_ LS_offroadLightBar3 m24 : 40|8@1+ (1,0) [0|255] "" Vector__XXX
 SG_ LS_offroadLightBar4 m24 : 48|8@1+ (1,0) [0|255] "" Vector__XXX
 SG_ LS_offroadLightBar5 m24 : 56|8@1+ (1,0) [0|255] "" Vector__XXX

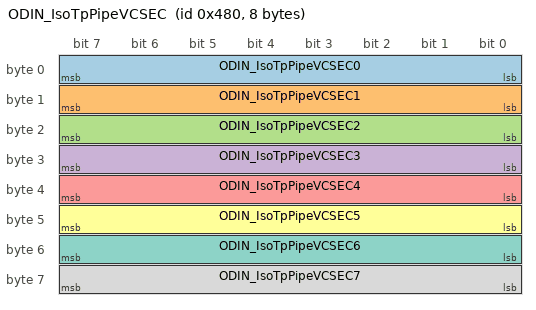
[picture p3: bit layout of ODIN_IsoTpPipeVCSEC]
BO_ 1152 ODIN_IsoTpPipeVCSEC: 8 GTW
 SG_ ODIN_IsoTpPipeVCSEC0 : 7|8@0+ (1,0) [0|255] "" Vector__XXX
 SG_ ODIN_IsoTpPipeVCSEC1 : 15|8@0+ (1,0) [0|255] "" Vector__XXX
 SG_ ODIN_IsoTpPipeVCSEC2 : 23|8@0+ (1,0) [0|255] "" Vector__XXX
 SG_ ODIN_IsoTpPipeVCSEC3 : 31|8@0+ (1,0) [0|255] "" Vector__XXX
 SG_ ODIN_IsoTpPipeVCSEC4 : 39|8@0+ (1,0) [0|255] "" Vector__XXX
 SG_ ODIN_IsoTpPipeVCSEC5 : 47|8@0+ (1,0) [0|255] "" Vector__XXX
 SG_ ODIN_IsoTpPipeVCSEC6 : 55|8@0+ (1,0) [0|255] "" Vector__XXX
 SG_ ODIN_IsoTpPipeVCSEC7 : 63|8@0+ (1,0) [0|255] "" Vector__XXX

BO_TX_BU_ 1290 : HVP;
BO_TX_BU_ 938 : HVP;
BO_TX_BU_ 522 : HVP;
BO_TX_BU_ 1962 : HVP;
BO_TX_BU_ 1666 : HVP;
BO_TX_BU_ 554 : HVP;
BO_TX_BU_ 784 : HVP;
BO_TX_BU_ 1914 : HVP;
BO_TX_BU_ 1553 : HVP;
BO_TX_BU_ 1208 : ICR;
BO_TX_BU_ 952 : ICR;
BO_TX_BU_ 941 : ICR;
BO_TX_BU_ 667 : ICR;
BO_TX_BU_ 536 : ICR;
BO_TX_BU_ 670 : ICR;
BO_TX_BU_ 664 : ICR;
BO_TX_BU_ 1624 : ICR;
BO_TX_BU_ 1012 : GTW;
BO_TX_BU_ 1152 : GTW;
CM_ BO_ 1290 "High-voltage processor (pack contactor and isolation controller) message: alert log; frame length from the layout, not yet observed on a vehicle bus";
CM_ SG_ 1290 HVP_alertID "High-voltage processor (pack contactor and isolation controller): alert ID";
CM_ SG_ 1290 HVP_alertSet "High-voltage processor (pack contactor and isolation controller): alert set";
CM_ SG_ 1290 HVP_a005_current "High-voltage processor (pack contactor and isolation controller): a005 current";
CM_ SG_ 1290 HVP_a006_current "High-voltage processor (pack contactor and isolation controller): a006 current";
CM_ SG_ 1290 HVP_a007_current "High-voltage processor (pack contactor and isolation controller): a007 current";
CM_ SG_ 1290 HVP_a008_temperature "High-voltage processor (pack contactor and isolation controller): a008 temperature";
CM_ SG_ 1290 HVP_a008_sensorId "High-voltage processor (pack contactor and isolation controller): a008 sensor id";
CM_ SG_ 1290 HVP_a008_primaryChainSensor "High-voltage processor (pack contactor and isolation controller): a008 primary chain sensor";
CM_ SG_ 1290 HVP_a009_brickVoltage "High-voltage processor (pack contactor and isolation controller): a009 brick voltage";
CM_ SG_ 1290 HVP_a009_brickId "High-voltage processor (pack contactor and isolation controller): a009 brick id";
CM_ SG_ 1290 HVP_a009_primaryChainSensor "High-voltage processor (pack contactor and isolation controller): a009 primary chain sensor";
CM_ SG_ 1290 HVP_a010_brickVoltage "High-voltage processor (pack contactor and isolation controller): a010 brick voltage";
CM_ SG_ 1290 HVP_a010_brickId "High-voltage processor (pack contactor and isolation controller): a010 brick id";
CM_ SG_ 1290 HVP_a010_primaryChainSensor "High-voltage processor (pack contactor and isolation controller): a010 primary chain sensor";
CM_ SG_ 1290 HVP_a012_breakLocationA "High-voltage processor (pack contactor and isolation controller): a012 break location a";
CM_ SG_ 1290 HVP_a012_bmbCommStatusTypeA "High-voltage processor (pack contactor and isolation controller): a012 bmb comm status type a";
CM_ SG_ 1290 HVP_a012_breakLocationB "High-voltage processor (pack contactor and isolation controller): a012 break location b";
CM_ SG_ 1290 HVP_a012_bmbCommStatusTypeB "High-voltage processor (pack contactor and isolation controller): a012 bmb comm status type b";
CM_ SG_ 1290 HVP_a013_breakLocationA "High-voltage processor (pack contactor and isolation controller): a013 break location a";
CM_ SG_ 1290 HVP_a013_bmbCommStatusTypeA "High-voltage processor (pack contactor and isolation controller): a013 bmb comm status type a";
CM_ SG_ 1290 HVP_a013_breakLocationB "High-voltage processor (pack contactor and isolation controller): a013 break location b";
CM_ SG_ 1290 HVP_a013_bmbCommStatusTypeB "High-voltage processor (pack contactor and isolation controller): a013 bmb comm status type b";
CM_ SG_ 1290 HVP_a013_bmbChainBreakType "High-voltage processor (pack contactor and isolation controller): a013 bmb chain break type";
CM_ SG_ 1290 HVP_a018_dcLinkVoltage "High-voltage processor (pack contactor and isolation controller): a018 dc link voltage";
CM_ SG_ 1290 HVP_a018_battery12V "High-voltage processor (pack contactor and isolation controller): a018 battery12 v";
CM_ SG_ 1290 HVP_a018_remainingPcsPowerCycles "High-voltage processor (pack contactor and isolation controller): a018 remaining pcs power cycles allowed";
CM_ SG_ 1290 HVP_a018_remainingPcsRecoveriesA "High-voltage processor (pack contactor and isolation controller): a018 remaining pcs recoveries allowed";
CM_ SG_ 1290 HVP_a018_hvcHardwareSupportsCycl "High-voltage processor (pack contactor and isolation controller): a018 hvc hardware supports cycling";
CM_ SG_ 1290 HVP_a018_pcsHardwareOkToBePowerC "High-voltage processor (pack contactor and isolation controller): a018 pcs hardware ok to be power cycled";
CM_ SG_ 1290 HVP_a018_gpioLogicPowerEnable "High-voltage processor (pack contactor and isolation controller): a018 gpio logic power enable";
CM_ SG_ 1290 HVP_a018_gpioDcDcEnable "High-voltage processor (pack contactor and isolation controller): a018 gpio dc dc enable";
CM_ SG_ 1290 HVP_a018_gpioChgEnable "High-voltage processor (pack contactor and isolation controller): a018 gpio chg enable";
CM_ SG_ 1290 HVP_a020_energyReserveV "High-voltage processor (pack contactor and isolation controller): a020 energy reserve v; raw 65535 = signal not available (SNA)";
CM_ SG_ 1290 HVP_a020_shuntCurrentAux "High-voltage processor (pack contactor and isolation controller): a020 shunt current aux; raw 32768 = signal not available (SNA)";
CM_ SG_ 1290 HVP_a020_shuntTemperature "High-voltage processor (pack contactor and isolation controller): a020 shunt temperature; raw 32768 = signal not available (SNA)";
CM_ SG_ 1290 HVP_a021_pyroStatus "High-voltage processor (pack contactor and isolation controller): a021 pyro status";
CM_ SG_ 1290 HVP_a021_ErTestFailed "High-voltage processor (pack contactor and isolation controller): a021 er test failed";
CM_ SG_ 1290 HVP_a021_HighSideSwitchTestFaile "High-voltage processor (pack contactor and isolation controller): a021 high side switch test failed";
CM_ SG_ 1290 HVP_a021_LowSideSwitchTestFailed "High-voltage processor (pack contactor and isolation controller): a021 low side switch test failed";
CM_ SG_ 1290 HVP_a021_RefCurrentTestFailed "High-voltage processor (pack contactor and isolation controller): a021 ref current test failed";
CM_ SG_ 1290 HVP_a021_PyroLeakTestFailed "High-voltage processor (pack contactor and isolation controller): a021 pyro leak test failed";
CM_ SG_ 1290 HVP_a021_SquibResTestFailed "High-voltage processor (pack contactor and isolation controller): a021 squib res test failed";
CM_ SG_ 1290 HVP_a021_VstTestFailed "High-voltage processor (pack contactor and isolation controller): a021 vst test failed";
CM_ SG_ 1290 HVP_a021_SquibResistance "High-voltage processor (pack contactor and isolation controller): a021 squib resistance; raw 65535 = signal not available (SNA)";
CM_ SG_ 1290 HVP_a021_OneShotSequence "High-voltage processor (pack contactor and isolation controller): a021 one shot sequence";
CM_ SG_ 1290 HVP_a021_HighSide "High-voltage processor (pack contactor and isolation controller): a021 high side";
CM_ SG_ 1290 HVP_a021_LowSide "High-voltage processor (pack contactor and isolation controller): a021 low side";
CM_ SG_ 1290 HVP_a021_Aout "High-voltage processor (pack contactor and isolation controller): a021 aout; raw 16383 = signal not available (SNA)";
CM_ SG_ 1290 HVP_a022_pyroStatus "High-voltage processor (pack contactor and isolation controller): a022 pyro status";
CM_ SG_ 1290 HVP_a022_PyroLeakTestFailed "High-voltage processor (pack contactor and isolation controller): a022 pyro leak test failed";
CM_ SG_ 1290 HVP_a022_OneShotSequence "High-voltage processor (pack contactor and isolation controller): a022 one shot sequence";
CM_ SG_ 1290 HVP_a022_HighSide "High-voltage processor (pack contactor and isolation controller): a022 high side";
CM_ SG_ 1290 HVP_a022_LowSide "High-voltage processor (pack contactor and isolation controller): a022 low side";
CM_ SG_ 1290 HVP_a022_Aout "High-voltage processor (pack contactor and isolation controller): a022 aout; raw 16383 = signal not available (SNA)";
CM_ SG_ 1290 HVP_a022_SquibResistance "High-voltage processor (pack contactor and isolation controller): a022 squib resistance; raw 65535 = signal not available (SNA)";
CM_ SG_ 1290 HVP_a024_voltage "High-voltage processor (pack contactor and isolation controller): a024 voltage";
CM_ SG_ 1290 HVP_a025_voltage1 "High-voltage processor (pack contactor and isolation controller): a025 voltage1";
CM_ SG_ 1290 HVP_a025_voltage2 "High-voltage processor (pack contactor and isolation controller): a025 voltage2";
CM_ SG_ 1290 HVP_a025_packVoltage "High-voltage processor (pack contactor and isolation controller): a025 pack voltage";
CM_ SG_ 1290 HVP_a026_hvilStatus "High-voltage processor (pack contactor and isolation controller): a026 hvil status; raw 14 = signal not available (SNA)";
CM_ SG_ 1290 HVP_a026_inputVoltage "High-voltage processor (pack contactor and isolation controller): a026 input voltage";
CM_ SG_ 1290 HVP_a026_outputVoltage "High-voltage processor (pack contactor and isolation controller): a026 output voltage";
CM_ SG_ 1290 HVP_a026_internalVoltage "High-voltage processor (pack contactor and isolation controller): a026 internal voltage; raw 255 = signal not available (SNA)";
CM_ SG_ 1290 HVP_a026_dirVoltage "High-voltage processor (pack contactor and isolation controller): a026 dir voltage; raw 255 = signal not available (SNA)";
CM_ SG_ 1290 HVP_a026_difVoltage "High-voltage processor (pack contactor and isolation controller): a026 dif voltage; raw 255 = signal not available (SNA)";
CM_ SG_ 1290 HVP_a028_packVoltage "High-voltage processor (pack contactor and isolation controller): a028 pack voltage";
CM_ SG_ 1290 HVP_a028_sumOfBrickV "High-voltage processor (pack contactor and isolation controller): a028 sum of brick v";
CM_ SG_ 1290 HVP_a030_packPositiveLinkV "High-voltage processor (pack contactor and isolation controller): a030 pack positive link v";
CM_ SG_ 1290 HVP_a030_dcPositiveLinkV "High-voltage processor (pack contactor and isolation controller): a030 dc positive link v";
CM_ SG_ 1290 HVP_a031_packNegativeLinkV "High-voltage processor (pack contactor and isolation controller): a031 pack negative link v";
CM_ SG_ 1290 HVP_a031_dcNegativeLinkV "High-voltage processor (pack contactor and isolation controller): a031 dc negative link v";
CM_ SG_ 1290 HVP_a033_contactorPowerV "High-voltage processor (pack contactor and isolation controller): a033 contactor power v";
CM_ SG_ 1290 HVP_a033_coilCurrent "High-voltage processor (pack contactor and isolation controller): a033 coil current";
CM_ SG_ 1290 HVP_a033_pwmDutyCylePositive "High-voltage processor (pack contactor and isolation controller): a033 pwm duty cyle positive";
CM_ SG_ 1290 HVP_a033_pwmDutyCyleNegative "High-voltage processor (pack contactor and isolation controller): a033 pwm duty cyle negative";
CM_ SG_ 1290 HVP_a035_contactorPowerV "High-voltage processor (pack contactor and isolation controller): a035 contactor power v";
CM_ SG_ 1290 HVP_a035_coilCurrent "High-voltage processor (pack contactor and isolation controller): a035 coil current";
CM_ SG_ 1290 HVP_a035_pwmDutyCylePositive "High-voltage processor (pack contactor and isolation controller): a035 pwm duty cyle positive";
CM_ SG_ 1290 HVP_a035_pwmDutyCyleNegative "High-voltage processor (pack contactor and isolation controller): a035 pwm duty cyle negative";
CM_ SG_ 1290 HVP_a036_pyroFiringHandle "High-voltage processor (pack contactor and isolation controller): a036 pyro firing handle";
CM_ SG_ 1290 HVP_a036_pyroFiringTime "High-voltage processor (pack contactor and isolation controller): a036 pyro firing time";
CM_ SG_ 1290 HVP_a036_pyroFiringAttempt "High-voltage processor (pack contactor and isolation controller): a036 pyro firing attempt";
CM_ SG_ 1290 HVP_a037_pyroFiringHandle "High-voltage processor (pack contactor and isolation controller): a037 pyro firing handle";
CM_ SG_ 1290 HVP_a039_posContactorFailed "High-voltage processor (pack contactor and isolation controller): a039 pos contactor failed";
CM_ SG_ 1290 HVP_a039_negContactorFailed "High-voltage processor (pack contactor and isolation controller): a039 neg contactor failed";
CM_ SG_ 1290 HVP_a040_powerVoltage "High-voltage processor (pack contactor and isolation controller): a040 power voltage";
CM_ SG_ 1290 HVP_a040_coilCurrent "High-voltage processor (pack contactor and isolation controller): a040 coil current";
CM_ SG_ 1290 HVP_a040_posCtrVoltageDrop "High-voltage processor (pack contactor and isolation controller): a040 pos ctr voltage drop";
CM_ SG_ 1290 HVP_a040_negCtrVoltageDrop "High-voltage processor (pack contactor and isolation controller): a040 neg ctr voltage drop";
CM_ SG_ 1290 HVP_a040_posCtrAuxOpen "High-voltage processor (pack contactor and isolation controller): a040 pos ctr aux open";
CM_ SG_ 1290 HVP_a040_negCtrAuxOpen "High-voltage processor (pack contactor and isolation controller): a040 neg ctr aux open";
CM_ SG_ 1290 HVP_a041_overCurrent "High-voltage processor (pack contactor and isolation controller): a041 over current";
CM_ SG_ 1290 HVP_a041_overChargeCurrent "High-voltage processor (pack contactor and isolation controller): a041 over charge current";
CM_ SG_ 1290 HVP_a041_overDischargeCurrent "High-voltage processor (pack contactor and isolation controller): a041 over discharge current";
CM_ SG_ 1290 HVP_a041_overVoltage "High-voltage processor (pack contactor and isolation controller): a041 over voltage";
CM_ SG_ 1290 HVP_a041_overTemperature "High-voltage processor (pack contactor and isolation controller): a041 over temperature";
CM_ SG_ 1290 HVP_a041_underVoltage "High-voltage processor (pack contactor and isolation controller): a041 under voltage";
CM_ SG_ 1290 HVP_a041_crashEvent "High-voltage processor (pack contactor and isolation controller): a041 crash event";
CM_ SG_ 1290 HVP_a041_packContactorHw "High-voltage processor (pack contactor and isolation controller): a041 pack contactor hw";
CM_ SG_ 1290 HVP_a041_notAllowedtoEnergize "High-voltage processor (pack contactor and isolation controller): a041 not allowedto energize";
CM_ SG_ 1290 HVP_a041_bmbMia "High-voltage processor (pack contactor and isolation controller): a041 bmb mia";
CM_ SG_ 1290 HVP_a041_hvilFault "High-voltage processor (pack contactor and isolation controller): a041 hvil fault";
CM_ SG_ 1290 HVP_a041_contactorStateWelded "High-voltage processor (pack contactor and isolation controller): a041 contactor state welded";
CM_ SG_ 1290 HVP_a041_shuntHwMia "High-voltage processor (pack contactor and isolation controller): a041 shunt hw mia";
CM_ SG_ 1290 HVP_a041_shuntCurrentMia "High-voltage processor (pack contactor and isolation controller): a041 shunt current mia";
CM_ SG_ 1290 HVP_a041_packVoltageMismatch "High-voltage processor (pack contactor and isolation controller): a041 pack voltage mismatch";
CM_ SG_ 1290 HVP_a041_gpoRequestActive "High-voltage processor (pack contactor and isolation controller): a041 gpo request active";
CM_ SG_ 1290 HVP_a041_fcContactorClosing "High-voltage processor (pack contactor and isolation controller): a041 fc contactor closing";
CM_ SG_ 1290 HVP_a041_fcContactorOpening "High-voltage processor (pack contactor and isolation controller): a041 fc contactor opening";
CM_ SG_ 1290 HVP_a041_resetRequestRequired "High-voltage processor (pack contactor and isolation controller): a041 reset request required";
CM_ SG_ 1290 HVP_a041_pyroFault "High-voltage processor (pack contactor and isolation controller): a041 pyro fault";
CM_ SG_ 1290 HVP_a041_dcLinkOverVoltage "High-voltage processor (pack contactor and isolation controller): a041 dc link over voltage";
CM_ SG_ 1290 HVP_a042_overCurrent "High-voltage processor (pack contactor and isolation controller): a042 over current";
CM_ SG_ 1290 HVP_a042_overChargeCurrent "High-voltage processor (pack contactor and isolation controller): a042 over charge current";
CM_ SG_ 1290 HVP_a042_overDischargeCurrent "High-voltage processor (pack contactor and isolation controller): a042 over discharge current";
CM_ SG_ 1290 HVP_a042_overVoltage "High-voltage processor (pack contactor and isolation controller): a042 over voltage";
CM_ SG_ 1290 HVP_a042_overTemperature "High-voltage processor (pack contactor and isolation controller): a042 over temperature";
CM_ SG_ 1290 HVP_a042_crashEvent "High-voltage processor (pack contactor and isolation controller): a042 crash event";
CM_ SG_ 1290 HVP_a042_fcContactorHw "High-voltage processor (pack contactor and isolation controller): a042 fc contactor hw";
CM_ SG_ 1290 HVP_a042_notAllowedtoEnergize "High-voltage processor (pack contactor and isolation controller): a042 not allowedto energize";
CM_ SG_ 1290 HVP_a042_bmsHvsMia "High-voltage processor (pack contactor and isolation controller): a042 bms hvs mia";
CM_ SG_ 1290 HVP_a042_cpMia "High-voltage processor (pack contactor and isolation controller): a042 cp mia";
CM_ SG_ 1290 HVP_a042_cpFault "High-voltage processor (pack contactor and isolation controller): a042 cp fault";
CM_ SG_ 1290 HVP_a042_supply12V "High-voltage processor (pack contactor and isolation controller): a042 supply12 v";
CM_ SG_ 1290 HVP_a042_supplyVer "High-voltage processor (pack contactor and isolation controller): a042 supply ver";
CM_ SG_ 1290 HVP_a042_packVoltageMismatch "High-voltage processor (pack contactor and isolation controller): a042 pack voltage mismatch";
CM_ SG_ 1290 HVP_a042_hvilFault "High-voltage processor (pack contactor and isolation controller): a042 hvil fault";
CM_ SG_ 1290 HVP_a042_contactorStateWelded "High-voltage processor (pack contactor and isolation controller): a042 contactor state welded";
CM_ SG_ 1290 HVP_a042_shuntHwMia "High-voltage processor (pack contactor and isolation controller): a042 shunt hw mia";
CM_ SG_ 1290 HVP_a042_shuntCurrentMia "High-voltage processor (pack contactor and isolation controller): a042 shunt current mia";
CM_ SG_ 1290 HVP_a042_packContactorClosing "High-voltage processor (pack contactor and isolation controller): a042 pack contactor closing";
CM_ SG_ 1290 HVP_a042_packContactorOpening "High-voltage processor (pack contactor and isolation controller): a042 pack contactor opening";
CM_ SG_ 1290 HVP_a042_resetRequestRequired "High-voltage processor (pack contactor and isolation controller): a042 reset request required";
CM_ SG_ 1290 HVP_a042_cpVersionMismatch "High-voltage processor (pack contactor and isolation controller): a042 cp version mismatch";
CM_ SG_ 1290 HVP_a043_overCurrent "High-voltage processor (pack contactor and isolation controller): a043 over current";
CM_ SG_ 1290 HVP_a043_overChargeCurrent "High-voltage processor (pack contactor and isolation controller): a043 over charge current";
CM_ SG_ 1290 HVP_a043_overDischargeCurrent "High-voltage processor (pack contactor and isolation controller): a043 over discharge current";
CM_ SG_ 1290 HVP_a043_overVoltage "High-voltage processor (pack contactor and isolation controller): a043 over voltage";
CM_ SG_ 1290 HVP_a043_overTemperature "High-voltage processor (pack contactor and isolation controller): a043 over temperature";
CM_ SG_ 1290 HVP_a043_underVoltage "High-voltage processor (pack contactor and isolation controller): a043 under voltage";
CM_ SG_ 1290 HVP_a043_crashEvent "High-voltage processor (pack contactor and isolation controller): a043 crash event";
CM_ SG_ 1290 HVP_a043_packContactorHw "High-voltage processor (pack contactor and isolation controller): a043 pack contactor hw";
CM_ SG_ 1290 HVP_a043_notAllowedtoEnergize "High-voltage processor (pack contactor and isolation controller): a043 not allowedto energize";
CM_ SG_ 1290 HVP_a043_bmbMia "High-voltage processor (pack contactor and isolation controller): a043 bmb mia";
CM_ SG_ 1290 HVP_a043_contactorOpened "High-voltage processor (pack contactor and isolation controller): a043 contactor opened";
CM_ SG_ 1290 HVP_a044_overCurrent "High-voltage processor (pack contactor and isolation controller): a044 over current";
CM_ SG_ 1290 HVP_a044_overChargeCurrent "High-voltage processor (pack contactor and isolation controller): a044 over charge current";
CM_ SG_ 1290 HVP_a044_overDischargeCurrent "High-voltage processor (pack contactor and isolation controller): a044 over discharge current";
CM_ SG_ 1290 HVP_a044_overVoltage "High-voltage processor (pack contactor and isolation controller): a044 over voltage";
CM_ SG_ 1290 HVP_a044_overTemperature "High-voltage processor (pack contactor and isolation controller): a044 over temperature";
CM_ SG_ 1290 HVP_a044_crashEvent "High-voltage processor (pack contactor and isolation controller): a044 crash event";
CM_ SG_ 1290 HVP_a044_fcContactorHw "High-voltage processor (pack contactor and isolation controller): a044 fc contactor hw";
CM_ SG_ 1290 HVP_a044_notAllowedtoEnergize "High-voltage processor (pack contactor and isolation controller): a044 not allowedto energize";
CM_ SG_ 1290 HVP_a044_bmsHvsMia "High-voltage processor (pack contactor and isolation controller): a044 bms hvs mia";
CM_ SG_ 1290 HVP_a044_cpMia "High-voltage processor (pack contactor and isolation controller): a044 cp mia";
CM_ SG_ 1290 HVP_a044_cpFault "High-voltage processor (pack contactor and isolation controller): a044 cp fault";
CM_ SG_ 1290 HVP_a044_supply12V "High-voltage processor (pack contactor and isolation controller): a044 supply12 v";
CM_ SG_ 1290 HVP_a044_supplyVer "High-voltage processor (pack contactor and isolation controller): a044 supply ver";
CM_ SG_ 1290 HVP_a044_packVoltageMismatch "High-voltage processor (pack contactor and isolation controller): a044 pack voltage mismatch";
CM_ SG_ 1290 HVP_a044_contactorOpened "High-voltage processor (pack contactor and isolation controller): a044 contactor opened";
CM_ SG_ 1290 HVP_a044_cpVersionMismatch "High-voltage processor (pack contactor and isolation controller): a044 cp version mismatch";
CM_ SG_ 1290 HVP_a045_dcLinkVoltage "High-voltage processor (pack contactor and isolation controller): a045 dc link voltage";
CM_ SG_ 1290 HVP_a046_shuntCurrent "High-voltage processor (pack contactor and isolation controller): a046 shunt current";
CM_ SG_ 1290 HVP_a046_shuntTemperature "High-voltage processor (pack contactor and isolation controller): a046 shunt temperature";
CM_ SG_ 1290 HVP_a046_asicTemperature "High-voltage processor (pack contactor and isolation controller): a046 asic temperature";
CM_ SG_ 1290 HVP_a047_shuntCurrent "High-voltage processor (pack contactor and isolation controller): a047 shunt current";
CM_ SG_ 1290 HVP_a047_auxCurrent "High-voltage processor (pack contactor and isolation controller): a047 aux current";
CM_ SG_ 1290 HVP_a049_contactorPowerV "High-voltage processor (pack contactor and isolation controller): a049 contactor power v";
CM_ SG_ 1290 HVP_a049_coilCurrent "High-voltage processor (pack contactor and isolation controller): a049 coil current";
CM_ SG_ 1290 HVP_a049_posCtrState "High-voltage processor (pack contactor and isolation controller): a049 pos ctr state; raw 0 = signal not available (SNA)";
CM_ SG_ 1290 HVP_a049_negCtrState "High-voltage processor (pack contactor and isolation controller): a049 neg ctr state; raw 0 = signal not available (SNA)";
CM_ SG_ 1290 HVP_a050_contactorPowerV "High-voltage processor (pack contactor and isolation controller): a050 contactor power v";
CM_ SG_ 1290 HVP_a050_coilCurrent "High-voltage processor (pack contactor and isolation controller): a050 coil current";
CM_ SG_ 1290 HVP_a050_posCtrState "High-voltage processor (pack contactor and isolation controller): a050 pos ctr state; raw 0 = signal not available (SNA)";
CM_ SG_ 1290 HVP_a050_negCtrState "High-voltage processor (pack contactor and isolation controller): a050 neg ctr state; raw 0 = signal not available (SNA)";
CM_ SG_ 1290 HVP_a051_shuntTemperature "High-voltage processor (pack contactor and isolation controller): a051 shunt temperature; raw 32768 = signal not available (SNA)";
CM_ SG_ 1290 HVP_a051_shuntCurrent "High-voltage processor (pack contactor and isolation controller): a051 shunt current; raw 32768 = signal not available (SNA)";
CM_ SG_ 1290 HVP_a051_energyReserveV "High-voltage processor (pack contactor and isolation controller): a051 energy reserve v; raw 65535 = signal not available (SNA)";
CM_ SG_ 1290 HVP_a053_packVoltage "High-voltage processor (pack contactor and isolation controller): a053 pack voltage";
CM_ SG_ 1290 HVP_a053_dcLinkVoltage "High-voltage processor (pack contactor and isolation controller): a053 dc link voltage";
CM_ SG_ 1290 HVP_a056_diagnosis "High-voltage processor (pack contactor and isolation controller): a056 diagnosis; raw 0 = signal not available (SNA)";
CM_ SG_ 1290 HVP_a056_shuntCurrent "High-voltage processor (pack contactor and isolation controller): a056 shunt current";
CM_ SG_ 1290 HVP_a056_posPackContactorState "High-voltage processor (pack contactor and isolation controller): a056 pos pack contactor state; raw 0 = signal not available (SNA)";
CM_ SG_ 1290 HVP_a056_negPackContactorState "High-voltage processor (pack contactor and isolation controller): a056 neg pack contactor state; raw 0 = signal not available (SNA)";
CM_ SG_ 1290 HVP_a056_posFcContactorState "High-voltage processor (pack contactor and isolation controller): a056 pos fc contactor state; raw 0 = signal not available (SNA)";
CM_ SG_ 1290 HVP_a056_negFcContactorState "High-voltage processor (pack contactor and isolation controller): a056 neg fc contactor state; raw 0 = signal not available (SNA)";
CM_ SG_ 1290 HVP_a058_VrefSample "High-voltage processor (pack contactor and isolation controller): a058 vref sample";
CM_ SG_ 1290 HVP_a058_bmbDeviceId "High-voltage processor (pack contactor and isolation controller): a058 bmb device id";
CM_ SG_ 1290 HVP_a058_VrefStatus "High-voltage processor (pack contactor and isolation controller): a058 vref status";
CM_ SG_ 1290 HVP_a058_VrefType "High-voltage processor (pack contactor and isolation controller): a058 vref type";
CM_ SG_ 1290 HVP_a060_stackVoltage "High-voltage processor (pack contactor and isolation controller): a060 stack voltage";
CM_ SG_ 1290 HVP_a060_sumBrickVoltage "High-voltage processor (pack contactor and isolation controller): a060 sum brick voltage";
CM_ SG_ 1290 HVP_a060_stackId "High-voltage processor (pack contactor and isolation controller): a060 stack id";
CM_ SG_ 1290 HVP_a062_bmbDeviceMask "High-voltage processor (pack contactor and isolation controller): a062 bmb device mask";
CM_ SG_ 1290 HVP_a067_hvilTypeFromHvp "High-voltage processor (pack contactor and isolation controller): a067 hvil type from hvp";
CM_ SG_ 1290 HVP_a067_hvilTypeFromGateway "High-voltage processor (pack contactor and isolation controller): a067 hvil type from gateway";
CM_ SG_ 1290 HVP_a067_hvilTypeIsFromCal "High-voltage processor (pack contactor and isolation controller): a067 hvil type is from cal";
CM_ SG_ 1290 HVP_a068_shuntTemperature "High-voltage processor (pack contactor and isolation controller): a068 shunt temperature; raw 32768 = signal not available (SNA)";
CM_ SG_ 1290 HVP_a068_shuntCurrent "High-voltage processor (pack contactor and isolation controller): a068 shunt current; raw 32768 = signal not available (SNA)";
CM_ SG_ 1290 HVP_a068_energyReserveV "High-voltage processor (pack contactor and isolation controller): a068 energy reserve v; raw 65535 = signal not available (SNA)";
CM_ BO_ 938 "High-voltage processor (pack contactor and isolation controller) message: alert matrix; frame length from the layout, not yet observed on a vehicle bus";
CM_ SG_ 938 HVP_matrixIndex "High-voltage processor (pack contactor and isolation controller): matrix index";
CM_ SG_ 938 HVP_w001_WatchdogReset "High-voltage processor (pack contactor and isolation controller): w001 watchdog reset";
CM_ SG_ 938 HVP_w002_UnusedAlert2 "High-voltage processor (pack contactor and isolation controller): w002 unused alert2";
CM_ SG_ 938 HVP_w003_SwAssertion "High-voltage processor (pack contactor and isolation controller): w003 sw assertion";
CM_ SG_ 938 HVP_w004_CrashEvent "High-voltage processor (pack contactor and isolation controller): w004 crash event";
CM_ SG_ 938 HVP_w005_OverDchgCurrentFault "High-voltage processor (pack contactor and isolation controller): w005 over dchg current fault";
CM_ SG_ 938 HVP_w006_OverChargeCurrentFault "High-voltage processor (pack contactor and isolation controller): w006 over charge current fault";
CM_ SG_ 938 HVP_w007_OverCurrentFault "High-voltage processor (pack contactor and isolation controller): w007 over current fault";
CM_ SG_ 938 HVP_w008_OverTemperatureFault "High-voltage processor (pack contactor and isolation controller): w008 over temperature fault";
CM_ SG_ 938 HVP_w009_OverVoltageFault "High-voltage processor (pack contactor and isolation controller): w009 over voltage fault";
CM_ SG_ 938 HVP_w010_UnderVoltageFault "High-voltage processor (pack contactor and isolation controller): w010 under voltage fault";
CM_ SG_ 938 HVP_w011_PrimaryBmbMiaFault "High-voltage processor (pack contactor and isolation controller): w011 primary bmb mia fault";
CM_ SG_ 938 HVP_w012_BmbDataIntegrityLoss "High-voltage processor (pack contactor and isolation controller): w012 bmb data integrity loss";
CM_ SG_ 938 HVP_w013_BmbCommunication "High-voltage processor (pack contactor and isolation controller): w013 bmb communication";
CM_ SG_ 938 HVP_w014_BmsMiaOnHviFault "High-voltage processor (pack contactor and isolation controller): w014 bms mia on hvi fault";
CM_ SG_ 938 HVP_w015_CpMiaFault "High-voltage processor (pack contactor and isolation controller): w015 cp mia fault";
CM_ SG_ 938 HVP_w016_PcsMiaFault "High-voltage processor (pack contactor and isolation controller): w016 pcs mia fault";
CM_ SG_ 938 HVP_w017_GtwMiaFault "High-voltage processor (pack contactor and isolation controller): w017 gtw mia fault";
CM_ SG_ 938 HVP_w018_powerCyclingPcs "High-voltage processor (pack contactor and isolation controller): w018 power cycling pcs";
CM_ SG_ 938 HVP_w019_CpFault "High-voltage processor (pack contactor and isolation controller): w019 cp fault";
CM_ SG_ 938 HVP_w020_ShuntHwMiaFault "High-voltage processor (pack contactor and isolation controller): w020 shunt hw mia fault";
CM_ SG_ 938 HVP_w021_PyroMiaFault "High-voltage processor (pack contactor and isolation controller): w021 pyro mia fault";
CM_ SG_ 938 HVP_w022_PyroMiaWarning "High-voltage processor (pack contactor and isolation controller): w022 pyro mia warning";
CM_ SG_ 938 HVP_w023_BmbResetRecovery "High-voltage processor (pack contactor and isolation controller): w023 bmb reset recovery";
CM_ SG_ 938 HVP_w024_Supply12vFault "High-voltage processor (pack contactor and isolation controller): w024 supply12v fault";
CM_ SG_ 938 HVP_w025_VerSupplyFault "High-voltage processor (pack contactor and isolation controller): w025 ver supply fault";
CM_ SG_ 938 HVP_w026_HvilFault "High-voltage processor (pack contactor and isolation controller): w026 hvil fault";
CM_ SG_ 938 HVP_w027_BmsMiaOnHvsFault "High-voltage processor (pack contactor and isolation controller): w027 bms mia on hvs fault";
CM_ SG_ 938 HVP_w028_PackVoltMismatchFault "High-voltage processor (pack contactor and isolation controller): w028 pack volt mismatch fault";
CM_ SG_ 938 HVP_w029_EnsMiaFault "High-voltage processor (pack contactor and isolation controller): w029 ens mia fault";
CM_ SG_ 938 HVP_w030_PackPosCtrArcFault "High-voltage processor (pack contactor and isolation controller): w030 pack pos ctr arc fault";
CM_ SG_ 938 HVP_w031_packNegCtrArcFault "High-voltage processor (pack contactor and isolation controller): w031 pack neg ctr arc fault";
CM_ SG_ 938 HVP_w032_ShuntHwAndBmsMiaFault "High-voltage processor (pack contactor and isolation controller): w032 shunt hw and bms mia fault";
CM_ SG_ 938 HVP_w033_fcContHwFault "High-voltage processor (pack contactor and isolation controller): w033 fc cont hw fault";
CM_ SG_ 938 HVP_w034_cpMismatchFault "High-voltage processor (pack contactor and isolation controller): w034 cp mismatch fault";
CM_ SG_ 938 HVP_w035_packContHwFault "High-voltage processor (pack contactor and isolation controller): w035 pack cont hw fault";
CM_ SG_ 938 HVP_w036_pyroFuseBlown "High-voltage processor (pack contactor and isolation controller): w036 pyro fuse blown";
CM_ SG_ 938 HVP_w037_pyroFuseFailedToBlow "High-voltage processor (pack contactor and isolation controller): w037 pyro fuse failed to blow";
CM_ SG_ 938 HVP_w038_CpilFault "High-voltage processor (pack contactor and isolation controller): w038 cpil fault";
CM_ SG_ 938 HVP_w039_PackContactorFellOpen "High-voltage processor (pack contactor and isolation controller): w039 pack contactor fell open";
CM_ SG_ 938 HVP_w040_FcContactorFellOpen "High-voltage processor (pack contactor and isolation controller): w040 fc contactor fell open";
CM_ SG_ 938 HVP_w041_packCtrCloseBlocked "High-voltage processor (pack contactor and isolation controller): w041 pack ctr close blocked";
CM_ SG_ 938 HVP_w042_fcCtrCloseBlocked "High-voltage processor (pack contactor and isolation controller): w042 fc ctr close blocked";
CM_ SG_ 938 HVP_w043_packContactorForceOpen "High-voltage processor (pack contactor and isolation controller): w043 pack contactor force open";
CM_ SG_ 938 HVP_w044_fcContactorForceOpen "High-voltage processor (pack contactor and isolation controller): w044 fc contactor force open";
CM_ SG_ 938 HVP_w045_dcLinkOverVoltage "High-voltage processor (pack contactor and isolation controller): w045 dc link over voltage";
CM_ SG_ 938 HVP_w046_shuntOverTemperature "High-voltage processor (pack contactor and isolation controller): w046 shunt over temperature";
CM_ SG_ 938 HVP_w047_passivePyroDeploy "High-voltage processor (pack contactor and isolation controller): w047 passive pyro deploy";
CM_ SG_ 938 HVP_w048_swUnsupportedBmbAsicTyp "High-voltage processor (pack contactor and isolation controller): w048 sw unsupported bmb asic type";
CM_ SG_ 938 HVP_w049_packCtrCloseFailed "High-voltage processor (pack contactor and isolation controller): w049 pack ctr close failed";
CM_ SG_ 938 HVP_w050_fcCtrCloseFailed "High-voltage processor (pack contactor and isolation controller): w050 fc ctr close failed";
CM_ SG_ 938 HVP_w051_shuntThermistorMia "High-voltage processor (pack contactor and isolation controller): w051 shunt thermistor mia";
CM_ SG_ 938 HVP_w052_BmbStatusRegError "High-voltage processor (pack contactor and isolation controller): w052 bmb status reg error";
CM_ SG_ 938 HVP_w053_hvVoltageSensorRational "High-voltage processor (pack contactor and isolation controller): w053 hv voltage sensor rationality";
CM_ SG_ 938 HVP_w054_swMissingConfigBlock "High-voltage processor (pack contactor and isolation controller): w054 sw missing config block";
CM_ SG_ 938 HVP_w055_swMissingPartNumber "High-voltage processor (pack contactor and isolation controller): w055 sw missing part number";
CM_ SG_ 938 HVP_w056_contactorFailedToOpen "High-voltage processor (pack contactor and isolation controller): w056 contactor failed to open";
CM_ SG_ 938 HVP_w057_BatmanDiagnosticsError "High-voltage processor (pack contactor and isolation controller): w057 batman diagnostics error";
CM_ SG_ 938 HVP_w058_BmbVrefBad "High-voltage processor (pack contactor and isolation controller): w058 bmb vref bad";
CM_ SG_ 938 HVP_w059_BmbVrefWarning "High-voltage processor (pack contactor and isolation controller): w059 bmb vref warning";
CM_ SG_ 938 HVP_w060_StackVoltageSense "High-voltage processor (pack contactor and isolation controller): w060 stack voltage sense";
CM_ SG_ 938 HVP_w061_ShuntCurrentRationality "High-voltage processor (pack contactor and isolation controller): w061 shunt current rationality";
CM_ SG_ 938 HVP_w062_BmbOtpConfigError "High-voltage processor (pack contactor and isolation controller): w062 bmb otp config error";
CM_ SG_ 938 HVP_w063_BmbBrickVRationality "High-voltage processor (pack contactor and isolation controller): w063 bmb brick v rationality";
CM_ SG_ 938 HVP_w064_BmbAuxVRationality "High-voltage processor (pack contactor and isolation controller): w064 bmb aux v rationality";
CM_ SG_ 938 HVP_w065_FastOpenVshDetected "High-voltage processor (pack contactor and isolation controller): w065 fast open vsh detected";
CM_ SG_ 938 HVP_w067_HvilCalNodeMismatch "High-voltage processor (pack contactor and isolation controller): w067 hvil cal node mismatch";
CM_ SG_ 938 HVP_w068_shuntUnexpectedThermist "High-voltage processor (pack contactor and isolation controller): w068 shunt unexpected thermistor";
CM_ SG_ 938 HVP_w069_hviCanFrameRxDropped "High-voltage processor (pack contactor and isolation controller): w069 hvi can frame rx dropped";
CM_ SG_ 938 HVP_w070_hvsCanFrameRxDropped "High-voltage processor (pack contactor and isolation controller): w070 hvs can frame rx dropped";
CM_ SG_ 938 HVP_w071_PassivePyroVrefRational "High-voltage processor (pack contactor and isolation controller): w071 passive pyro vref rationality";
CM_ BO_ 522 "High-voltage processor (pack contactor and isolation controller) message: contactor state; frame length from the layout, not yet observed on a vehicle bus";
CM_ SG_ 522 HVP_packContNegativeState "High-voltage processor (pack contactor and isolation controller): pack cont negative state; raw 0 = signal not available (SNA)";
CM_ SG_ 522 HVP_packContPositiveState "Current state of positive pack contactor; raw 0 = signal not available (SNA)";
CM_ SG_ 522 HVP_fcContPositiveAuxOpen "High-voltage processor (pack contactor and isolation controller): fc cont positive aux open";
CM_ SG_ 522 HVP_fcContNegativeAuxOpen "High-voltage processor (pack contactor and isolation controller): fc cont negative aux open";
CM_ SG_ 522 HVP_packContactorSetState "The current state of the pack contactors; raw 0 = signal not available (SNA)";
CM_ SG_ 522 HVP_fcContNegativeState "Current state of the negative FC contactor; raw 0 = signal not available (SNA)";
CM_ SG_ 522 HVP_contactorsBlocked "High-voltage processor (pack contactor and isolation controller): contactors blocked";
CM_ SG_ 522 HVP_fcContPositiveState "Current state of the positive FC contactor; raw 0 = signal not available (SNA)";
CM_ SG_ 522 HVP_fcContactorSetState "The current state of the fast charge contactors; raw 0 = signal not available (SNA)";
CM_ SG_ 522 HVP_fcCtrsRequestStatus "Current status of FC contactor request";
CM_ SG_ 522 HVP_fcCtrsResetRequestRequired "High-voltage processor (pack contactor and isolation controller): fc ctrs reset request required";
CM_ SG_ 522 HVP_fcCtrsOpenNowRequested "Flag indicated immediate-opening request of FC contactors";
CM_ SG_ 522 HVP_fcCtrsOpenRequested "Flag indicating opening request of FC contactors";
CM_ SG_ 522 HVP_fcCtrsClosingAllowed "Flag indicating closure allowance of FC contactors";
CM_ SG_ 522 HVP_packCtrsRequestStatus "Current request status of pack contactors";
CM_ SG_ 522 HVP_packCtrsResetRequestRequired "High-voltage processor (pack contactor and isolation controller): pack ctrs reset request required";
CM_ SG_ 522 HVP_packCtrsOpenNowRequested "Flag indicating immediate-opening request of pack contactors";
CM_ SG_ 522 HVP_packCtrsOpenRequested "Flag indicating opening request of pack contactors";
CM_ SG_ 522 HVP_packCtrsClosingAllowed "Flag indicating closure allowance of pack contactors";
CM_ SG_ 522 HVP_dcLinkAllowedToEnergize "Indicates there should be no HV exposure if the FC link is energized by an internal or external source";
CM_ SG_ 522 HVP_pyroTestInProgress "High-voltage processor (pack contactor and isolation controller): pyro test in progress";
CM_ SG_ 522 HVP_hvilDiag "Diagnostic status of HVIL circuit, including specific FAULT types; raw 14 = signal not available (SNA)";
CM_ SG_ 522 HVP_fcLinkAllowedToEnergize "The type of charge that is allowed to energize the FC link. Indicates that the HVP has disabled the dynamic FC weld check for DC charge, or has enabled the PCS charging hardware for AC charge";
CM_ BO_ 1962 "High-voltage processor (pack contactor and isolation controller) message: debug message; frame length from the layout, not yet observed on a vehicle bus";
CM_ SG_ 1962 HVP_debugMessageMultiplexer "High-voltage processor (pack contactor and isolation controller): debug message multiplexer";
CM_ SG_ 1962 HVP_ecuLogUploadRequest "High-voltage processor (pack contactor and isolation controller): ecu log upload request";
CM_ SG_ 1962 HVP_dcLinkVoltage "The HVP's measurement of the DC link voltage";
CM_ SG_ 1962 HVP_packVoltage "High-voltage processor (pack contactor and isolation controller): pack voltage";
CM_ SG_ 1962 HVP_fcLinkVoltage "Measured voltage on FC link";
CM_ SG_ 1962 HVP_10HzTask_stackUsage "High-voltage processor (pack contactor and isolation controller): 10 hz task stack usage";
CM_ SG_ 1962 HVP_packContVoltage "High-voltage processor (pack contactor and isolation controller): pack cont voltage";
CM_ SG_ 1962 HVP_packNegativeV "The HVP's common-mode measurement of PACK-HV-SENSE-NEG relative to chassis ground";
CM_ SG_ 1962 HVP_packPositiveV "The HVP's common-mode measurement of PACK-HV-SENSE-POS relative to chassis ground";
CM_ SG_ 1962 HVP_pyroAnalog "High-voltage processor (pack contactor and isolation controller): pyro analog";
CM_ SG_ 1962 HVP_shuntSetTCRCoeffA "High-voltage processor (pack contactor and isolation controller): shunt set TCR coeff a";
CM_ SG_ 1962 HVP_shuntSetTCRCoeffB "High-voltage processor (pack contactor and isolation controller): shunt set TCR coeff b";
CM_ SG_ 1962 HVP_shuntSetTCRCoeffC "High-voltage processor (pack contactor and isolation controller): shunt set TCR coeff c";
CM_ SG_ 1962 HVP_shuntSetTCRCoeffD "High-voltage processor (pack contactor and isolation controller): shunt set TCR coeff d";
CM_ SG_ 1962 HVP_fcContCoilCurrent "High-voltage processor (pack contactor and isolation controller): fc cont coil current";
CM_ SG_ 1962 HVP_fcContVoltage "High-voltage processor (pack contactor and isolation controller): fc cont voltage";
CM_ SG_ 1962 HVP_hvilInVoltage "Measured HVIL input voltage";
CM_ SG_ 1962 HVP_hvilOutVoltage "Measured HVIL output voltage";
CM_ SG_ 1962 HVP_shuntGainInvalidCountDbg "High-voltage processor (pack contactor and isolation controller): shunt gain invalid count dbg";
CM_ SG_ 1962 HVP_passivePyroRefVoltageMax "High-voltage processor (pack contactor and isolation controller): passive pyro ref voltage max; raw 1023 = signal not available (SNA)";
CM_ SG_ 1962 HVP_passivePyroRefVoltageMin "High-voltage processor (pack contactor and isolation controller): passive pyro ref voltage min; raw 1023 = signal not available (SNA)";
CM_ SG_ 1962 HVP_packContCoilCurrent "High-voltage processor (pack contactor and isolation controller): pack cont coil current";
CM_ SG_ 1962 HVP_battery12V "Monitored voltage sense of 12V battery";
CM_ SG_ 1962 HVP_fcLinkPositiveV "High-voltage processor (pack contactor and isolation controller): fc link positive v";
CM_ BO_ 1666 "High-voltage processor (pack contactor and isolation controller) message: hvp faults; frame length from the layout, not yet observed on a vehicle bus";
CM_ SG_ 1666 HVP_packContactorHwFault "High-voltage processor (pack contactor and isolation controller): pack contactor hw fault";
CM_ SG_ 1666 HVP_fcContactorHwFault "High-voltage processor (pack contactor and isolation controller): fc contactor hw fault";
CM_ SG_ 1666 HVP_hvilStatus "High-voltage processor (pack contactor and isolation controller): hvil status";
CM_ BO_ 554 "High-voltage processor (pack contactor and isolation controller) message: hvs control; frame length from the layout, not yet observed on a vehicle bus";
CM_ SG_ 554 HVP_dcLinkVoltageRequest "High-voltage processor (pack contactor and isolation controller): dc link voltage request";
CM_ SG_ 554 HVP_pcsControlRequest "The operating state that the HVP would like the PCS to be in";
CM_ SG_ 554 HVP_pcsChargeHwEnabled "The state of the PCS's charge enable line";
CM_ SG_ 554 HVP_pcsDcdcHwEnabled "The state of the PCS's DCDC enable line";
CM_ SG_ 554 HVP_dcLinkVoltageFiltered "High-voltage processor (pack contactor and isolation controller): dc link voltage filtered; raw 1498 = signal not available (SNA)";
CM_ BO_ 784 "High-voltage processor (pack contactor and isolation controller) message: info; frame length from the layout, not yet observed on a vehicle bus";
CM_ SG_ 784 HVP_infoIndex "High-voltage processor (pack contactor and isolation controller): info index";
CM_ SG_ 784 HVP_buildType "High-voltage processor (pack contactor and isolation controller): build type";
CM_ SG_ 784 HVP_buildConfigId "High-voltage processor (pack contactor and isolation controller): build config id";
CM_ SG_ 784 HVP_hardwareId "High-voltage processor (pack contactor and isolation controller): hardware id";
CM_ SG_ 784 HVP_componentId "High-voltage processor (pack contactor and isolation controller): component id";
CM_ SG_ 784 HVP_pcbaId "High-voltage processor (pack contactor and isolation controller): pcba id";
CM_ SG_ 784 HVP_assemblyId "HVP's assigned assembly ID";
CM_ SG_ 784 HVP_usageId "HVP's assigned usage ID";
CM_ SG_ 784 HVP_subUsageId "HVP's assigned subusage ID";
CM_ SG_ 784 HVP_platformType "High-voltage processor (pack contactor and isolation controller): platform type";
CM_ SG_ 784 HVP_appCrc "High-voltage processor (pack contactor and isolation controller): app crc";
CM_ SG_ 784 HVP_appGitHash "High-voltage processor (pack contactor and isolation controller): app git hash";
CM_ SG_ 784 HVP_bootGitHash "High-voltage processor (pack contactor and isolation controller): boot git hash";
CM_ SG_ 784 HVP_bootUdsProtoVersion "High-voltage processor (pack contactor and isolation controller): boot uds proto version";
CM_ SG_ 784 HVP_bootCrc "High-voltage processor (pack contactor and isolation controller): boot crc";
CM_ BO_ 1914 "High-voltage processor (pack contactor and isolation controller) message: log1hz; frame length from the layout, not yet observed on a vehicle bus";
CM_ SG_ 1914 HVP_log1HzIndex "High-voltage processor (pack contactor and isolation controller): log1 hz index";
CM_ SG_ 1914 HVP_bmbAsicType "The BMB Asic type being used by this battery pack for reading brick data";
CM_ SG_ 1914 HVP_shuntCurrentAuxLog "High-voltage processor (pack contactor and isolation controller): shunt current aux log";
CM_ SG_ 1914 HVP_pyroSquibResistance "The pyro resistance measured on attempt to close contactor or by the Pyro selftest; raw 65535 = signal not available (SNA)";
CM_ SG_ 1914 HVP_shuntAsicChipXCoordinate "High-voltage processor (pack contactor and isolation controller): shunt asic chip x coordinate";
CM_ SG_ 1914 HVP_shuntAsicChipYCoordinate "High-voltage processor (pack contactor and isolation controller): shunt asic chip y coordinate";
CM_ SG_ 1914 HVP_hvilCalType "High-voltage processor (pack contactor and isolation controller): hvil cal type";
CM_ SG_ 1914 HVP_gpioPcsDcdcPwmEnable "High-voltage processor (pack contactor and isolation controller): gpio pcs dcdc pwm enable";
CM_ SG_ 1914 HVP_gpioPcsChargePwmEnable "High-voltage processor (pack contactor and isolation controller): gpio pcs charge pwm enable";
CM_ SG_ 1914 HVP_gpioPcsEnable "HVP GPIO control for PCS logic power enable line";
CM_ SG_ 1914 HVP_shuntAsicChipWaferNumber "High-voltage processor (pack contactor and isolation controller): shunt asic chip wafer number";
CM_ SG_ 1914 HVP_energyReserveMin "a lowest energy reserve value measured over sliding window";
CM_ SG_ 1914 HVP_energyReserveMax "a highest energy reserve value measured over sliding window";
CM_ SG_ 1914 HVP_energyReserveAvg "an average energy reserve value measured over sliding window";
CM_ BO_ 1553 "High-voltage processor (pack contactor and isolation controller) message: uds response; frame length from the layout, not yet observed on a vehicle bus";
CM_ SG_ 1553 HVP_udsResponseData "High-voltage processor (pack contactor and isolation controller): uds response data";
CM_ BO_ 1208 "ICR ECU message: alert log; frame length from the layout, not yet observed on a vehicle bus";
CM_ SG_ 1208 ICR_alertID "ICR ECU: alert ID";
CM_ SG_ 1208 ICR_alertState "ICR ECU: alert state";
CM_ SG_ 1208 ICR_a001_watchdogTaskAppDPM "ICR ECU: a001 watchdog task app DPM";
CM_ SG_ 1208 ICR_a001_watchdogTaskMMWControl "ICR ECU: a001 watchdog task MMW control";
CM_ SG_ 1208 ICR_a001_watchdogTaskSentinelInt "ICR ECU: a001 watchdog task sentinel interface";
CM_ SG_ 1208 ICR_a001_watchdogTaskSentinelMod "ICR ECU: a001 watchdog task sentinel mode change";
CM_ SG_ 1208 ICR_a001_watchdogTaskComTXRAD "ICR ECU: a001 watchdog task com TXRAD";
CM_ SG_ 1208 ICR_a001_watchdogTaskComRX "ICR ECU: a001 watchdog task com RX";
CM_ SG_ 1208 ICR_a001_watchdogTaskComTXVEH "ICR ECU: a001 watchdog task com TXVEH";
CM_ SG_ 1208 ICR_a001_watchdogTaskComUDS "ICR ECU: a001 watchdog task com UDS";
CM_ SG_ 1208 ICR_a001_watchdogTaskCommonError "ICR ECU: a001 watchdog task common error";
CM_ SG_ 1208 ICR_a001_watchdogTaskUARTLog "ICR ECU: a001 watchdog task UART log";
CM_ SG_ 1208 ICR_a001_watchdogTaskDataDump "ICR ECU: a001 watchdog task data dump";
CM_ SG_ 1208 ICR_a001_watchdogRTOSAppRun10MS "ICR ECU: a001 watchdog RTOS app run10 MS";
CM_ SG_ 1208 ICR_a001_watchdogRTOSAppRun1MS "ICR ECU: a001 watchdog RTOS app run1 MS";
CM_ SG_ 1208 ICR_a001_InternalWatchdog "ICR ECU: a001 internal watchdog";
CM_ SG_ 1208 ICR_a015_NVMMMemOverflow "ICR ECU: a015 NVMM mem overflow";
CM_ SG_ 1208 ICR_a015_NVMMFilesystemError "ICR ECU: a015 NVMM filesystem error";
CM_ SG_ 1208 ICR_a015_NVMMRecordIDError "ICR ECU: a015 NVMM record ID error";
CM_ SG_ 1208 ICR_a059_voltageDrop "ICR ECU: a059 voltage drop";
CM_ SG_ 1208 ICR_a059_resistanceEstimate "ICR ECU: a059 resistance estimate";
CM_ SG_ 1208 ICR_a059_current "ICR ECU: a059 current";
CM_ SG_ 1208 ICR_a063_switchChannel "ICR ECU: a063 switch channel";
CM_ SG_ 1208 ICR_a063_switchType "ICR ECU: a063 switch type";
CM_ SG_ 1208 ICR_a063_ADCVoltage "ICR ECU: a063 ADC voltage";
CM_ SG_ 1208 ICR_a063_disconnected "ICR ECU: a063 disconnected";
CM_ SG_ 1208 ICR_a063_indeterminate "ICR ECU: a063 indeterminate";
CM_ SG_ 1208 ICR_a063_stuckActive "ICR ECU: a063 stuck active";
CM_ SG_ 1208 ICR_a063_faulted "ICR ECU: a063 faulted";
CM_ SG_ 1208 ICR_a133_nearClutter "ICR ECU: a133 near clutter";
CM_ SG_ 1208 ICR_a133_farClutter "ICR ECU: a133 far clutter";
CM_ SG_ 1208 ICR_a137_nearClutter "ICR ECU: a137 near clutter";
CM_ SG_ 1208 ICR_a137_farClutter "ICR ECU: a137 far clutter";
CM_ SG_ 1208 ICR_a139_nearClutter "ICR ECU: a139 near clutter";
CM_ SG_ 1208 ICR_a139_farClutter "ICR ECU: a139 far clutter";
CM_ SG_ 1208 ICR_a141_pmicQualityExcursion "ICR ECU: a141 pmic quality excursion";
CM_ SG_ 1208 ICR_a141_calDataNotCalibratedOrP "ICR ECU: a141 cal data not calibrated or processing";
CM_ SG_ 1208 ICR_a141_calDataValRXPhaseAboveM "ICR ECU: a141 cal data val RX phase above max";
CM_ SG_ 1208 ICR_a141_calDataValRXPhaseMissin "ICR ECU: a141 cal data val RX phase missing unit mag";
CM_ SG_ 1208 ICR_a141_calDataValRangeBiasAbov "ICR ECU: a141 cal data val range bias above max";
CM_ BO_ 952 "ICR ECU message: alert matrix; frame length from the layout, not yet observed on a vehicle bus";
CM_ SG_ 952 ICR_matrixIndex "ICR ECU: matrix index";
CM_ SG_ 952 ICR_a001_WatchdogReset "ICR ECU: a001 watchdog reset";
CM_ SG_ 952 ICR_a002_PowerLossReset "ICR ECU: a002 power loss reset";
CM_ SG_ 952 ICR_a003_SWAssertion "ICR ECU: a003 SW assertion";
CM_ SG_ 952 ICR_a005_CANTXError "ICR ECU: a005 CANTX error";
CM_ SG_ 952 ICR_a006_CANTX_cyclicError "ICR ECU: a006 CANTX cyclic error";
CM_ SG_ 952 ICR_a012_CPUReset "ICR ECU: a012 CPU reset";
CM_ SG_ 952 ICR_a013_AlertManagerFault "ICR ECU: a013 alert manager fault";
CM_ SG_ 952 ICR_a015_NVMMError "ICR ECU: a015 NVMM error";
CM_ SG_ 952 ICR_a016_NVMMRecordError "ICR ECU: a016 NVMM record error";
CM_ SG_ 952 ICR_a021_TaskSchedulerError "ICR ECU: a021 task scheduler error";
CM_ SG_ 952 ICR_a022_TaskInitError "ICR ECU: a022 task init error";
CM_ SG_ 952 ICR_a029_CoreDump "ICR ECU: a029 core dump";
CM_ SG_ 952 ICR_a030_ECULogUploadRequest "ICR ECU: a030 ECU log upload request";
CM_ SG_ 952 ICR_a031_UDSActive "ICR ECU: a031 UDS active";
CM_ SG_ 952 ICR_a041_HighCPULoad "ICR ECU: a041 high CPU load";
CM_ SG_ 952 ICR_a042_HighStackUsage "ICR ECU: a042 high stack usage";
CM_ SG_ 952 ICR_a043_Task1msError "ICR ECU: a043 task1ms error";
CM_ SG_ 952 ICR_a044_Task10msError "ICR ECU: a044 task10ms error";
CM_ SG_ 952 ICR_a045_Task100msError "ICR ECU: a045 task100ms error";
CM_ SG_ 952 ICR_a046_Task1000msError "ICR ECU: a046 task1000ms error";
CM_ SG_ 952 ICR_a058_inputRHighSyncDebug "ICR ECU: a058 input r high sync debug";
CM_ SG_ 952 ICR_a059_inputResistanceHigh "ICR ECU: a059 input resistance high";
CM_ SG_ 952 ICR_a060_engineeringBuild "ICR ECU: a060 engineering build";
CM_ SG_ 952 ICR_a061_XCPConnected "ICR ECU: a061 XCP connected";
CM_ SG_ 952 ICR_a062_XCPWasConnected "ICR ECU: a062 XCP was connected";
CM_ SG_ 952 ICR_a063_SwitchFault "ICR ECU: a063 switch fault";
CM_ SG_ 952 ICR_a064_busSleepReqTimeout "ICR ECU: a064 bus sleep req timeout";
CM_ SG_ 952 ICR_a133_radarBlocked "ICR ECU: a133 radar blocked";
CM_ SG_ 952 ICR_a134_radarPgood "ICR ECU: a134 radar pgood";
CM_ SG_ 952 ICR_a135_radarTxBallBreak "ICR ECU: a135 radar tx ball break";
CM_ SG_ 952 ICR_a136_radarHighTemperature "ICR ECU: a136 radar high temperature";
CM_ SG_ 952 ICR_a137_radarBlocked "ICR ECU: a137 radar blocked";
CM_ SG_ 952 ICR_a138_DriverSideMismatch "ICR ECU: a138 driver side mismatch";
CM_ SG_ 952 ICR_a139_AbnormalBlockageDetecte "ICR ECU: a139 abnormal blockage detected";
CM_ SG_ 952 ICR_a140_OccupancyExceptionEncou "ICR ECU: a140 occupancy exception encountered";
CM_ SG_ 952 ICR_a141_RequiresReplacement "ICR ECU: a141 requires replacement";
CM_ SG_ 952 ICR_a142_ModeOverrideActive "ICR ECU: a142 mode override active";
CM_ SG_ 952 ICR_a143_DSPCoreSkipped "ICR ECU: a143 DSP core skipped";
CM_ SG_ 952 ICR_a144_OccupancyNotificationAl "ICR ECU: a144 occupancy notification alert";
CM_ BO_ 941 "ICR ECU message: info; frame length from the layout, not yet observed on a vehicle bus";
CM_ SG_ 941 ICR_infoIndex "ICR ECU: info index";
CM_ SG_ 941 ICR_infoBuildType "ICR ECU: info build type";
CM_ SG_ 941 ICR_infoPcbaId "ICR ECU: info pcba id";
CM_ SG_ 941 ICR_infoAssemblyId "ICR ECU: info assembly id";
CM_ SG_ 941 ICR_infoUsageId "ICR ECU: info usage id";
CM_ SG_ 941 ICR_infoAppCrc "ICR ECU: info app crc";
CM_ SG_ 941 ICR_infoBoardPartNumber17 "ICR ECU: info board part number17";
CM_ SG_ 941 ICR_infoBoardPartNumber814 "ICR ECU: info board part number814";
CM_ SG_ 941 ICR_infoBoardPartNumber1520 "ICR ECU: info board part number1520";
CM_ BO_ 667 "ICR ECU message: non localized occupancy; frame length from the layout, not yet observed on a vehicle bus";
CM_ SG_ 667 ICR_lifePresenceMLOutput "ICR ECU: life presence ML output; raw 255 = signal not available (SNA)";
CM_ SG_ 667 ICR_largeOccupantPresenceMLOutpu "ICR ECU: large occupant presence ML output; raw 255 = signal not available (SNA)";
CM_ SG_ 667 ICR_lifePresenceRaw "ICR ECU: life presence raw; raw 0 = signal not available (SNA)";
CM_ SG_ 667 ICR_lifePresenceFilt "ICR ECU: life presence filt; raw 0 = signal not available (SNA)";
CM_ SG_ 667 ICR_largeOccupantPresenceRaw "ICR ECU: large occupant presence raw; raw 3 = signal not available (SNA)";
CM_ SG_ 667 ICR_largeOccupantPresenceFilt "Indicates the filtered detection status of the Large Occupant Presence Detection feature; raw 3 = signal not available (SNA)";
CM_ SG_ 667 ICR_childPresenceFunctionality "The functionality of the child presence detection app on ICR; raw 2 = signal not available (SNA)";
CM_ SG_ 667 ICR_userPresenceFunctionality "ICR ECU: user presence functionality; raw 2 = signal not available (SNA)";
CM_ SG_ 667 ICR_userPresenceMLOutput "ICR ECU: user presence ML output; raw 255 = signal not available (SNA)";
CM_ SG_ 667 ICR_userPresenceRaw "ICR ECU: user presence raw; raw 3 = signal not available (SNA)";
CM_ SG_ 667 ICR_userPresenceFilt "Detection status of User Presence Detection feature; raw 3 = signal not available (SNA)";
CM_ BO_ 536 "ICR ECU message: occupancy; frame length from the layout, not yet observed on a vehicle bus";
CM_ SG_ 536 ICR_occupancy1LRaw "(Non-Functional Interface) Occupancy detection status of First Row left seat; raw 3 = signal not available (SNA)";
CM_ SG_ 536 ICR_occupancy1RRaw "(Non-Functional Interface) Occupancy detection status of First Row right seat; raw 3 = signal not available (SNA)";
CM_ SG_ 536 ICR_occupancy1LVoteCnt "ICR ECU: occupancy1 l vote cnt";
CM_ SG_ 536 ICR_occupancy1RVoteCnt "ICR ECU: occupancy1 r vote cnt";
CM_ SG_ 536 ICR_occupancy1LFilt "(Non-Functional Interface) Occupancy detection status of First Row left seat; raw 3 = signal not available (SNA)";
CM_ SG_ 536 ICR_occupancy1RFilt "(Non-Functional Interface) Occupancy detection status of First Row right seat; raw 3 = signal not available (SNA)";
CM_ SG_ 536 ICR_occupancy2LFilt "ICR ECU: occupancy2 l filt; raw 3 = signal not available (SNA)";
CM_ SG_ 536 ICR_occupancy2CFilt "ICR ECU: occupancy2 c filt; raw 3 = signal not available (SNA)";
CM_ SG_ 536 ICR_occupancy2RFilt "ICR ECU: occupancy2 r filt; raw 3 = signal not available (SNA)";
CM_ SG_ 536 ICR_occupancy1RFiltExp "ICR ECU: occupancy1 r filt exp; raw 3 = signal not available (SNA)";
CM_ SG_ 536 ICR_occupancyCounter "ICR ECU: occupancy counter";
CM_ SG_ 536 ICR_occupancyChecksum "ICR ECU: occupancy checksum";
CM_ BO_ 670 "ICR ECU message: occupancy2; frame length from the layout, not yet observed on a vehicle bus";
CM_ SG_ 670 ICR_classification1RFilt "Occupant classification status of First Row Right seat; raw 0 = signal not available (SNA)";
CM_ SG_ 670 ICR_classification1LRaw "ICR ECU: classification1 l raw; raw 0 = signal not available (SNA)";
CM_ SG_ 670 ICR_classification1RRaw "ICR ECU: classification1 r raw; raw 0 = signal not available (SNA)";
CM_ SG_ 670 ICR_classification1LMLOutput "ICR ECU: classification1 LML output; raw 255 = signal not available (SNA)";
CM_ SG_ 670 ICR_classification1RMLOutput "ICR ECU: classification1 RML output; raw 255 = signal not available (SNA)";
CM_ SG_ 670 ICR_classification1LqF "ICR ECU: classification1 lq f";
CM_ SG_ 670 ICR_blockageClutterFar "The far clutter output of the blockage algorithm; raw 16 = signal not available (SNA)";
CM_ SG_ 670 ICR_blockageClutterNear "The near clutter output of the blockage algorithm; raw 16 = signal not available (SNA)";
CM_ SG_ 670 ICR_classification1LFilt "ICR ECU: classification1 l filt; raw 0 = signal not available (SNA)";
CM_ SG_ 670 ICR_classification1RqF "ICR ECU: classification1 rq f";
CM_ SG_ 670 ICR_classification1LLatched "ICR ECU: classification1 l latched; raw 0 = signal not available (SNA)";
CM_ SG_ 670 ICR_classification1RLatched "ICR ECU: classification1 r latched; raw 0 = signal not available (SNA)";
CM_ SG_ 670 ICR_classification1LIsLatched "ICR ECU: classification1 l is latched";
CM_ SG_ 670 ICR_classification1RIsLatched "ICR ECU: classification1 r is latched";
CM_ SG_ 670 ICR_occupancy2Counter "ICR ECU: occupancy2 counter";
CM_ SG_ 670 ICR_occupancy2Checksum "ICR ECU: occupancy2 checksum";
CM_ BO_ 664 "ICR ECU message: status; frame length from the layout, not yet observed on a vehicle bus";
CM_ SG_ 664 ICR_sensorMode "ICR ECU: sensor mode";
CM_ SG_ 664 ICR_blocked "Indicates if sensor is blocked or not; raw 0 = signal not available (SNA)";
CM_ SG_ 664 ICR_booted "Indicates if ICR has rebooted";
CM_ SG_ 664 ICR_rdMapDumpCompleted "ICR ECU: rd map dump completed";
CM_ SG_ 664 ICR_algoVersion "ICR ECU: algo version";
CM_ SG_ 664 ICR_l2HeapUsage "ICR ECU: l2 heap usage";
CM_ SG_ 664 ICR_intrusionStatus "ICR ECU: intrusion status";
CM_ SG_ 664 ICR_blockageScaledMLOutput "Indicates a scaled blockage ML Output";
CM_ BO_ 1624 "ICR ECU message: uds response; frame length from the layout, not yet observed on a vehicle bus";
CM_ SG_ 1624 ICR_udsResponseData "ICR ECU: uds response data";
CM_ BO_ 1012 "LS ECU message: light show; forwarded onto this bus by the gateway; frame length from the layout, not yet observed on a vehicle bus";
CM_ SG_ 1012 LS_lightShowIndex "LS ECU: light show index";
CM_ SG_ 1012 LS_lightLeftRampedChannel1Reques "LS ECU: light left ramped channel1 request";
CM_ SG_ 1012 LS_lightLeftRampedChannel1Durati "LS ECU: light left ramped channel1 duration";
CM_ SG_ 1012 LS_lightLeftRampedChannel2Reques "LS ECU: light left ramped channel2 request";
CM_ SG_ 1012 LS_lightLeftRampedChannel2Durati "LS ECU: light left ramped channel2 duration";
CM_ SG_ 1012 LS_lightLeftRampedChannel3Reques "LS ECU: light left ramped channel3 request";
CM_ SG_ 1012 LS_lightLeftRampedChannel3Durati "LS ECU: light left ramped channel3 duration";
CM_ SG_ 1012 LS_lightLeftRampedChannel4Reques "LS ECU: light left ramped channel4 request";
CM_ SG_ 1012 LS_lightLeftRampedChannel4Durati "LS ECU: light left ramped channel4 duration";
CM_ SG_ 1012 LS_lightLeftRampedChannel5Reques "LS ECU: light left ramped channel5 request";
CM_ SG_ 1012 LS_lightLeftRampedChannel5Durati "LS ECU: light left ramped channel5 duration";
CM_ SG_ 1012 LS_lightLeftRampedChannel6Reques "LS ECU: light left ramped channel6 request";
CM_ SG_ 1012 LS_lightLeftRampedChannel6Durati "LS ECU: light left ramped channel6 duration";
CM_ SG_ 1012 LS_lightLeftRampedChannel7Reques "LS ECU: light left ramped channel7 request";
CM_ SG_ 1012 LS_lightLeftRampedChannel7Durati "LS ECU: light left ramped channel7 duration";
CM_ SG_ 1012 LS_lightRightRampedChannel1Reque "LS ECU: light right ramped channel1 request";
CM_ SG_ 1012 LS_lightRightRampedChannel1Durat "LS ECU: light right ramped channel1 duration; raw 1 = signal not available (SNA)";
CM_ SG_ 1012 LS_lightRightRampedChannel2Reque "LS ECU: light right ramped channel2 request";
CM_ SG_ 1012 LS_lightRightRampedChannel2Durat "LS ECU: light right ramped channel2 duration; raw 1 = signal not available (SNA)";
CM_ SG_ 1012 LS_lightRightRampedChannel3Reque "LS ECU: light right ramped channel3 request";
CM_ SG_ 1012 LS_lightRightRampedChannel3Durat "LS ECU: light right ramped channel3 duration";
CM_ SG_ 1012 LS_lightRightRampedChannel4Reque "LS ECU: light right ramped channel4 request";
CM_ SG_ 1012 LS_lightRightRampedChannel4Durat "LS ECU: light right ramped channel4 duration";
CM_ SG_ 1012 LS_lightRightRampedChannel5Reque "LS ECU: light right ramped channel5 request";
CM_ SG_ 1012 LS_lightRightRampedChannel5Durat "LS ECU: light right ramped channel5 duration";
CM_ SG_ 1012 LS_lightRightRampedChannel6Reque "LS ECU: light right ramped channel6 request";
CM_ SG_ 1012 LS_lightRightRampedChannel6Durat "LS ECU: light right ramped channel6 duration";
CM_ SG_ 1012 LS_lightRightRampedChannel7Reque "LS ECU: light right ramped channel7 request";
CM_ SG_ 1012 LS_lightRightRampedChannel7Durat "LS ECU: light right ramped channel7 duration";
CM_ SG_ 1012 LS_lightRearTurnLeftRequest "LS ECU: light rear turn left request";
CM_ SG_ 1012 LS_lightRearTurnRightRequest "LS ECU: light rear turn right request";
CM_ SG_ 1012 LS_lightSideRepeaterLeftRequest "LS ECU: light side repeater left request";
CM_ SG_ 1012 LS_lightSideRepeaterRightRequest "LS ECU: light side repeater right request";
CM_ SG_ 1012 LS_lightSideMarkerLeftRequest "LS ECU: light side marker left request";
CM_ SG_ 1012 LS_lightSideMarkerRightRequest "LS ECU: light side marker right request";
CM_ SG_ 1012 LS_lightFrontFogLeftRequest "LS ECU: light front fog left request";
CM_ SG_ 1012 LS_lightFrontFogRightRequest "LS ECU: light front fog right request";
CM_ SG_ 1012 LS_lightRearFogRequest "LS ECU: light rear fog request";
CM_ SG_ 1012 LS_lightBrakeRequest "LS ECU: light brake request";
CM_ SG_ 1012 LS_lightTailLeftRequest "LS ECU: light tail left request";
CM_ SG_ 1012 LS_lightTailRightRequest "LS ECU: light tail right request";
CM_ SG_ 1012 LS_lightLicensePlateRequest "LS ECU: light license plate request";
CM_ SG_ 1012 LS_lightReverseRequest "LS ECU: light reverse request";
CM_ SG_ 1012 LS_lightAuxParkLeftRequest "LS ECU: light aux park left request";
CM_ SG_ 1012 LS_lightAuxParkRightRequest "LS ECU: light aux park right request";
CM_ SG_ 1012 LS_mirrorRequestLeft "LS ECU: mirror request left";
CM_ SG_ 1012 LS_mirrorRequestRight "LS ECU: mirror request right";
CM_ SG_ 1012 LS_liftgateRequest "LS ECU: liftgate request";
CM_ SG_ 1012 LS_windowRequestLF "LS ECU: window request LF";
CM_ SG_ 1012 LS_windowRequestLR "LS ECU: window request LR";
CM_ SG_ 1012 LS_windowRequestRF "LS ECU: window request RF";
CM_ SG_ 1012 LS_windowRequestRR "LS ECU: window request RR";
CM_ SG_ 1012 LS_presentingHandleRequestLF "LS ECU: presenting handle request LF";
CM_ SG_ 1012 LS_presentingHandleRequestLR "LS ECU: presenting handle request LR";
CM_ SG_ 1012 LS_presentingHandleRequestRF "LS ECU: presenting handle request RF";
CM_ SG_ 1012 LS_presentingHandleRequestRR "LS ECU: presenting handle request RR";
CM_ SG_ 1012 LS_powerFrontDoorRequestLeft "LS ECU: power front door request left";
CM_ SG_ 1012 LS_powerFrontDoorRequestRight "LS ECU: power front door request right";
CM_ SG_ 1012 LS_falconDoorRequestLeft "LS ECU: falcon door request left";
CM_ SG_ 1012 LS_falconDoorRequestRight "LS ECU: falcon door request right";
CM_ SG_ 1012 LS_chargePortRequest "LS ECU: charge port request; raw 3 = signal not available (SNA)";
CM_ SG_ 1012 LS_chargePortRaveRequest "LS ECU: charge port rave request";
CM_ SG_ 1012 LS_suspensionRequest "LS ECU: suspension request; raw 3 = signal not available (SNA)";
CM_ SG_ 1012 LS_rgbIPFLRed "LS ECU: rgb IPFL red";
CM_ SG_ 1012 LS_rgbIPFLGreen "LS ECU: rgb IPFL green";
CM_ SG_ 1012 LS_rgbIPFLBlue "LS ECU: rgb IPFL blue";
CM_ SG_ 1012 LS_rgbIPFRRed "LS ECU: rgb IPFR red";
CM_ SG_ 1012 LS_rgbIPFRGreen "LS ECU: rgb IPFR green";
CM_ SG_ 1012 LS_rgbIPFRBlue "LS ECU: rgb IPFR blue";
CM_ SG_ 1012 LS_rgbDoorFLForeRed "LS ECU: rgb door FL fore red";
CM_ SG_ 1012 LS_rgbDoorFLForeGreen "LS ECU: rgb door FL fore green";
CM_ SG_ 1012 LS_rgbDoorFLForeBlue "LS ECU: rgb door FL fore blue";
CM_ SG_ 1012 LS_rgbDoorFLAftRed "LS ECU: rgb door FL aft red";
CM_ SG_ 1012 LS_rgbDoorFLAftGreen "LS ECU: rgb door FL aft green";
CM_ SG_ 1012 LS_rgbDoorFLAftBlue "LS ECU: rgb door FL aft blue";
CM_ SG_ 1012 LS_rgbDoorFRForeRed "LS ECU: rgb door FR fore red";
CM_ SG_ 1012 LS_rgbDoorFRForeGreen "LS ECU: rgb door FR fore green";
CM_ SG_ 1012 LS_rgbDoorFRForeBlue "LS ECU: rgb door FR fore blue";
CM_ SG_ 1012 LS_rgbDoorFRAftRed "LS ECU: rgb door FR aft red";
CM_ SG_ 1012 LS_rgbDoorFRAftGreen "LS ECU: rgb door FR aft green";
CM_ SG_ 1012 LS_rgbDoorFRAftBlue "LS ECU: rgb door FR aft blue";
CM_ SG_ 1012 LS_rgbDoorRLForeRed "LS ECU: rgb door RL fore red";
CM_ SG_ 1012 LS_rgbDoorRLForeGreen "LS ECU: rgb door RL fore green";
CM_ SG_ 1012 LS_rgbDoorRLForeBlue "LS ECU: rgb door RL fore blue";
CM_ SG_ 1012 LS_rgbDoorRLAftRed "LS ECU: rgb door RL aft red";
CM_ SG_ 1012 LS_rgbDoorRLAftGreen "LS ECU: rgb door RL aft green";
CM_ SG_ 1012 LS_rgbDoorRLAftBlue "LS ECU: rgb door RL aft blue";
CM_ SG_ 1012 LS_rgbDoorRRForeRed "LS ECU: rgb door RR fore red";
CM_ SG_ 1012 LS_rgbDoorRRForeGreen "LS ECU: rgb door RR fore green";
CM_ SG_ 1012 LS_rgbDoorRRForeBlue "LS ECU: rgb door RR fore blue";
CM_ SG_ 1012 LS_rgbDoorRRAftRed "LS ECU: rgb door RR aft red";
CM_ SG_ 1012 LS_rgbDoorRRAftGreen "LS ECU: rgb door RR aft green";
CM_ SG_ 1012 LS_rgbDoorRRAftBlue "LS ECU: rgb door RR aft blue";
CM_ SG_ 1012 LS_frontMatrix0 "LS ECU: front matrix0";
CM_ SG_ 1012 LS_frontMatrix1 "LS ECU: front matrix1";
CM_ SG_ 1012 LS_frontMatrix2 "LS ECU: front matrix2";
CM_ SG_ 1012 LS_frontMatrix3 "LS ECU: front matrix3";
CM_ SG_ 1012 LS_frontMatrix4 "LS ECU: front matrix4";
CM_ SG_ 1012 LS_frontMatrix5 "LS ECU: front matrix5";
CM_ SG_ 1012 LS_frontMatrix6 "LS ECU: front matrix6";
CM_ SG_ 1012 LS_frontMatrix7 "LS ECU: front matrix7";
CM_ SG_ 1012 LS_frontMatrix8 "LS ECU: front matrix8";
CM_ SG_ 1012 LS_frontMatrix9 "LS ECU: front matrix9";
CM_ SG_ 1012 LS_frontMatrix10 "LS ECU: front matrix10";
CM_ SG_ 1012 LS_frontMatrix11 "LS ECU: front matrix11";
CM_ SG_ 1012 LS_frontMatrix12 "LS ECU: front matrix12";
CM_ SG_ 1012 LS_frontMatrix13 "LS ECU: front matrix13";
CM_ SG_ 1012 LS_frontMatrix14 "LS ECU: front matrix14";
CM_ SG_ 1012 LS_frontMatrix15 "LS ECU: front matrix15";
CM_ SG_ 1012 LS_frontMatrix16 "LS ECU: front matrix16";
CM_ SG_ 1012 LS_frontMatrix17 "LS ECU: front matrix17";
CM_ SG_ 1012 LS_frontMatrix18 "LS ECU: front matrix18";
CM_ SG_ 1012 LS_frontMatrix19 "LS ECU: front matrix19";
CM_ SG_ 1012 LS_frontMatrix20 "LS ECU: front matrix20";
CM_ SG_ 1012 LS_frontMatrix21 "LS ECU: front matrix21";
CM_ SG_ 1012 LS_frontMatrix22 "LS ECU: front matrix22";
CM_ SG_ 1012 LS_frontMatrix23 "LS ECU: front matrix23";
CM_ SG_ 1012 LS_frontMatrix24 "LS ECU: front matrix24";
CM_ SG_ 1012 LS_frontMatrix25 "LS ECU: front matrix25";
CM_ SG_ 1012 LS_frontMatrix26 "LS ECU: front matrix26";
CM_ SG_ 1012 LS_frontMatrix27 "LS ECU: front matrix27";
CM_ SG_ 1012 LS_frontMatrix28 "LS ECU: front matrix28";
CM_ SG_ 1012 LS_frontMatrix29 "LS ECU: front matrix29";
CM_ SG_ 1012 LS_frontMatrix30 "LS ECU: front matrix30";
CM_ SG_ 1012 LS_frontMatrix31 "LS ECU: front matrix31";
CM_ SG_ 1012 LS_frontMatrix32 "LS ECU: front matrix32";
CM_ SG_ 1012 LS_frontMatrix33 "LS ECU: front matrix33";
CM_ SG_ 1012 LS_frontMatrix34 "LS ECU: front matrix34";
CM_ SG_ 1012 LS_frontMatrix35 "LS ECU: front matrix35";
CM_ SG_ 1012 LS_frontMatrix36 "LS ECU: front matrix36";
CM_ SG_ 1012 LS_frontMatrix37 "LS ECU: front matrix37";
CM_ SG_ 1012 LS_frontMatrix38 "LS ECU: front matrix38";
CM_ SG_ 1012 LS_frontMatrix39 "LS ECU: front matrix39";
CM_ SG_ 1012 LS_frontMatrix40 "LS ECU: front matrix40";
CM_ SG_ 1012 LS_frontMatrix41 "LS ECU: front matrix41";
CM_ SG_ 1012 LS_frontMatrix42 "LS ECU: front matrix42";
CM_ SG_ 1012 LS_frontMatrix43 "LS ECU: front matrix43";
CM_ SG_ 1012 LS_frontMatrix44 "LS ECU: front matrix44";
CM_ SG_ 1012 LS_frontMatrix45 "LS ECU: front matrix45";
CM_ SG_ 1012 LS_frontMatrix46 "LS ECU: front matrix46";
CM_ SG_ 1012 LS_frontMatrix47 "LS ECU: front matrix47";
CM_ SG_ 1012 LS_frontMatrix48 "LS ECU: front matrix48";
CM_ SG_ 1012 LS_frontMatrix49 "LS ECU: front matrix49";
CM_ SG_ 1012 LS_frontMatrix50 "LS ECU: front matrix50";
CM_ SG_ 1012 LS_frontMatrix51 "LS ECU: front matrix51";
CM_ SG_ 1012 LS_frontMatrix52 "LS ECU: front matrix52";
CM_ SG_ 1012 LS_frontMatrix53 "LS ECU: front matrix53";
CM_ SG_ 1012 LS_frontMatrix54 "LS ECU: front matrix54";
CM_ SG_ 1012 LS_frontMatrix55 "LS ECU: front matrix55";
CM_ SG_ 1012 LS_frontMatrix56 "LS ECU: front matrix56";
CM_ SG_ 1012 LS_frontMatrix57 "LS ECU: front matrix57";
CM_ SG_ 1012 LS_frontMatrix58 "LS ECU: front matrix58";
CM_ SG_ 1012 LS_frontMatrix59 "LS ECU: front matrix59";
CM_ SG_ 1012 LS_rearMatrix0 "LS ECU: rear matrix0";
CM_ SG_ 1012 LS_rearMatrix1 "LS ECU: rear matrix1";
CM_ SG_ 1012 LS_rearMatrix2 "LS ECU: rear matrix2";
CM_ SG_ 1012 LS_rearMatrix3 "LS ECU: rear matrix3";
CM_ SG_ 1012 LS_rearMatrix4 "LS ECU: rear matrix4";
CM_ SG_ 1012 LS_rearMatrix5 "LS ECU: rear matrix5";
CM_ SG_ 1012 LS_rearMatrix6 "LS ECU: rear matrix6";
CM_ SG_ 1012 LS_rearMatrix7 "LS ECU: rear matrix7";
CM_ SG_ 1012 LS_rearMatrix8 "LS ECU: rear matrix8";
CM_ SG_ 1012 LS_rearMatrix9 "LS ECU: rear matrix9";
CM_ SG_ 1012 LS_rearMatrix10 "LS ECU: rear matrix10";
CM_ SG_ 1012 LS_rearMatrix11 "LS ECU: rear matrix11";
CM_ SG_ 1012 LS_rearMatrix12 "LS ECU: rear matrix12";
CM_ SG_ 1012 LS_rearMatrix13 "LS ECU: rear matrix13";
CM_ SG_ 1012 LS_rearMatrix14 "LS ECU: rear matrix14";
CM_ SG_ 1012 LS_rearMatrix15 "LS ECU: rear matrix15";
CM_ SG_ 1012 LS_rearMatrix16 "LS ECU: rear matrix16";
CM_ SG_ 1012 LS_rearMatrix17 "LS ECU: rear matrix17";
CM_ SG_ 1012 LS_rearMatrix18 "LS ECU: rear matrix18";
CM_ SG_ 1012 LS_rearMatrix19 "LS ECU: rear matrix19";
CM_ SG_ 1012 LS_rearMatrix20 "LS ECU: rear matrix20";
CM_ SG_ 1012 LS_rearMatrix21 "LS ECU: rear matrix21";
CM_ SG_ 1012 LS_rearMatrix22 "LS ECU: rear matrix22";
CM_ SG_ 1012 LS_rearMatrix23 "LS ECU: rear matrix23";
CM_ SG_ 1012 LS_rearMatrix24 "LS ECU: rear matrix24";
CM_ SG_ 1012 LS_rearMatrix25 "LS ECU: rear matrix25";
CM_ SG_ 1012 LS_rearMatrix26 "LS ECU: rear matrix26";
CM_ SG_ 1012 LS_rearMatrix27 "LS ECU: rear matrix27";
CM_ SG_ 1012 LS_rearMatrix28 "LS ECU: rear matrix28";
CM_ SG_ 1012 LS_rearMatrix29 "LS ECU: rear matrix29";
CM_ SG_ 1012 LS_rearMatrix30 "LS ECU: rear matrix30";
CM_ SG_ 1012 LS_rearMatrix31 "LS ECU: rear matrix31";
CM_ SG_ 1012 LS_rearMatrix32 "LS ECU: rear matrix32";
CM_ SG_ 1012 LS_rearMatrix33 "LS ECU: rear matrix33";
CM_ SG_ 1012 LS_rearMatrix34 "LS ECU: rear matrix34";
CM_ SG_ 1012 LS_rearMatrix35 "LS ECU: rear matrix35";
CM_ SG_ 1012 LS_rearMatrix36 "LS ECU: rear matrix36";
CM_ SG_ 1012 LS_rearMatrix37 "LS ECU: rear matrix37";
CM_ SG_ 1012 LS_rearMatrix38 "LS ECU: rear matrix38";
CM_ SG_ 1012 LS_rearMatrix39 "LS ECU: rear matrix39";
CM_ SG_ 1012 LS_rearMatrix40 "LS ECU: rear matrix40";
CM_ SG_ 1012 LS_rearMatrix41 "LS ECU: rear matrix41";
CM_ SG_ 1012 LS_rearMatrix42 "LS ECU: rear matrix42";
CM_ SG_ 1012 LS_rearMatrix43 "LS ECU: rear matrix43";
CM_ SG_ 1012 LS_rearMatrix44 "LS ECU: rear matrix44";
CM_ SG_ 1012 LS_rearMatrix45 "LS ECU: rear matrix45";
CM_ SG_ 1012 LS_rearMatrix46 "LS ECU: rear matrix46";
CM_ SG_ 1012 LS_rearMatrix47 "LS ECU: rear matrix47";
CM_ SG_ 1012 LS_rearMatrix48 "LS ECU: rear matrix48";
CM_ SG_ 1012 LS_rearMatrix49 "LS ECU: rear matrix49";
CM_ SG_ 1012 LS_rearMatrix50 "LS ECU: rear matrix50";
CM_ SG_ 1012 LS_rearMatrix51 "LS ECU: rear matrix51";
CM_ SG_ 1012 LS_rearMatrix52 "LS ECU: rear matrix52";
CM_ SG_ 1012 LS_rearMatrix53 "LS ECU: rear matrix53";
CM_ SG_ 1012 LS_rearMatrix54 "LS ECU: rear matrix54";
CM_ SG_ 1012 LS_rearMatrix55 "LS ECU: rear matrix55";
CM_ SG_ 1012 LS_rearMatrix56 "LS ECU: rear matrix56";
CM_ SG_ 1012 LS_rearMatrix57 "LS ECU: rear matrix57";
CM_ SG_ 1012 LS_rearMatrix58 "LS ECU: rear matrix58";
CM_ SG_ 1012 LS_rearMatrix59 "LS ECU: rear matrix59";
CM_ SG_ 1012 LS_offroadLightBar0 "LS ECU: offroad light bar0";
CM_ SG_ 1012 LS_offroadLightBar1 "LS ECU: offroad light bar1";
CM_ SG_ 1012 LS_offroadLightBar2 "LS ECU: offroad light bar2";
CM_ SG_ 1012 LS_offroadLightBar3 "LS ECU: offroad light bar3";
CM_ SG_ 1012 LS_offroadLightBar4 "LS ECU: offroad light bar4";
CM_ SG_ 1012 LS_offroadLightBar5 "LS ECU: offroad light bar5";
CM_ BO_ 1152 "External diagnostic tester message: iso tp pipe VCSEC; forwarded onto this bus by the gateway; frame length from the layout, not yet observed on a vehicle bus";
CM_ SG_ 1152 ODIN_IsoTpPipeVCSEC0 "External diagnostic tester: iso tp pipe VCSEC0";
CM_ SG_ 1152 ODIN_IsoTpPipeVCSEC1 "External diagnostic tester: iso tp pipe VCSEC1";
CM_ SG_ 1152 ODIN_IsoTpPipeVCSEC2 "External diagnostic tester: iso tp pipe VCSEC2";
CM_ SG_ 1152 ODIN_IsoTpPipeVCSEC3 "External diagnostic tester: iso tp pipe VCSEC3";
CM_ SG_ 1152 ODIN_IsoTpPipeVCSEC4 "External diagnostic tester: iso tp pipe VCSEC4";
CM_ SG_ 1152 ODIN_IsoTpPipeVCSEC5 "External diagnostic tester: iso tp pipe VCSEC5";
CM_ SG_ 1152 ODIN_IsoTpPipeVCSEC6 "External diagnostic tester: iso tp pipe VCSEC6";
CM_ SG_ 1152 ODIN_IsoTpPipeVCSEC7 "External diagnostic tester: iso tp pipe VCSEC7";
BA_DEF_ BO_ "GenMsgCycleTime" INT 0 3600000;
BA_DEF_ BO_ "GenMsgSendType" ENUM "Cyclic","NotUsed","NotUsed","NotUsed","NotUsed","NotUsed","NotUsed","IfActive","NoMsgSendType","NotUsed";
BA_DEF_ BO_ "VFrameFormat" ENUM "StandardCAN","ExtendedCAN","reserved","J1939PG","reserved","reserved","reserved","reserved","reserved","reserved","reserved","reserved","reserved","reserved","StandardCAN_FD","ExtendedCAN_FD";
BA_DEF_ BO_ "CANFD_BRS" ENUM "0","1";
BA_DEF_ SG_ "GenSigSNA" STRING;
BA_DEF_ SG_ "SystemSignalLongSymbol" STRING;
BA_DEF_ SG_ "Confidence" ENUM "validated","plausible","layout-only","contradicted";
BA_DEF_DEF_ "GenMsgCycleTime" 0;
BA_DEF_DEF_ "GenMsgSendType" "NoMsgSendType";
BA_DEF_DEF_ "VFrameFormat" "StandardCAN";
BA_DEF_DEF_ "CANFD_BRS" "1";
BA_DEF_DEF_ "GenSigSNA" "";
BA_DEF_DEF_ "SystemSignalLongSymbol" "";
BA_DEF_DEF_ "Confidence" "layout-only";
BA_ "GenMsgCycleTime" BO_ 938 1000;
BA_ "GenMsgSendType" BO_ 938 0;
BA_ "GenMsgCycleTime" BO_ 522 1000;
BA_ "GenMsgSendType" BO_ 522 0;
BA_ "GenMsgCycleTime" BO_ 1962 1000;
BA_ "GenMsgSendType" BO_ 1962 0;
BA_ "GenMsgCycleTime" BO_ 1666 100;
BA_ "GenMsgSendType" BO_ 1666 0;
BA_ "GenMsgCycleTime" BO_ 554 100;
BA_ "GenMsgSendType" BO_ 554 0;
BA_ "GenMsgCycleTime" BO_ 784 10000;
BA_ "GenMsgSendType" BO_ 784 0;
BA_ "GenMsgCycleTime" BO_ 1914 1000;
BA_ "GenMsgSendType" BO_ 1914 0;
BA_ "GenMsgCycleTime" BO_ 952 100;
BA_ "GenMsgSendType" BO_ 952 0;
BA_ "GenMsgCycleTime" BO_ 941 10000;
BA_ "GenMsgSendType" BO_ 941 0;
BA_ "GenMsgCycleTime" BO_ 667 100;
BA_ "GenMsgSendType" BO_ 667 0;
BA_ "GenMsgCycleTime" BO_ 536 100;
BA_ "GenMsgSendType" BO_ 536 0;
BA_ "GenMsgCycleTime" BO_ 670 100;
BA_ "GenMsgSendType" BO_ 670 0;
BA_ "GenMsgCycleTime" BO_ 664 100;
BA_ "GenMsgSendType" BO_ 664 0;
BA_ "Confidence" SG_ 1290 HVP_alertID 1;
BA_ "Confidence" SG_ 1290 HVP_alertSet 1;
BA_ "Confidence" SG_ 1290 HVP_a005_current 1;
BA_ "Confidence" SG_ 1290 HVP_a006_current 1;
BA_ "Confidence" SG_ 1290 HVP_a007_current 1;
BA_ "Confidence" SG_ 1290 HVP_a008_temperature 1;
BA_ "Confidence" SG_ 1290 HVP_a009_brickVoltage 1;
BA_ "Confidence" SG_ 1290 HVP_a010_brickVoltage 1;
BA_ "Confidence" SG_ 1290 HVP_a012_bmbCommStatusTypeA 1;
BA_ "Confidence" SG_ 1290 HVP_a012_bmbCommStatusTypeB 1;
BA_ "Confidence" SG_ 1290 HVP_a013_bmbCommStatusTypeA 1;
BA_ "Confidence" SG_ 1290 HVP_a013_bmbCommStatusTypeB 1;
BA_ "Confidence" SG_ 1290 HVP_a013_bmbChainBreakType 1;
BA_ "Confidence" SG_ 1290 HVP_a018_dcLinkVoltage 1;
BA_ "Confidence" SG_ 1290 HVP_a018_battery12V 1;
BA_ "SystemSignalLongSymbol" SG_ 1290 HVP_a018_remainingPcsPowerCycles "HVP_a018_remainingPcsPowerCyclesAllowed";
BA_ "SystemSignalLongSymbol" SG_ 1290 HVP_a018_remainingPcsRecoveriesA "HVP_a018_remainingPcsRecoveriesAllowed";
BA_ "SystemSignalLongSymbol" SG_ 1290 HVP_a018_hvcHardwareSupportsCycl "HVP_a018_hvcHardwareSupportsCycling";
BA_ "SystemSignalLongSymbol" SG_ 1290 HVP_a018_pcsHardwareOkToBePowerC "HVP_a018_pcsHardwareOkToBePowerCycled";
BA_ "Confidence" SG_ 1290 HVP_a020_energyReserveV 1;
BA_ "GenSigSNA" SG_ 1290 HVP_a020_energyReserveV "65535";
BA_ "Confidence" SG_ 1290 HVP_a020_shuntCurrentAux 1;
BA_ "GenSigSNA" SG_ 1290 HVP_a020_shuntCurrentAux "32768";
BA_ "Confidence" SG_ 1290 HVP_a020_shuntTemperature 1;
BA_ "GenSigSNA" SG_ 1290 HVP_a020_shuntTemperature "32768";
BA_ "Confidence" SG_ 1290 HVP_a021_pyroStatus 1;
BA_ "SystemSignalLongSymbol" SG_ 1290 HVP_a021_HighSideSwitchTestFaile "HVP_a021_HighSideSwitchTestFailed";
BA_ "Confidence" SG_ 1290 HVP_a021_SquibResistance 1;
BA_ "GenSigSNA" SG_ 1290 HVP_a021_SquibResistance "65535";
BA_ "Confidence" SG_ 1290 HVP_a021_Aout 1;
BA_ "GenSigSNA" SG_ 1290 HVP_a021_Aout "16383";
BA_ "Confidence" SG_ 1290 HVP_a022_pyroStatus 1;
BA_ "Confidence" SG_ 1290 HVP_a022_Aout 1;
BA_ "GenSigSNA" SG_ 1290 HVP_a022_Aout "16383";
BA_ "Confidence" SG_ 1290 HVP_a022_SquibResistance 1;
BA_ "GenSigSNA" SG_ 1290 HVP_a022_SquibResistance "65535";
BA_ "Confidence" SG_ 1290 HVP_a024_voltage 1;
BA_ "Confidence" SG_ 1290 HVP_a025_voltage1 1;
BA_ "Confidence" SG_ 1290 HVP_a025_voltage2 1;
BA_ "Confidence" SG_ 1290 HVP_a025_packVoltage 1;
BA_ "Confidence" SG_ 1290 HVP_a026_hvilStatus 1;
BA_ "GenSigSNA" SG_ 1290 HVP_a026_hvilStatus "14";
BA_ "Confidence" SG_ 1290 HVP_a026_inputVoltage 1;
BA_ "Confidence" SG_ 1290 HVP_a026_outputVoltage 1;
BA_ "Confidence" SG_ 1290 HVP_a026_internalVoltage 1;
BA_ "GenSigSNA" SG_ 1290 HVP_a026_internalVoltage "255";
BA_ "Confidence" SG_ 1290 HVP_a026_dirVoltage 1;
BA_ "GenSigSNA" SG_ 1290 HVP_a026_dirVoltage "255";
BA_ "Confidence" SG_ 1290 HVP_a026_difVoltage 1;
BA_ "GenSigSNA" SG_ 1290 HVP_a026_difVoltage "255";
BA_ "Confidence" SG_ 1290 HVP_a028_packVoltage 1;
BA_ "Confidence" SG_ 1290 HVP_a028_sumOfBrickV 1;
BA_ "Confidence" SG_ 1290 HVP_a030_packPositiveLinkV 1;
BA_ "Confidence" SG_ 1290 HVP_a030_dcPositiveLinkV 1;
BA_ "Confidence" SG_ 1290 HVP_a031_packNegativeLinkV 1;
BA_ "Confidence" SG_ 1290 HVP_a031_dcNegativeLinkV 1;
BA_ "Confidence" SG_ 1290 HVP_a033_contactorPowerV 1;
BA_ "Confidence" SG_ 1290 HVP_a033_coilCurrent 1;
BA_ "Confidence" SG_ 1290 HVP_a033_pwmDutyCylePositive 1;
BA_ "Confidence" SG_ 1290 HVP_a033_pwmDutyCyleNegative 1;
BA_ "Confidence" SG_ 1290 HVP_a035_contactorPowerV 1;
BA_ "Confidence" SG_ 1290 HVP_a035_coilCurrent 1;
BA_ "Confidence" SG_ 1290 HVP_a035_pwmDutyCylePositive 1;
BA_ "Confidence" SG_ 1290 HVP_a035_pwmDutyCyleNegative 1;
BA_ "Confidence" SG_ 1290 HVP_a036_pyroFiringHandle 1;
BA_ "Confidence" SG_ 1290 HVP_a037_pyroFiringHandle 1;
BA_ "Confidence" SG_ 1290 HVP_a040_powerVoltage 1;
BA_ "Confidence" SG_ 1290 HVP_a040_coilCurrent 1;
BA_ "Confidence" SG_ 1290 HVP_a040_posCtrVoltageDrop 1;
BA_ "Confidence" SG_ 1290 HVP_a040_negCtrVoltageDrop 1;
BA_ "Confidence" SG_ 1290 HVP_a045_dcLinkVoltage 1;
BA_ "Confidence" SG_ 1290 HVP_a046_shuntCurrent 1;
BA_ "Confidence" SG_ 1290 HVP_a046_shuntTemperature 1;
BA_ "Confidence" SG_ 1290 HVP_a046_asicTemperature 1;
BA_ "Confidence" SG_ 1290 HVP_a047_shuntCurrent 1;
BA_ "Confidence" SG_ 1290 HVP_a047_auxCurrent 1;
BA_ "Confidence" SG_ 1290 HVP_a049_contactorPowerV 1;
BA_ "Confidence" SG_ 1290 HVP_a049_coilCurrent 1;
BA_ "Confidence" SG_ 1290 HVP_a049_posCtrState 1;
BA_ "GenSigSNA" SG_ 1290 HVP_a049_posCtrState "0";
BA_ "Confidence" SG_ 1290 HVP_a049_negCtrState 1;
BA_ "GenSigSNA" SG_ 1290 HVP_a049_negCtrState "0";
BA_ "Confidence" SG_ 1290 HVP_a050_contactorPowerV 1;
BA_ "Confidence" SG_ 1290 HVP_a050_coilCurrent 1;
BA_ "Confidence" SG_ 1290 HVP_a050_posCtrState 1;
BA_ "GenSigSNA" SG_ 1290 HVP_a050_posCtrState "0";
BA_ "Confidence" SG_ 1290 HVP_a050_negCtrState 1;
BA_ "GenSigSNA" SG_ 1290 HVP_a050_negCtrState "0";
BA_ "Confidence" SG_ 1290 HVP_a051_shuntTemperature 1;
BA_ "GenSigSNA" SG_ 1290 HVP_a051_shuntTemperature "32768";
BA_ "Confidence" SG_ 1290 HVP_a051_shuntCurrent 1;
BA_ "GenSigSNA" SG_ 1290 HVP_a051_shuntCurrent "32768";
BA_ "Confidence" SG_ 1290 HVP_a051_energyReserveV 1;
BA_ "GenSigSNA" SG_ 1290 HVP_a051_energyReserveV "65535";
BA_ "Confidence" SG_ 1290 HVP_a053_packVoltage 1;
BA_ "Confidence" SG_ 1290 HVP_a053_dcLinkVoltage 1;
BA_ "Confidence" SG_ 1290 HVP_a056_diagnosis 1;
BA_ "GenSigSNA" SG_ 1290 HVP_a056_diagnosis "0";
BA_ "Confidence" SG_ 1290 HVP_a056_shuntCurrent 1;
BA_ "Confidence" SG_ 1290 HVP_a056_posPackContactorState 1;
BA_ "GenSigSNA" SG_ 1290 HVP_a056_posPackContactorState "0";
BA_ "Confidence" SG_ 1290 HVP_a056_negPackContactorState 1;
BA_ "GenSigSNA" SG_ 1290 HVP_a056_negPackContactorState "0";
BA_ "Confidence" SG_ 1290 HVP_a056_posFcContactorState 1;
BA_ "GenSigSNA" SG_ 1290 HVP_a056_posFcContactorState "0";
BA_ "Confidence" SG_ 1290 HVP_a056_negFcContactorState 1;
BA_ "GenSigSNA" SG_ 1290 HVP_a056_negFcContactorState "0";
BA_ "Confidence" SG_ 1290 HVP_a058_VrefSample 1;
BA_ "Confidence" SG_ 1290 HVP_a058_VrefStatus 1;
BA_ "Confidence" SG_ 1290 HVP_a058_VrefType 1;
BA_ "Confidence" SG_ 1290 HVP_a060_stackVoltage 1;
BA_ "Confidence" SG_ 1290 HVP_a060_sumBrickVoltage 1;
BA_ "Confidence" SG_ 1290 HVP_a067_hvilTypeFromHvp 1;
BA_ "Confidence" SG_ 1290 HVP_a067_hvilTypeFromGateway 1;
BA_ "Confidence" SG_ 1290 HVP_a068_shuntTemperature 1;
BA_ "GenSigSNA" SG_ 1290 HVP_a068_shuntTemperature "32768";
BA_ "Confidence" SG_ 1290 HVP_a068_shuntCurrent 1;
BA_ "GenSigSNA" SG_ 1290 HVP_a068_shuntCurrent "32768";
BA_ "Confidence" SG_ 1290 HVP_a068_energyReserveV 1;
BA_ "GenSigSNA" SG_ 1290 HVP_a068_energyReserveV "65535";
BA_ "Confidence" SG_ 938 HVP_matrixIndex 1;
BA_ "Confidence" SG_ 938 HVP_w001_WatchdogReset 1;
BA_ "Confidence" SG_ 938 HVP_w002_UnusedAlert2 1;
BA_ "Confidence" SG_ 938 HVP_w003_SwAssertion 1;
BA_ "Confidence" SG_ 938 HVP_w004_CrashEvent 1;
BA_ "Confidence" SG_ 938 HVP_w005_OverDchgCurrentFault 1;
BA_ "Confidence" SG_ 938 HVP_w006_OverChargeCurrentFault 1;
BA_ "Confidence" SG_ 938 HVP_w007_OverCurrentFault 1;
BA_ "Confidence" SG_ 938 HVP_w008_OverTemperatureFault 1;
BA_ "Confidence" SG_ 938 HVP_w009_OverVoltageFault 1;
BA_ "Confidence" SG_ 938 HVP_w010_UnderVoltageFault 1;
BA_ "Confidence" SG_ 938 HVP_w011_PrimaryBmbMiaFault 1;
BA_ "Confidence" SG_ 938 HVP_w012_BmbDataIntegrityLoss 1;
BA_ "Confidence" SG_ 938 HVP_w013_BmbCommunication 1;
BA_ "Confidence" SG_ 938 HVP_w014_BmsMiaOnHviFault 1;
BA_ "Confidence" SG_ 938 HVP_w015_CpMiaFault 1;
BA_ "Confidence" SG_ 938 HVP_w016_PcsMiaFault 1;
BA_ "Confidence" SG_ 938 HVP_w017_GtwMiaFault 1;
BA_ "Confidence" SG_ 938 HVP_w018_powerCyclingPcs 1;
BA_ "Confidence" SG_ 938 HVP_w019_CpFault 1;
BA_ "Confidence" SG_ 938 HVP_w020_ShuntHwMiaFault 1;
BA_ "Confidence" SG_ 938 HVP_w021_PyroMiaFault 1;
BA_ "Confidence" SG_ 938 HVP_w022_PyroMiaWarning 1;
BA_ "Confidence" SG_ 938 HVP_w023_BmbResetRecovery 1;
BA_ "Confidence" SG_ 938 HVP_w024_Supply12vFault 1;
BA_ "Confidence" SG_ 938 HVP_w025_VerSupplyFault 1;
BA_ "Confidence" SG_ 938 HVP_w026_HvilFault 1;
BA_ "Confidence" SG_ 938 HVP_w027_BmsMiaOnHvsFault 1;
BA_ "Confidence" SG_ 938 HVP_w028_PackVoltMismatchFault 1;
BA_ "Confidence" SG_ 938 HVP_w029_EnsMiaFault 1;
BA_ "Confidence" SG_ 938 HVP_w030_PackPosCtrArcFault 1;
BA_ "Confidence" SG_ 938 HVP_w031_packNegCtrArcFault 1;
BA_ "Confidence" SG_ 938 HVP_w032_ShuntHwAndBmsMiaFault 1;
BA_ "Confidence" SG_ 938 HVP_w033_fcContHwFault 1;
BA_ "Confidence" SG_ 938 HVP_w034_cpMismatchFault 1;
BA_ "Confidence" SG_ 938 HVP_w035_packContHwFault 1;
BA_ "Confidence" SG_ 938 HVP_w036_pyroFuseBlown 1;
BA_ "Confidence" SG_ 938 HVP_w037_pyroFuseFailedToBlow 1;
BA_ "Confidence" SG_ 938 HVP_w038_CpilFault 1;
BA_ "Confidence" SG_ 938 HVP_w039_PackContactorFellOpen 1;
BA_ "Confidence" SG_ 938 HVP_w040_FcContactorFellOpen 1;
BA_ "Confidence" SG_ 938 HVP_w041_packCtrCloseBlocked 1;
BA_ "Confidence" SG_ 938 HVP_w042_fcCtrCloseBlocked 1;
BA_ "Confidence" SG_ 938 HVP_w043_packContactorForceOpen 1;
BA_ "Confidence" SG_ 938 HVP_w044_fcContactorForceOpen 1;
BA_ "Confidence" SG_ 938 HVP_w045_dcLinkOverVoltage 1;
BA_ "Confidence" SG_ 938 HVP_w046_shuntOverTemperature 1;
BA_ "Confidence" SG_ 938 HVP_w047_passivePyroDeploy 1;
BA_ "Confidence" SG_ 938 HVP_w048_swUnsupportedBmbAsicTyp 1;
BA_ "SystemSignalLongSymbol" SG_ 938 HVP_w048_swUnsupportedBmbAsicTyp "HVP_w048_swUnsupportedBmbAsicType";
BA_ "Confidence" SG_ 938 HVP_w049_packCtrCloseFailed 1;
BA_ "Confidence" SG_ 938 HVP_w050_fcCtrCloseFailed 1;
BA_ "Confidence" SG_ 938 HVP_w051_shuntThermistorMia 1;
BA_ "Confidence" SG_ 938 HVP_w052_BmbStatusRegError 1;
BA_ "Confidence" SG_ 938 HVP_w053_hvVoltageSensorRational 1;
BA_ "SystemSignalLongSymbol" SG_ 938 HVP_w053_hvVoltageSensorRational "HVP_w053_hvVoltageSensorRationality";
BA_ "Confidence" SG_ 938 HVP_w054_swMissingConfigBlock 1;
BA_ "Confidence" SG_ 938 HVP_w055_swMissingPartNumber 1;
BA_ "Confidence" SG_ 938 HVP_w056_contactorFailedToOpen 1;
BA_ "Confidence" SG_ 938 HVP_w057_BatmanDiagnosticsError 1;
BA_ "Confidence" SG_ 938 HVP_w058_BmbVrefBad 1;
BA_ "Confidence" SG_ 938 HVP_w059_BmbVrefWarning 1;
BA_ "Confidence" SG_ 938 HVP_w060_StackVoltageSense 1;
BA_ "Confidence" SG_ 938 HVP_w061_ShuntCurrentRationality 1;
BA_ "Confidence" SG_ 938 HVP_w062_BmbOtpConfigError 1;
BA_ "Confidence" SG_ 938 HVP_w063_BmbBrickVRationality 1;
BA_ "Confidence" SG_ 938 HVP_w064_BmbAuxVRationality 1;
BA_ "Confidence" SG_ 938 HVP_w065_FastOpenVshDetected 1;
BA_ "Confidence" SG_ 938 HVP_w067_HvilCalNodeMismatch 1;
BA_ "Confidence" SG_ 938 HVP_w068_shuntUnexpectedThermist 1;
BA_ "SystemSignalLongSymbol" SG_ 938 HVP_w068_shuntUnexpectedThermist "HVP_w068_shuntUnexpectedThermistor";
BA_ "Confidence" SG_ 938 HVP_w069_hviCanFrameRxDropped 1;
BA_ "Confidence" SG_ 938 HVP_w070_hvsCanFrameRxDropped 1;
BA_ "Confidence" SG_ 938 HVP_w071_PassivePyroVrefRational 1;
BA_ "SystemSignalLongSymbol" SG_ 938 HVP_w071_PassivePyroVrefRational "HVP_w071_PassivePyroVrefRationality";
BA_ "Confidence" SG_ 522 HVP_packContNegativeState 0;
BA_ "GenSigSNA" SG_ 522 HVP_packContNegativeState "0";
BA_ "Confidence" SG_ 522 HVP_packContPositiveState 0;
BA_ "GenSigSNA" SG_ 522 HVP_packContPositiveState "0";
BA_ "Confidence" SG_ 522 HVP_fcContPositiveAuxOpen 0;
BA_ "Confidence" SG_ 522 HVP_fcContNegativeAuxOpen 0;
BA_ "Confidence" SG_ 522 HVP_packContactorSetState 0;
BA_ "GenSigSNA" SG_ 522 HVP_packContactorSetState "0";
BA_ "Confidence" SG_ 522 HVP_fcContNegativeState 0;
BA_ "GenSigSNA" SG_ 522 HVP_fcContNegativeState "0";
BA_ "Confidence" SG_ 522 HVP_contactorsBlocked 0;
BA_ "Confidence" SG_ 522 HVP_fcContPositiveState 0;
BA_ "GenSigSNA" SG_ 522 HVP_fcContPositiveState "0";
BA_ "Confidence" SG_ 522 HVP_fcContactorSetState 0;
BA_ "GenSigSNA" SG_ 522 HVP_fcContactorSetState "0";
BA_ "Confidence" SG_ 522 HVP_fcCtrsRequestStatus 0;
BA_ "Confidence" SG_ 522 HVP_fcCtrsResetRequestRequired 0;
BA_ "Confidence" SG_ 522 HVP_fcCtrsOpenNowRequested 0;
BA_ "Confidence" SG_ 522 HVP_fcCtrsOpenRequested 0;
BA_ "Confidence" SG_ 522 HVP_fcCtrsClosingAllowed 0;
BA_ "Confidence" SG_ 522 HVP_packCtrsRequestStatus 0;
BA_ "Confidence" SG_ 522 HVP_packCtrsResetRequestRequired 0;
BA_ "Confidence" SG_ 522 HVP_packCtrsOpenNowRequested 0;
BA_ "Confidence" SG_ 522 HVP_packCtrsOpenRequested 0;
BA_ "Confidence" SG_ 522 HVP_packCtrsClosingAllowed 0;
BA_ "Confidence" SG_ 522 HVP_dcLinkAllowedToEnergize 0;
BA_ "Confidence" SG_ 522 HVP_pyroTestInProgress 0;
BA_ "Confidence" SG_ 522 HVP_hvilDiag 0;
BA_ "GenSigSNA" SG_ 522 HVP_hvilDiag "14";
BA_ "Confidence" SG_ 522 HVP_fcLinkAllowedToEnergize 0;
BA_ "Confidence" SG_ 1962 HVP_debugMessageMultiplexer 1;
BA_ "Confidence" SG_ 1962 HVP_ecuLogUploadRequest 0;
BA_ "Confidence" SG_ 1962 HVP_dcLinkVoltage 0;
BA_ "Confidence" SG_ 1962 HVP_packVoltage 0;
BA_ "Confidence" SG_ 1962 HVP_fcLinkVoltage 0;
BA_ "Confidence" SG_ 1962 HVP_10HzTask_stackUsage 0;
BA_ "Confidence" SG_ 1962 HVP_packContVoltage 0;
BA_ "Confidence" SG_ 1962 HVP_packNegativeV 0;
BA_ "Confidence" SG_ 1962 HVP_packPositiveV 0;
BA_ "Confidence" SG_ 1962 HVP_pyroAnalog 3;
BA_ "Confidence" SG_ 1962 HVP_shuntSetTCRCoeffA 0;
BA_ "Confidence" SG_ 1962 HVP_shuntSetTCRCoeffB 0;
BA_ "Confidence" SG_ 1962 HVP_shuntSetTCRCoeffC 0;
BA_ "Confidence" SG_ 1962 HVP_shuntSetTCRCoeffD 0;
BA_ "Confidence" SG_ 1962 HVP_fcContCoilCurrent 0;
BA_ "Confidence" SG_ 1962 HVP_fcContVoltage 0;
BA_ "Confidence" SG_ 1962 HVP_hvilInVoltage 0;
BA_ "Confidence" SG_ 1962 HVP_hvilOutVoltage 0;
BA_ "Confidence" SG_ 1962 HVP_shuntGainInvalidCountDbg 0;
BA_ "Confidence" SG_ 1962 HVP_passivePyroRefVoltageMax 0;
BA_ "GenSigSNA" SG_ 1962 HVP_passivePyroRefVoltageMax "1023";
BA_ "Confidence" SG_ 1962 HVP_passivePyroRefVoltageMin 0;
BA_ "GenSigSNA" SG_ 1962 HVP_passivePyroRefVoltageMin "1023";
BA_ "Confidence" SG_ 1962 HVP_packContCoilCurrent 0;
BA_ "Confidence" SG_ 1962 HVP_battery12V 0;
BA_ "Confidence" SG_ 1962 HVP_fcLinkPositiveV 0;
BA_ "Confidence" SG_ 1666 HVP_packContactorHwFault 1;
BA_ "Confidence" SG_ 1666 HVP_fcContactorHwFault 1;
BA_ "Confidence" SG_ 1666 HVP_hvilStatus 1;
BA_ "Confidence" SG_ 554 HVP_dcLinkVoltageRequest 0;
BA_ "Confidence" SG_ 554 HVP_pcsControlRequest 0;
BA_ "Confidence" SG_ 554 HVP_pcsChargeHwEnabled 0;
BA_ "Confidence" SG_ 554 HVP_pcsDcdcHwEnabled 0;
BA_ "Confidence" SG_ 554 HVP_dcLinkVoltageFiltered 0;
BA_ "GenSigSNA" SG_ 554 HVP_dcLinkVoltageFiltered "1498";
BA_ "Confidence" SG_ 784 HVP_infoIndex 1;
BA_ "Confidence" SG_ 784 HVP_buildType 0;
BA_ "Confidence" SG_ 784 HVP_buildConfigId 0;
BA_ "Confidence" SG_ 784 HVP_hardwareId 0;
BA_ "Confidence" SG_ 784 HVP_componentId 0;
BA_ "Confidence" SG_ 784 HVP_pcbaId 0;
BA_ "Confidence" SG_ 784 HVP_assemblyId 0;
BA_ "Confidence" SG_ 784 HVP_usageId 0;
BA_ "Confidence" SG_ 784 HVP_subUsageId 0;
BA_ "Confidence" SG_ 784 HVP_platformType 0;
BA_ "Confidence" SG_ 784 HVP_appCrc 0;
BA_ "Confidence" SG_ 784 HVP_appGitHash 0;
BA_ "Confidence" SG_ 784 HVP_bootGitHash 0;
BA_ "Confidence" SG_ 784 HVP_bootUdsProtoVersion 0;
BA_ "Confidence" SG_ 784 HVP_bootCrc 0;
BA_ "Confidence" SG_ 1914 HVP_log1HzIndex 1;
BA_ "Confidence" SG_ 1914 HVP_bmbAsicType 0;
BA_ "Confidence" SG_ 1914 HVP_shuntCurrentAuxLog 0;
BA_ "Confidence" SG_ 1914 HVP_pyroSquibResistance 0;
BA_ "GenSigSNA" SG_ 1914 HVP_pyroSquibResistance "65535";
BA_ "Confidence" SG_ 1914 HVP_shuntAsicChipXCoordinate 0;
BA_ "Confidence" SG_ 1914 HVP_shuntAsicChipYCoordinate 0;
BA_ "Confidence" SG_ 1914 HVP_hvilCalType 0;
BA_ "Confidence" SG_ 1914 HVP_gpioPcsDcdcPwmEnable 0;
BA_ "Confidence" SG_ 1914 HVP_gpioPcsChargePwmEnable 0;
BA_ "Confidence" SG_ 1914 HVP_gpioPcsEnable 0;
BA_ "Confidence" SG_ 1914 HVP_shuntAsicChipWaferNumber 0;
BA_ "Confidence" SG_ 1914 HVP_energyReserveMin 0;
BA_ "Confidence" SG_ 1914 HVP_energyReserveMax 0;
BA_ "Confidence" SG_ 1914 HVP_energyReserveAvg 0;
BA_ "Confidence" SG_ 1553 HVP_udsResponseData 1;
BA_ "Confidence" SG_ 1208 ICR_alertID 1;
BA_ "Confidence" SG_ 1208 ICR_alertState 1;
BA_ "SystemSignalLongSymbol" SG_ 1208 ICR_a001_watchdogTaskSentinelInt "ICR_a001_watchdogTaskSentinelInterface";
BA_ "SystemSignalLongSymbol" SG_ 1208 ICR_a001_watchdogTaskSentinelMod "ICR_a001_watchdogTaskSentinelModeChange";
BA_ "Confidence" SG_ 1208 ICR_a059_voltageDrop 1;
BA_ "Confidence" SG_ 1208 ICR_a059_resistanceEstimate 1;
BA_ "Confidence" SG_ 1208 ICR_a059_current 1;
BA_ "Confidence" SG_ 1208 ICR_a063_ADCVoltage 1;
BA_ "Confidence" SG_ 1208 ICR_a133_nearClutter 1;
BA_ "Confidence" SG_ 1208 ICR_a133_farClutter 1;
BA_ "Confidence" SG_ 1208 ICR_a137_nearClutter 1;
BA_ "Confidence" SG_ 1208 ICR_a137_farClutter 1;
BA_ "Confidence" SG_ 1208 ICR_a139_nearClutter 1;
BA_ "Confidence" SG_ 1208 ICR_a139_farClutter 1;
BA_ "SystemSignalLongSymbol" SG_ 1208 ICR_a141_calDataNotCalibratedOrP "ICR_a141_calDataNotCalibratedOrProcessing";
BA_ "SystemSignalLongSymbol" SG_ 1208 ICR_a141_calDataValRXPhaseAboveM "ICR_a141_calDataValRXPhaseAboveMax";
BA_ "SystemSignalLongSymbol" SG_ 1208 ICR_a141_calDataValRXPhaseMissin "ICR_a141_calDataValRXPhaseMissingUnitMag";
BA_ "SystemSignalLongSymbol" SG_ 1208 ICR_a141_calDataValRangeBiasAbov "ICR_a141_calDataValRangeBiasAboveMax";
BA_ "Confidence" SG_ 952 ICR_matrixIndex 1;
BA_ "SystemSignalLongSymbol" SG_ 952 ICR_a139_AbnormalBlockageDetecte "ICR_a139_AbnormalBlockageDetected";
BA_ "SystemSignalLongSymbol" SG_ 952 ICR_a140_OccupancyExceptionEncou "ICR_a140_OccupancyExceptionEncountered";
BA_ "SystemSignalLongSymbol" SG_ 952 ICR_a144_OccupancyNotificationAl "ICR_a144_OccupancyNotificationAlert";
BA_ "Confidence" SG_ 941 ICR_infoIndex 1;
BA_ "Confidence" SG_ 941 ICR_infoBuildType 0;
BA_ "Confidence" SG_ 941 ICR_infoPcbaId 0;
BA_ "Confidence" SG_ 941 ICR_infoAssemblyId 0;
BA_ "Confidence" SG_ 941 ICR_infoUsageId 0;
BA_ "Confidence" SG_ 941 ICR_infoAppCrc 0;
BA_ "Confidence" SG_ 941 ICR_infoBoardPartNumber17 0;
BA_ "Confidence" SG_ 941 ICR_infoBoardPartNumber814 0;
BA_ "Confidence" SG_ 941 ICR_infoBoardPartNumber1520 0;
BA_ "Confidence" SG_ 667 ICR_lifePresenceMLOutput 0;
BA_ "GenSigSNA" SG_ 667 ICR_lifePresenceMLOutput "255";
BA_ "Confidence" SG_ 667 ICR_largeOccupantPresenceMLOutpu 0;
BA_ "GenSigSNA" SG_ 667 ICR_largeOccupantPresenceMLOutpu "255";
BA_ "SystemSignalLongSymbol" SG_ 667 ICR_largeOccupantPresenceMLOutpu "ICR_largeOccupantPresenceMLOutput";
BA_ "Confidence" SG_ 667 ICR_lifePresenceRaw 0;
BA_ "GenSigSNA" SG_ 667 ICR_lifePresenceRaw "0";
BA_ "Confidence" SG_ 667 ICR_lifePresenceFilt 0;
BA_ "GenSigSNA" SG_ 667 ICR_lifePresenceFilt "0";
BA_ "Confidence" SG_ 667 ICR_largeOccupantPresenceRaw 0;
BA_ "GenSigSNA" SG_ 667 ICR_largeOccupantPresenceRaw "3";
BA_ "Confidence" SG_ 667 ICR_largeOccupantPresenceFilt 0;
BA_ "GenSigSNA" SG_ 667 ICR_largeOccupantPresenceFilt "3";
BA_ "Confidence" SG_ 667 ICR_childPresenceFunctionality 0;
BA_ "GenSigSNA" SG_ 667 ICR_childPresenceFunctionality "2";
BA_ "Confidence" SG_ 667 ICR_userPresenceFunctionality 0;
BA_ "GenSigSNA" SG_ 667 ICR_userPresenceFunctionality "2";
BA_ "Confidence" SG_ 667 ICR_userPresenceMLOutput 0;
BA_ "GenSigSNA" SG_ 667 ICR_userPresenceMLOutput "255";
BA_ "Confidence" SG_ 667 ICR_userPresenceRaw 0;
BA_ "GenSigSNA" SG_ 667 ICR_userPresenceRaw "3";
BA_ "Confidence" SG_ 667 ICR_userPresenceFilt 0;
BA_ "GenSigSNA" SG_ 667 ICR_userPresenceFilt "3";
BA_ "Confidence" SG_ 536 ICR_occupancy1LRaw 0;
BA_ "GenSigSNA" SG_ 536 ICR_occupancy1LRaw "3";
BA_ "Confidence" SG_ 536 ICR_occupancy1RRaw 0;
BA_ "GenSigSNA" SG_ 536 ICR_occupancy1RRaw "3";
BA_ "Confidence" SG_ 536 ICR_occupancy1LVoteCnt 0;
BA_ "Confidence" SG_ 536 ICR_occupancy1RVoteCnt 0;
BA_ "Confidence" SG_ 536 ICR_occupancy1LFilt 0;
BA_ "GenSigSNA" SG_ 536 ICR_occupancy1LFilt "3";
BA_ "Confidence" SG_ 536 ICR_occupancy1RFilt 0;
BA_ "GenSigSNA" SG_ 536 ICR_occupancy1RFilt "3";
BA_ "Confidence" SG_ 536 ICR_occupancy2LFilt 0;
BA_ "GenSigSNA" SG_ 536 ICR_occupancy2LFilt "3";
BA_ "Confidence" SG_ 536 ICR_occupancy2CFilt 0;
BA_ "GenSigSNA" SG_ 536 ICR_occupancy2CFilt "3";
BA_ "Confidence" SG_ 536 ICR_occupancy2RFilt 0;
BA_ "GenSigSNA" SG_ 536 ICR_occupancy2RFilt "3";
BA_ "Confidence" SG_ 536 ICR_occupancy1RFiltExp 0;
BA_ "GenSigSNA" SG_ 536 ICR_occupancy1RFiltExp "3";
BA_ "Confidence" SG_ 536 ICR_occupancyCounter 0;
BA_ "Confidence" SG_ 536 ICR_occupancyChecksum 0;
BA_ "Confidence" SG_ 670 ICR_classification1RFilt 0;
BA_ "GenSigSNA" SG_ 670 ICR_classification1RFilt "0";
BA_ "Confidence" SG_ 670 ICR_classification1LRaw 0;
BA_ "GenSigSNA" SG_ 670 ICR_classification1LRaw "0";
BA_ "Confidence" SG_ 670 ICR_classification1RRaw 0;
BA_ "GenSigSNA" SG_ 670 ICR_classification1RRaw "0";
BA_ "Confidence" SG_ 670 ICR_classification1LMLOutput 0;
BA_ "GenSigSNA" SG_ 670 ICR_classification1LMLOutput "255";
BA_ "Confidence" SG_ 670 ICR_classification1RMLOutput 0;
BA_ "GenSigSNA" SG_ 670 ICR_classification1RMLOutput "255";
BA_ "Confidence" SG_ 670 ICR_classification1LqF 0;
BA_ "Confidence" SG_ 670 ICR_blockageClutterFar 0;
BA_ "GenSigSNA" SG_ 670 ICR_blockageClutterFar "16";
BA_ "Confidence" SG_ 670 ICR_blockageClutterNear 0;
BA_ "GenSigSNA" SG_ 670 ICR_blockageClutterNear "16";
BA_ "Confidence" SG_ 670 ICR_classification1LFilt 0;
BA_ "GenSigSNA" SG_ 670 ICR_classification1LFilt "0";
BA_ "Confidence" SG_ 670 ICR_classification1RqF 0;
BA_ "Confidence" SG_ 670 ICR_classification1LLatched 0;
BA_ "GenSigSNA" SG_ 670 ICR_classification1LLatched "0";
BA_ "Confidence" SG_ 670 ICR_classification1RLatched 0;
BA_ "GenSigSNA" SG_ 670 ICR_classification1RLatched "0";
BA_ "Confidence" SG_ 670 ICR_classification1LIsLatched 0;
BA_ "Confidence" SG_ 670 ICR_classification1RIsLatched 0;
BA_ "Confidence" SG_ 670 ICR_occupancy2Counter 0;
BA_ "Confidence" SG_ 670 ICR_occupancy2Checksum 0;
BA_ "Confidence" SG_ 664 ICR_sensorMode 0;
BA_ "Confidence" SG_ 664 ICR_blocked 0;
BA_ "GenSigSNA" SG_ 664 ICR_blocked "0";
BA_ "Confidence" SG_ 664 ICR_booted 0;
BA_ "Confidence" SG_ 664 ICR_rdMapDumpCompleted 0;
BA_ "Confidence" SG_ 664 ICR_algoVersion 0;
BA_ "Confidence" SG_ 664 ICR_l2HeapUsage 0;
BA_ "Confidence" SG_ 664 ICR_intrusionStatus 0;
BA_ "Confidence" SG_ 664 ICR_blockageScaledMLOutput 0;
BA_ "Confidence" SG_ 1624 ICR_udsResponseData 1;
BA_ "Confidence" SG_ 1012 LS_lightShowIndex 1;
BA_ "Confidence" SG_ 1012 LS_lightLeftRampedChannel1Reques 0;
BA_ "SystemSignalLongSymbol" SG_ 1012 LS_lightLeftRampedChannel1Reques "LS_lightLeftRampedChannel1Request";
BA_ "Confidence" SG_ 1012 LS_lightLeftRampedChannel1Durati 0;
BA_ "SystemSignalLongSymbol" SG_ 1012 LS_lightLeftRampedChannel1Durati "LS_lightLeftRampedChannel1Duration";
BA_ "Confidence" SG_ 1012 LS_lightLeftRampedChannel2Reques 0;
BA_ "SystemSignalLongSymbol" SG_ 1012 LS_lightLeftRampedChannel2Reques "LS_lightLeftRampedChannel2Request";
BA_ "Confidence" SG_ 1012 LS_lightLeftRampedChannel2Durati 0;
BA_ "SystemSignalLongSymbol" SG_ 1012 LS_lightLeftRampedChannel2Durati "LS_lightLeftRampedChannel2Duration";
BA_ "Confidence" SG_ 1012 LS_lightLeftRampedChannel3Reques 0;
BA_ "SystemSignalLongSymbol" SG_ 1012 LS_lightLeftRampedChannel3Reques "LS_lightLeftRampedChannel3Request";
BA_ "Confidence" SG_ 1012 LS_lightLeftRampedChannel3Durati 0;
BA_ "SystemSignalLongSymbol" SG_ 1012 LS_lightLeftRampedChannel3Durati "LS_lightLeftRampedChannel3Duration";
BA_ "Confidence" SG_ 1012 LS_lightLeftRampedChannel4Reques 0;
BA_ "SystemSignalLongSymbol" SG_ 1012 LS_lightLeftRampedChannel4Reques "LS_lightLeftRampedChannel4Request";
BA_ "Confidence" SG_ 1012 LS_lightLeftRampedChannel4Durati 0;
BA_ "SystemSignalLongSymbol" SG_ 1012 LS_lightLeftRampedChannel4Durati "LS_lightLeftRampedChannel4Duration";
BA_ "Confidence" SG_ 1012 LS_lightLeftRampedChannel5Reques 0;
BA_ "SystemSignalLongSymbol" SG_ 1012 LS_lightLeftRampedChannel5Reques "LS_lightLeftRampedChannel5Request";
BA_ "Confidence" SG_ 1012 LS_lightLeftRampedChannel5Durati 0;
BA_ "SystemSignalLongSymbol" SG_ 1012 LS_lightLeftRampedChannel5Durati "LS_lightLeftRampedChannel5Duration";
BA_ "Confidence" SG_ 1012 LS_lightLeftRampedChannel6Reques 0;
BA_ "SystemSignalLongSymbol" SG_ 1012 LS_lightLeftRampedChannel6Reques "LS_lightLeftRampedChannel6Request";
BA_ "Confidence" SG_ 1012 LS_lightLeftRampedChannel6Durati 0;
BA_ "SystemSignalLongSymbol" SG_ 1012 LS_lightLeftRampedChannel6Durati "LS_lightLeftRampedChannel6Duration";
BA_ "Confidence" SG_ 1012 LS_lightLeftRampedChannel7Reques 0;
BA_ "SystemSignalLongSymbol" SG_ 1012 LS_lightLeftRampedChannel7Reques "LS_lightLeftRampedChannel7Request";
BA_ "Confidence" SG_ 1012 LS_lightLeftRampedChannel7Durati 0;
BA_ "SystemSignalLongSymbol" SG_ 1012 LS_lightLeftRampedChannel7Durati "LS_lightLeftRampedChannel7Duration";
BA_ "Confidence" SG_ 1012 LS_lightRightRampedChannel1Reque 0;
BA_ "SystemSignalLongSymbol" SG_ 1012 LS_lightRightRampedChannel1Reque "LS_lightRightRampedChannel1Request";
BA_ "Confidence" SG_ 1012 LS_lightRightRampedChannel1Durat 0;
BA_ "GenSigSNA" SG_ 1012 LS_lightRightRampedChannel1Durat "1";
BA_ "SystemSignalLongSymbol" SG_ 1012 LS_lightRightRampedChannel1Durat "LS_lightRightRampedChannel1Duration";
BA_ "Confidence" SG_ 1012 LS_lightRightRampedChannel2Reque 0;
BA_ "SystemSignalLongSymbol" SG_ 1012 LS_lightRightRampedChannel2Reque "LS_lightRightRampedChannel2Request";
BA_ "Confidence" SG_ 1012 LS_lightRightRampedChannel2Durat 0;
BA_ "GenSigSNA" SG_ 1012 LS_lightRightRampedChannel2Durat "1";
BA_ "SystemSignalLongSymbol" SG_ 1012 LS_lightRightRampedChannel2Durat "LS_lightRightRampedChannel2Duration";
BA_ "Confidence" SG_ 1012 LS_lightRightRampedChannel3Reque 0;
BA_ "SystemSignalLongSymbol" SG_ 1012 LS_lightRightRampedChannel3Reque "LS_lightRightRampedChannel3Request";
BA_ "Confidence" SG_ 1012 LS_lightRightRampedChannel3Durat 0;
BA_ "SystemSignalLongSymbol" SG_ 1012 LS_lightRightRampedChannel3Durat "LS_lightRightRampedChannel3Duration";
BA_ "Confidence" SG_ 1012 LS_lightRightRampedChannel4Reque 0;
BA_ "SystemSignalLongSymbol" SG_ 1012 LS_lightRightRampedChannel4Reque "LS_lightRightRampedChannel4Request";
BA_ "Confidence" SG_ 1012 LS_lightRightRampedChannel4Durat 0;
BA_ "SystemSignalLongSymbol" SG_ 1012 LS_lightRightRampedChannel4Durat "LS_lightRightRampedChannel4Duration";
BA_ "Confidence" SG_ 1012 LS_lightRightRampedChannel5Reque 0;
BA_ "SystemSignalLongSymbol" SG_ 1012 LS_lightRightRampedChannel5Reque "LS_lightRightRampedChannel5Request";
BA_ "Confidence" SG_ 1012 LS_lightRightRampedChannel5Durat 0;
BA_ "SystemSignalLongSymbol" SG_ 1012 LS_lightRightRampedChannel5Durat "LS_lightRightRampedChannel5Duration";
BA_ "Confidence" SG_ 1012 LS_lightRightRampedChannel6Reque 0;
BA_ "SystemSignalLongSymbol" SG_ 1012 LS_lightRightRampedChannel6Reque "LS_lightRightRampedChannel6Request";
BA_ "Confidence" SG_ 1012 LS_lightRightRampedChannel6Durat 0;
BA_ "SystemSignalLongSymbol" SG_ 1012 LS_lightRightRampedChannel6Durat "LS_lightRightRampedChannel6Duration";
BA_ "Confidence" SG_ 1012 LS_lightRightRampedChannel7Reque 0;
BA_ "SystemSignalLongSymbol" SG_ 1012 LS_lightRightRampedChannel7Reque "LS_lightRightRampedChannel7Request";
BA_ "Confidence" SG_ 1012 LS_lightRightRampedChannel7Durat 0;
BA_ "SystemSignalLongSymbol" SG_ 1012 LS_lightRightRampedChannel7Durat "LS_lightRightRampedChannel7Duration";
BA_ "Confidence" SG_ 1012 LS_lightRearTurnLeftRequest 0;
BA_ "Confidence" SG_ 1012 LS_lightRearTurnRightRequest 0;
BA_ "Confidence" SG_ 1012 LS_lightSideRepeaterLeftRequest 0;
BA_ "Confidence" SG_ 1012 LS_lightSideRepeaterRightRequest 0;
BA_ "Confidence" SG_ 1012 LS_lightSideMarkerLeftRequest 0;
BA_ "Confidence" SG_ 1012 LS_lightSideMarkerRightRequest 0;
BA_ "Confidence" SG_ 1012 LS_lightFrontFogLeftRequest 0;
BA_ "Confidence" SG_ 1012 LS_lightFrontFogRightRequest 0;
BA_ "Confidence" SG_ 1012 LS_lightRearFogRequest 0;
BA_ "Confidence" SG_ 1012 LS_lightBrakeRequest 0;
BA_ "Confidence" SG_ 1012 LS_lightTailLeftRequest 0;
BA_ "Confidence" SG_ 1012 LS_lightTailRightRequest 0;
BA_ "Confidence" SG_ 1012 LS_lightLicensePlateRequest 0;
BA_ "Confidence" SG_ 1012 LS_lightReverseRequest 0;
BA_ "Confidence" SG_ 1012 LS_lightAuxParkLeftRequest 0;
BA_ "Confidence" SG_ 1012 LS_lightAuxParkRightRequest 0;
BA_ "Confidence" SG_ 1012 LS_mirrorRequestLeft 0;
BA_ "Confidence" SG_ 1012 LS_mirrorRequestRight 0;
BA_ "Confidence" SG_ 1012 LS_liftgateRequest 0;
BA_ "Confidence" SG_ 1012 LS_windowRequestLF 0;
BA_ "Confidence" SG_ 1012 LS_windowRequestLR 0;
BA_ "Confidence" SG_ 1012 LS_windowRequestRF 0;
BA_ "Confidence" SG_ 1012 LS_windowRequestRR 0;
BA_ "Confidence" SG_ 1012 LS_presentingHandleRequestLF 0;
BA_ "Confidence" SG_ 1012 LS_presentingHandleRequestLR 0;
BA_ "Confidence" SG_ 1012 LS_presentingHandleRequestRF 0;
BA_ "Confidence" SG_ 1012 LS_presentingHandleRequestRR 0;
BA_ "Confidence" SG_ 1012 LS_powerFrontDoorRequestLeft 0;
BA_ "Confidence" SG_ 1012 LS_powerFrontDoorRequestRight 0;
BA_ "Confidence" SG_ 1012 LS_falconDoorRequestLeft 0;
BA_ "Confidence" SG_ 1012 LS_falconDoorRequestRight 0;
BA_ "Confidence" SG_ 1012 LS_chargePortRequest 0;
BA_ "GenSigSNA" SG_ 1012 LS_chargePortRequest "3";
BA_ "Confidence" SG_ 1012 LS_chargePortRaveRequest 0;
BA_ "Confidence" SG_ 1012 LS_suspensionRequest 0;
BA_ "GenSigSNA" SG_ 1012 LS_suspensionRequest "3";
BA_ "Confidence" SG_ 1012 LS_rgbIPFLRed 0;
BA_ "Confidence" SG_ 1012 LS_rgbIPFLGreen 0;
BA_ "Confidence" SG_ 1012 LS_rgbIPFLBlue 0;
BA_ "Confidence" SG_ 1012 LS_rgbIPFRRed 0;
BA_ "Confidence" SG_ 1012 LS_rgbIPFRGreen 0;
BA_ "Confidence" SG_ 1012 LS_rgbIPFRBlue 0;
BA_ "Confidence" SG_ 1012 LS_rgbDoorFLForeRed 0;
BA_ "Confidence" SG_ 1012 LS_rgbDoorFLForeGreen 0;
BA_ "Confidence" SG_ 1012 LS_rgbDoorFLForeBlue 0;
BA_ "Confidence" SG_ 1012 LS_rgbDoorFLAftRed 0;
BA_ "Confidence" SG_ 1012 LS_rgbDoorFLAftGreen 0;
BA_ "Confidence" SG_ 1012 LS_rgbDoorFLAftBlue 0;
BA_ "Confidence" SG_ 1012 LS_rgbDoorFRForeRed 0;
BA_ "Confidence" SG_ 1012 LS_rgbDoorFRForeGreen 0;
BA_ "Confidence" SG_ 1012 LS_rgbDoorFRForeBlue 0;
BA_ "Confidence" SG_ 1012 LS_rgbDoorFRAftRed 0;
BA_ "Confidence" SG_ 1012 LS_rgbDoorFRAftGreen 0;
BA_ "Confidence" SG_ 1012 LS_rgbDoorFRAftBlue 0;
BA_ "Confidence" SG_ 1012 LS_rgbDoorRLForeRed 0;
BA_ "Confidence" SG_ 1012 LS_rgbDoorRLForeGreen 0;
BA_ "Confidence" SG_ 1012 LS_rgbDoorRLForeBlue 0;
BA_ "Confidence" SG_ 1012 LS_rgbDoorRLAftRed 0;
BA_ "Confidence" SG_ 1012 LS_rgbDoorRLAftGreen 0;
BA_ "Confidence" SG_ 1012 LS_rgbDoorRLAftBlue 0;
BA_ "Confidence" SG_ 1012 LS_rgbDoorRRForeRed 0;
BA_ "Confidence" SG_ 1012 LS_rgbDoorRRForeGreen 0;
BA_ "Confidence" SG_ 1012 LS_rgbDoorRRForeBlue 0;
BA_ "Confidence" SG_ 1012 LS_rgbDoorRRAftRed 0;
BA_ "Confidence" SG_ 1012 LS_rgbDoorRRAftGreen 0;
BA_ "Confidence" SG_ 1012 LS_rgbDoorRRAftBlue 0;
BA_ "Confidence" SG_ 1012 LS_frontMatrix0 0;
BA_ "Confidence" SG_ 1012 LS_frontMatrix1 0;
BA_ "Confidence" SG_ 1012 LS_frontMatrix2 0;
BA_ "Confidence" SG_ 1012 LS_frontMatrix3 0;
BA_ "Confidence" SG_ 1012 LS_frontMatrix4 0;
BA_ "Confidence" SG_ 1012 LS_frontMatrix5 0;
BA_ "Confidence" SG_ 1012 LS_frontMatrix6 0;
BA_ "Confidence" SG_ 1012 LS_frontMatrix7 0;
BA_ "Confidence" SG_ 1012 LS_frontMatrix8 0;
BA_ "Confidence" SG_ 1012 LS_frontMatrix9 0;
BA_ "Confidence" SG_ 1012 LS_frontMatrix10 0;
BA_ "Confidence" SG_ 1012 LS_frontMatrix11 0;
BA_ "Confidence" SG_ 1012 LS_frontMatrix12 0;
BA_ "Confidence" SG_ 1012 LS_frontMatrix13 0;
BA_ "Confidence" SG_ 1012 LS_frontMatrix14 0;
BA_ "Confidence" SG_ 1012 LS_frontMatrix15 0;
BA_ "Confidence" SG_ 1012 LS_frontMatrix16 0;
BA_ "Confidence" SG_ 1012 LS_frontMatrix17 0;
BA_ "Confidence" SG_ 1012 LS_frontMatrix18 0;
BA_ "Confidence" SG_ 1012 LS_frontMatrix19 0;
BA_ "Confidence" SG_ 1012 LS_frontMatrix20 0;
BA_ "Confidence" SG_ 1012 LS_frontMatrix21 0;
BA_ "Confidence" SG_ 1012 LS_frontMatrix22 0;
BA_ "Confidence" SG_ 1012 LS_frontMatrix23 0;
BA_ "Confidence" SG_ 1012 LS_frontMatrix24 0;
BA_ "Confidence" SG_ 1012 LS_frontMatrix25 0;
BA_ "Confidence" SG_ 1012 LS_frontMatrix26 0;
BA_ "Confidence" SG_ 1012 LS_frontMatrix27 0;
BA_ "Confidence" SG_ 1012 LS_frontMatrix28 0;
BA_ "Confidence" SG_ 1012 LS_frontMatrix29 0;
BA_ "Confidence" SG_ 1012 LS_frontMatrix30 0;
BA_ "Confidence" SG_ 1012 LS_frontMatrix31 0;
BA_ "Confidence" SG_ 1012 LS_frontMatrix32 0;
BA_ "Confidence" SG_ 1012 LS_frontMatrix33 0;
BA_ "Confidence" SG_ 1012 LS_frontMatrix34 0;
BA_ "Confidence" SG_ 1012 LS_frontMatrix35 0;
BA_ "Confidence" SG_ 1012 LS_frontMatrix36 0;
BA_ "Confidence" SG_ 1012 LS_frontMatrix37 0;
BA_ "Confidence" SG_ 1012 LS_frontMatrix38 0;
BA_ "Confidence" SG_ 1012 LS_frontMatrix39 0;
BA_ "Confidence" SG_ 1012 LS_frontMatrix40 0;
BA_ "Confidence" SG_ 1012 LS_frontMatrix41 0;
BA_ "Confidence" SG_ 1012 LS_frontMatrix42 0;
BA_ "Confidence" SG_ 1012 LS_frontMatrix43 0;
BA_ "Confidence" SG_ 1012 LS_frontMatrix44 0;
BA_ "Confidence" SG_ 1012 LS_frontMatrix45 0;
BA_ "Confidence" SG_ 1012 LS_frontMatrix46 0;
BA_ "Confidence" SG_ 1012 LS_frontMatrix47 0;
BA_ "Confidence" SG_ 1012 LS_frontMatrix48 0;
BA_ "Confidence" SG_ 1012 LS_frontMatrix49 0;
BA_ "Confidence" SG_ 1012 LS_frontMatrix50 0;
BA_ "Confidence" SG_ 1012 LS_frontMatrix51 0;
BA_ "Confidence" SG_ 1012 LS_frontMatrix52 0;
BA_ "Confidence" SG_ 1012 LS_frontMatrix53 0;
BA_ "Confidence" SG_ 1012 LS_frontMatrix54 0;
BA_ "Confidence" SG_ 1012 LS_frontMatrix55 0;
BA_ "Confidence" SG_ 1012 LS_frontMatrix56 0;
BA_ "Confidence" SG_ 1012 LS_frontMatrix57 0;
BA_ "Confidence" SG_ 1012 LS_frontMatrix58 0;
BA_ "Confidence" SG_ 1012 LS_frontMatrix59 0;
BA_ "Confidence" SG_ 1012 LS_rearMatrix0 0;
BA_ "Confidence" SG_ 1012 LS_rearMatrix1 0;
BA_ "Confidence" SG_ 1012 LS_rearMatrix2 0;
BA_ "Confidence" SG_ 1012 LS_rearMatrix3 0;
BA_ "Confidence" SG_ 1012 LS_rearMatrix4 0;
BA_ "Confidence" SG_ 1012 LS_rearMatrix5 0;
BA_ "Confidence" SG_ 1012 LS_rearMatrix6 0;
BA_ "Confidence" SG_ 1012 LS_rearMatrix7 0;
BA_ "Confidence" SG_ 1012 LS_rearMatrix8 0;
BA_ "Confidence" SG_ 1012 LS_rearMatrix9 0;
BA_ "Confidence" SG_ 1012 LS_rearMatrix10 0;
BA_ "Confidence" SG_ 1012 LS_rearMatrix11 0;
BA_ "Confidence" SG_ 1012 LS_rearMatrix12 0;
BA_ "Confidence" SG_ 1012 LS_rearMatrix13 0;
BA_ "Confidence" SG_ 1012 LS_rearMatrix14 0;
BA_ "Confidence" SG_ 1012 LS_rearMatrix15 0;
BA_ "Confidence" SG_ 1012 LS_rearMatrix16 0;
BA_ "Confidence" SG_ 1012 LS_rearMatrix17 0;
BA_ "Confidence" SG_ 1012 LS_rearMatrix18 0;
BA_ "Confidence" SG_ 1012 LS_rearMatrix19 0;
BA_ "Confidence" SG_ 1012 LS_rearMatrix20 0;
BA_ "Confidence" SG_ 1012 LS_rearMatrix21 0;
BA_ "Confidence" SG_ 1012 LS_rearMatrix22 0;
BA_ "Confidence" SG_ 1012 LS_rearMatrix23 0;
BA_ "Confidence" SG_ 1012 LS_rearMatrix24 0;
BA_ "Confidence" SG_ 1012 LS_rearMatrix25 0;
BA_ "Confidence" SG_ 1012 LS_rearMatrix26 0;
BA_ "Confidence" SG_ 1012 LS_rearMatrix27 0;
BA_ "Confidence" SG_ 1012 LS_rearMatrix28 0;
BA_ "Confidence" SG_ 1012 LS_rearMatrix29 0;
BA_ "Confidence" SG_ 1012 LS_rearMatrix30 0;
BA_ "Confidence" SG_ 1012 LS_rearMatrix31 0;
BA_ "Confidence" SG_ 1012 LS_rearMatrix32 0;
BA_ "Confidence" SG_ 1012 LS_rearMatrix33 0;
BA_ "Confidence" SG_ 1012 LS_rearMatrix34 0;
BA_ "Confidence" SG_ 1012 LS_rearMatrix35 0;
BA_ "Confidence" SG_ 1012 LS_rearMatrix36 0;
BA_ "Confidence" SG_ 1012 LS_rearMatrix37 0;
BA_ "Confidence" SG_ 1012 LS_rearMatrix38 0;
BA_ "Confidence" SG_ 1012 LS_rearMatrix39 0;
BA_ "Confidence" SG_ 1012 LS_rearMatrix40 0;
BA_ "Confidence" SG_ 1012 LS_rearMatrix41 0;
BA_ "Confidence" SG_ 1012 LS_rearMatrix42 0;
BA_ "Confidence" SG_ 1012 LS_rearMatrix43 0;
BA_ "Confidence" SG_ 1012 LS_rearMatrix44 0;
BA_ "Confidence" SG_ 1012 LS_rearMatrix45 0;
BA_ "Confidence" SG_ 1012 LS_rearMatrix46 0;
BA_ "Confidence" SG_ 1012 LS_rearMatrix47 0;
BA_ "Confidence" SG_ 1012 LS_rearMatrix48 0;
BA_ "Confidence" SG_ 1012 LS_rearMatrix49 0;
BA_ "Confidence" SG_ 1012 LS_rearMatrix50 0;
BA_ "Confidence" SG_ 1012 LS_rearMatrix51 0;
BA_ "Confidence" SG_ 1012 LS_rearMatrix52 0;
BA_ "Confidence" SG_ 1012 LS_rearMatrix53 0;
BA_ "Confidence" SG_ 1012 LS_rearMatrix54 0;
BA_ "Confidence" SG_ 1012 LS_rearMatrix55 0;
BA_ "Confidence" SG_ 1012 LS_rearMatrix56 0;
BA_ "Confidence" SG_ 1012 LS_rearMatrix57 0;
BA_ "Confidence" SG_ 1012 LS_rearMatrix58 0;
BA_ "Confidence" SG_ 1012 LS_rearMatrix59 0;
BA_ "Confidence" SG_ 1012 LS_offroadLightBar0 0;
BA_ "Confidence" SG_ 1012 LS_offroadLightBar1 0;
BA_ "Confidence" SG_ 1012 LS_offroadLightBar2 0;
BA_ "Confidence" SG_ 1012 LS_offroadLightBar3 0;
BA_ "Confidence" SG_ 1012 LS_offroadLightBar4 0;
BA_ "Confidence" SG_ 1012 LS_offroadLightBar5 0;
BA_ "Confidence" SG_ 1152 ODIN_IsoTpPipeVCSEC0 1;
BA_ "Confidence" SG_ 1152 ODIN_IsoTpPipeVCSEC1 1;
BA_ "Confidence" SG_ 1152 ODIN_IsoTpPipeVCSEC2 1;
BA_ "Confidence" SG_ 1152 ODIN_IsoTpPipeVCSEC3 1;
BA_ "Confidence" SG_ 1152 ODIN_IsoTpPipeVCSEC4 1;
BA_ "Confidence" SG_ 1152 ODIN_IsoTpPipeVCSEC5 1;
BA_ "Confidence" SG_ 1152 ODIN_IsoTpPipeVCSEC6 1;
BA_ "Confidence" SG_ 1152 ODIN_IsoTpPipeVCSEC7 1;
VAL_ 1290 HVP_alertID 71 "a071_PassivePyroVrefRationality" 70 "a070_hvsCanFrameRxDropped" 69 "a069_hviCanFrameRxDropped" 68 "a068_shuntUnexpectedThermistor" 67 "a067_HvilCalNodeMismatch" 65 "a065_FastOpenVshDetected" 64 "a064_BmbAuxVRationality" 63 "a063_BmbBrickVRationality" 62 "a062_BmbOtpConfigError" 61 "a061_ShuntCurrentRationality" 60 "a060_StackVoltageSense" 59 "a059_BmbVrefWarning" 58 "a058_BmbVrefBad" 57 "a057_BatmanDiagnosticsError" 56 "a056_contactorFailedToOpen" 55 "a055_swMissingPartNumber" 54 "a054_swMissingConfigBlock" 53 "a053_hvVoltageSensorRationality" 52 "a052_BmbStatusRegError" 51 "a051_shuntThermistorMia" 50 "a050_fcCtrCloseFailed" 49 "a049_packCtrCloseFailed" 48 "a048_swUnsupportedBmbAsicType" 47 "a047_passivePyroDeploy" 46 "a046_shuntOverTemperature" 45 "a045_dcLinkOverVoltage" 44 "a044_fcContactorForceOpen" 43 "a043_packContactorForceOpen" 42 "a042_fcCtrCloseBlocked" 41 "a041_packCtrCloseBlocked" 40 "a040_FcContactorFellOpen" 39 "a039_PackContactorFellOpen" 38 "a038_CpilFault" 37 "a037_pyroFuseFailedToBlow" 36 "a036_pyroFuseBlown" 35 "a035_packContHwFault" 34 "a034_cpMismatchFault" 33 "a033_fcContHwFault" 32 "a032_ShuntHwAndBmsMiaFault" 31 "a031_packNegCtrArcFault" 30 "a030_PackPosCtrArcFault" 29 "a029_EnsMiaFault" 28 "a028_PackVoltMismatchFault" 27 "a027_BmsMiaOnHvsFault" 26 "a026_HvilFault" 25 "a025_VerSupplyFault" 24 "a024_Supply12vFault" 23 "a023_BmbResetRecovery" 22 "a022_PyroMiaWarning" 21 "a021_PyroMiaFault" 20 "a020_ShuntHwMiaFault" 19 "a019_CpFault" 18 "a018_powerCyclingPcs" 17 "a017_GtwMiaFault" 16 "a016_PcsMiaFault" 15 "a015_CpMiaFault" 14 "a014_BmsMiaOnHviFault" 13 "a013_BmbCommunication" 12 "a012_BmbDataIntegrityLoss" 11 "a011_PrimaryBmbMiaFault" 10 "a010_UnderVoltageFault" 9 "a009_OverVoltageFault" 8 "a008_OverTemperatureFault" 7 "a007_OverCurrentFault" 6 "a006_OverChargeCurrentFault" 5 "a005_OverDchgCurrentFault" 4 "a004_CrashEvent" 3 "a003_SwAssertion" 2 "a002_UnusedAlert2" 1 "a001_WatchdogReset" 0 "ALERT_DO_NOT_USE_ZERO" ;
VAL_ 1290 HVP_alertSet 1 "SET" 0 "CLEARED" ;
VAL_ 1290 HVP_a012_bmbCommStatusTypeA 3 "BYPASSED" 2 "NOMINAL" 1 "BAD" 0 "MISSING" ;
VAL_ 1290 HVP_a012_bmbCommStatusTypeB 3 "BYPASSED" 2 "NOMINAL" 1 "BAD" 0 "MISSING" ;
VAL_ 1290 HVP_a013_bmbCommStatusTypeA 3 "BYPASSED" 2 "NOMINAL" 1 "BAD" 0 "MISSING" ;
VAL_ 1290 HVP_a013_bmbCommStatusTypeB 3 "BYPASSED" 2 "NOMINAL" 1 "BAD" 0 "MISSING" ;
VAL_ 1290 HVP_a013_bmbChainBreakType 5 "TAIL_BREAK" 4 "HEAD_BREAK" 3 "INVALID_BREAK" 2 "DOUBLE_BREAK" 1 "SINGLE_BREAK" 0 "NONE" ;
VAL_ 1290 HVP_a020_energyReserveV 65535 "SNA" ;
VAL_ 1290 HVP_a020_shuntCurrentAux -32768 "SNA" ;
VAL_ 1290 HVP_a020_shuntTemperature -32768 "SNA" ;
VAL_ 1290 HVP_a021_pyroStatus 3 "ACTIVATED" 2 "FAULT" 1 "OK" 0 "UNKNOWN" ;
VAL_ 1290 HVP_a021_SquibResistance 65535 "SNA" ;
VAL_ 1290 HVP_a021_Aout 16383 "SNA" ;
VAL_ 1290 HVP_a022_pyroStatus 3 "ACTIVATED" 2 "FAULT" 1 "OK" 0 "UNKNOWN" ;
VAL_ 1290 HVP_a022_Aout 16383 "SNA" ;
VAL_ 1290 HVP_a022_SquibResistance 65535 "SNA" ;
VAL_ 1290 HVP_a026_hvilStatus 14 "SNA" 13 "PM_OPEN_FAULT" 12 "DI_OPEN_FAULT" 11 "PM_STATUS_MISSING_FAULT" 10 "DI_STATUS_MISSING_FAULT" 9 "VEHICLE_OR_PENTHOUSE_LID_OPEN_FAULT" 8 "NO_12V_SUPPLY" 7 "VEHICLE_NODE_FAULT" 6 "UNKNOWN_LOCATION_OPEN_FAULT" 5 "PENTHOUSE_LID_OPEN_FAULT" 4 "VEHICLE_OPEN_FAULT" 3 "INTERNAL_OPEN_FAULT" 2 "CURRENT_SOURCE_OR_GROUND_LEAK_FAULT" 1 "OK" 0 "UNKNOWN" ;
VAL_ 1290 HVP_a026_internalVoltage 255 "SNA" ;
VAL_ 1290 HVP_a026_dirVoltage 255 "SNA" ;
VAL_ 1290 HVP_a026_difVoltage 255 "SNA" ;
VAL_ 1290 HVP_a036_pyroFiringHandle 12 "PACK_NEGATIVE_CTR_ARC" 11 "PACK_POSITIVE_CTR_ARC" 10 "ENS_CRASH" 9 "SHUNT_MIA" 8 "OPEN_IMMEDIATELY" 7 "TEMPERATURE" 6 "UNDER_VOLTAGE" 5 "OVER_VOLTAGE" 4 "OVER_CURRENT" 3 "OVER_CHARGE_CURRENT" 2 "OVER_DISCHARGE_CURRENT" 1 "HVP" ;
VAL_ 1290 HVP_a037_pyroFiringHandle 12 "PACK_NEGATIVE_CTR_ARC" 11 "PACK_POSITIVE_CTR_ARC" 10 "ENS_CRASH" 9 "SHUNT_MIA" 8 "OPEN_IMMEDIATELY" 7 "TEMPERATURE" 6 "UNDER_VOLTAGE" 5 "OVER_VOLTAGE" 4 "OVER_CURRENT" 3 "OVER_CHARGE_CURRENT" 2 "OVER_DISCHARGE_CURRENT" 1 "HVP" ;
VAL_ 1290 HVP_a049_posCtrState 7 "WELDED" 6 "ECONOMIZED" 5 "OPENING" 4 "PULLED_IN" 3 "BLOCKED" 2 "PRECHARGE" 1 "OPEN" 0 "SNA" ;
VAL_ 1290 HVP_a049_negCtrState 7 "WELDED" 6 "ECONOMIZED" 5 "OPENING" 4 "PULLED_IN" 3 "BLOCKED" 2 "PRECHARGE" 1 "OPEN" 0 "SNA" ;
VAL_ 1290 HVP_a050_posCtrState 7 "WELDED" 6 "ECONOMIZED" 5 "OPENING" 4 "PULLED_IN" 3 "BLOCKED" 2 "PRECHARGE" 1 "OPEN" 0 "SNA" ;
VAL_ 1290 HVP_a050_negCtrState 7 "WELDED" 6 "ECONOMIZED" 5 "OPENING" 4 "PULLED_IN" 3 "BLOCKED" 2 "PRECHARGE" 1 "OPEN" 0 "SNA" ;
VAL_ 1290 HVP_a051_shuntTemperature -32768 "SNA" ;
VAL_ 1290 HVP_a051_shuntCurrent -32768 "SNA" ;
VAL_ 1290 HVP_a051_energyReserveV 65535 "SNA" ;
VAL_ 1290 HVP_a056_diagnosis 2 "PACK_CONTACTOR_WELDED" 1 "HIGH_SHUNT_CURRENT" 0 "SHUNT_CURRENT_SNA" ;
VAL_ 1290 HVP_a056_posPackContactorState 7 "WELDED" 6 "ECONOMIZED" 5 "OPENING" 4 "PULLED_IN" 3 "BLOCKED" 2 "PRECHARGE" 1 "OPEN" 0 "SNA" ;
VAL_ 1290 HVP_a056_negPackContactorState 7 "WELDED" 6 "ECONOMIZED" 5 "OPENING" 4 "PULLED_IN" 3 "BLOCKED" 2 "PRECHARGE" 1 "OPEN" 0 "SNA" ;
VAL_ 1290 HVP_a056_posFcContactorState 7 "WELDED" 6 "ECONOMIZED" 5 "OPENING" 4 "PULLED_IN" 3 "BLOCKED" 2 "PRECHARGE" 1 "OPEN" 0 "SNA" ;
VAL_ 1290 HVP_a056_negFcContactorState 7 "WELDED" 6 "ECONOMIZED" 5 "OPENING" 4 "PULLED_IN" 3 "BLOCKED" 2 "PRECHARGE" 1 "OPEN" 0 "SNA" ;
VAL_ 1290 HVP_a058_VrefStatus 3 "BYPASSED" 2 "NOMINAL" 1 "BAD" 0 "MISSING" ;
VAL_ 1290 HVP_a058_VrefType 2 "REF2" 1 "V3" 0 "V5" ;
VAL_ 1290 HVP_a067_hvilTypeFromHvp 2 "CAN" 1 "LV" 0 "UNKNOWN" ;
VAL_ 1290 HVP_a067_hvilTypeFromGateway 2 "CAN" 1 "LV" 0 "UNKNOWN" ;
VAL_ 1290 HVP_a068_shuntTemperature -32768 "SNA" ;
VAL_ 1290 HVP_a068_shuntCurrent -32768 "SNA" ;
VAL_ 1290 HVP_a068_energyReserveV 65535 "SNA" ;
VAL_ 938 HVP_matrixIndex 1 "AlertMatrix1" 0 "AlertMatrix0" ;
VAL_ 522 HVP_packContNegativeState 7 "CONTACTOR_STATE_WELDED" 6 "CONTACTOR_STATE_ECONOMIZED" 5 "CONTACTOR_STATE_OPENING" 4 "CONTACTOR_STATE_PULLED_IN" 3 "CONTACTOR_STATE_BLOCKED" 2 "CONTACTOR_STATE_PRECHARGE" 1 "CONTACTOR_STATE_OPEN" 0 "CONTACTOR_STATE_SNA" ;
VAL_ 522 HVP_packContPositiveState 7 "CONTACTOR_STATE_WELDED" 6 "CONTACTOR_STATE_ECONOMIZED" 5 "CONTACTOR_STATE_OPENING" 4 "CONTACTOR_STATE_PULLED_IN" 3 "CONTACTOR_STATE_BLOCKED" 2 "CONTACTOR_STATE_PRECHARGE" 1 "CONTACTOR_STATE_OPEN" 0 "CONTACTOR_STATE_SNA" ;
VAL_ 522 HVP_packContactorSetState 9 "CONTACTOR_SET_STATE_NEGATIVE_CLOSED" 8 "CONTACTOR_SET_STATE_POSITIVE_CLOSED" 7 "CONTACTOR_SET_STATE_WELDED" 6 "CONTACTOR_SET_STATE_PARTIAL_WELD" 5 "CONTACTOR_SET_STATE_CLOSED" 4 "CONTACTOR_SET_STATE_OPENING" 3 "CONTACTOR_SET_STATE_BLOCKED" 2 "CONTACTOR_SET_STATE_CLOSING" 1 "CONTACTOR_SET_STATE_OPEN" 0 "CONTACTOR_SET_STATE_SNA" ;
VAL_ 522 HVP_fcContNegativeState 7 "CONTACTOR_STATE_WELDED" 6 "CONTACTOR_STATE_ECONOMIZED" 5 "CONTACTOR_STATE_OPENING" 4 "CONTACTOR_STATE_PULLED_IN" 3 "CONTACTOR_STATE_BLOCKED" 2 "CONTACTOR_STATE_PRECHARGE" 1 "CONTACTOR_STATE_OPEN" 0 "CONTACTOR_STATE_SNA" ;
VAL_ 522 HVP_fcContPositiveState 7 "CONTACTOR_STATE_WELDED" 6 "CONTACTOR_STATE_ECONOMIZED" 5 "CONTACTOR_STATE_OPENING" 4 "CONTACTOR_STATE_PULLED_IN" 3 "CONTACTOR_STATE_BLOCKED" 2 "CONTACTOR_STATE_PRECHARGE" 1 "CONTACTOR_STATE_OPEN" 0 "CONTACTOR_STATE_SNA" ;
VAL_ 522 HVP_fcContactorSetState 9 "CONTACTOR_SET_STATE_NEGATIVE_CLOSED" 8 "CONTACTOR_SET_STATE_POSITIVE_CLOSED" 7 "CONTACTOR_SET_STATE_WELDED" 6 "CONTACTOR_SET_STATE_PARTIAL_WELD" 5 "CONTACTOR_SET_STATE_CLOSED" 4 "CONTACTOR_SET_STATE_OPENING" 3 "CONTACTOR_SET_STATE_BLOCKED" 2 "CONTACTOR_SET_STATE_CLOSING" 1 "CONTACTOR_SET_STATE_OPEN" 0 "CONTACTOR_SET_STATE_SNA" ;
VAL_ 522 HVP_fcCtrsRequestStatus 2 "REQUEST_COMPLETED" 1 "REQUEST_ACTIVE" 0 "REQUEST_NOT_ACTIVE" ;
VAL_ 522 HVP_packCtrsRequestStatus 2 "REQUEST_COMPLETED" 1 "REQUEST_ACTIVE" 0 "REQUEST_NOT_ACTIVE" ;
VAL_ 522 HVP_hvilDiag 14 "SNA" 13 "PM_OPEN_FAULT" 12 "DI_OPEN_FAULT" 11 "PM_STATUS_MISSING_FAULT" 10 "DI_STATUS_MISSING_FAULT" 9 "VEHICLE_OR_PENTHOUSE_LID_OPEN_FAULT" 8 "NO_12V_SUPPLY" 7 "VEHICLE_NODE_FAULT" 6 "UNKNOWN_LOCATION_OPEN_FAULT" 5 "PENTHOUSE_LID_OPEN_FAULT" 4 "VEHICLE_OPEN_FAULT" 3 "INTERNAL_OPEN_FAULT" 2 "CURRENT_SOURCE_OR_GROUND_LEAK_FAULT" 1 "OK" 0 "UNKNOWN" ;
VAL_ 522 HVP_fcLinkAllowedToEnergize 2 "FC_LINK_ENERGY_DC" 1 "FC_LINK_ENERGY_AC" 0 "FC_LINK_ENERGY_NONE" ;
VAL_ 1962 HVP_debugMessageMultiplexer 12 "Mux12" 11 "Mux11" 10 "Mux10" 9 "Mux9" 8 "Mux8" 7 "Mux7" 6 "Mux6" 5 "Mux5" 4 "Mux4" 3 "Mux3" 2 "Mux2" 1 "Mux1" 0 "Mux0" ;
VAL_ 1962 HVP_ecuLogUploadRequest 3 "REQUEST_PRIORITY_3" 2 "REQUEST_PRIORITY_2" 1 "REQUEST_PRIORITY_1" 0 "REQUEST_PRIORITY_NONE" ;
VAL_ 1962 HVP_passivePyroRefVoltageMax 1023 "SNA" ;
VAL_ 1962 HVP_passivePyroRefVoltageMin 1023 "SNA" ;
VAL_ 1666 HVP_hvilStatus 2 "FAULT" 1 "OK" 0 "UNKNOWN" ;
VAL_ 554 HVP_pcsControlRequest 3 "DISCHARGE" 2 "PRECHARGE" 1 "SUPPORT" 0 "SHUTDOWN" ;
VAL_ 554 HVP_dcLinkVoltageFiltered -550 "SNA" ;
VAL_ 784 HVP_infoIndex 255 "END" 31 "SUBCOMPONENT_GITHASH" 30 "PACKAGE_SN_8_14" 29 "PACKAGE_SN_1_7" 27 "PACKAGE_PN_15_20" 26 "PACKAGE_PN_8_14" 25 "PACKAGE_PN_1_7" 23 "SUBCOMPONENT2" 22 "VARIANTCRC" 20 "UDS_PROTOCOL_BOOTCRC" 19 "VERSION_DEPRECATED" 18 "BOOTLOADER_GITHASH" 17 "APP_GITHASH" 16 "SUBCOMPONENT" 15 "BOOTLOADER_CRC" 14 "BOOTLOADER_SVN" 13 "APP_CRC" 11 "PCBAID_ASSYID_USAGEID" 10 "BUILD_HWID_COMPONENTID" 9 "DEPRECATED_9" 8 "DEPRECATED_8" 7 "DEPRECATED_7" 6 "DEPRECATED_6" 5 "DEPRECATED_5" 4 "DEPRECATED_4" 3 "DEPRECATED_3" 2 "DEPRECATED_2" 1 "DEPRECATED_1" 0 "DEPRECATED_0" ;
VAL_ 784 HVP_buildType 4 "INFO_MFG_BUILD" 3 "INFO_TRACEABLE_CI_BUILD" 2 "INFO_LOCAL_BUILD" 1 "INFO_PLATFORM_BUILD" 0 "INFO_UNKNOWN_BUILD" ;
VAL_ 1914 HVP_log1HzIndex 1 "Mux1" 0 "Mux0" ;
VAL_ 1914 HVP_bmbAsicType 3 "BQ796xx" 2 "ADBMS6830" 1 "LTC831" 0 "UNKNOWN" ;
VAL_ 1914 HVP_shuntCurrentAuxLog 8388000 "PACK_CURRENT_SNA" ;
VAL_ 1914 HVP_pyroSquibResistance 65535 "SNA" ;
VAL_ 1914 HVP_hvilCalType 2 "CAN" 1 "LV" 0 "UNKNOWN" ;
VAL_ 1208 ICR_alertID 144 "a144_OccupancyNotificationAlert" 143 "a143_DSPCoreSkipped" 142 "a142_ModeOverrideActive" 141 "a141_RequiresReplacement" 140 "a140_OccupancyExceptionEncountered" 139 "a139_AbnormalBlockageDetected" 138 "a138_DriverSideMismatch" 137 "a137_radarBlocked" 136 "a136_radarHighTemperature" 135 "a135_radarTxBallBreak" 134 "a134_radarPgood" 133 "a133_radarBlocked" 64 "a064_busSleepReqTimeout" 63 "a063_SwitchFault" 62 "a062_XCPWasConnected" 61 "a061_XCPConnected" 60 "a060_engineeringBuild" 59 "a059_inputResistanceHigh" 58 "a058_inputRHighSyncDebug" 46 "a046_Task1000msError" 45 "a045_Task100msError" 44 "a044_Task10msError" 43 "a043_Task1msError" 42 "a042_HighStackUsage" 41 "a041_HighCPULoad" 31 "a031_UDSActive" 30 "a030_ECULogUploadRequest" 29 "a029_CoreDump" 22 "a022_TaskInitError" 21 "a021_TaskSchedulerError" 16 "a016_NVMMRecordError" 15 "a015_NVMMError" 13 "a013_AlertManagerFault" 12 "a012_CPUReset" 6 "a006_CANTX_cyclicError" 5 "a005_CANTXError" 3 "a003_SWAssertion" 2 "a002_PowerLossReset" 1 "a001_WatchdogReset" 0 "ALERT_DO_NOT_USE_ZERO" ;
VAL_ 1208 ICR_alertState 1 "SET" 0 "CLEARED" ;
VAL_ 952 ICR_matrixIndex 2 "AlertMatrix2" 1 "AlertMatrix1" 0 "AlertMatrix0" ;
VAL_ 941 ICR_infoIndex 255 "END" 31 "SUBCOMPONENT_GITHASH" 30 "PACKAGE_SN_8_14" 29 "PACKAGE_SN_1_7" 27 "PACKAGE_PN_15_20" 26 "PACKAGE_PN_8_14" 25 "PACKAGE_PN_1_7" 23 "SUBCOMPONENT2" 22 "VARIANTCRC" 20 "UDS_PROTOCOL_BOOTCRC" 19 "VERSION_DEPRECATED" 18 "BOOTLOADER_GITHASH" 17 "APP_GITHASH" 16 "SUBCOMPONENT" 15 "BOOTLOADER_CRC" 14 "BOOTLOADER_SVN" 13 "APP_CRC" 11 "PCBAID_ASSYID_USAGEID" 10 "BUILD_HWID_COMPONENTID" 9 "DEPRECATED_9" 8 "DEPRECATED_8" 7 "DEPRECATED_7" 6 "DEPRECATED_6" 5 "DEPRECATED_5" 4 "DEPRECATED_4" 3 "DEPRECATED_3" 2 "DEPRECATED_2" 1 "DEPRECATED_1" 0 "DEPRECATED_0" ;
VAL_ 941 ICR_infoBuildType 4 "INFO_MFG_BUILD" 3 "INFO_TRACEABLE_CI_BUILD" 2 "INFO_LOCAL_BUILD" 1 "INFO_PLATFORM_BUILD" 0 "INFO_UNKNOWN_BUILD" ;
VAL_ 667 ICR_lifePresenceMLOutput 255 "SNA" ;
VAL_ 667 ICR_largeOccupantPresenceMLOutpu 255 "SNA" ;
VAL_ 667 ICR_lifePresenceRaw 2 "LIFE_DETECTED" 1 "LIFE_NOT_DETECTED" 0 "LIFE_DETECTED_SNA" ;
VAL_ 667 ICR_lifePresenceFilt 2 "LIFE_DETECTED" 1 "LIFE_NOT_DETECTED" 0 "LIFE_DETECTED_SNA" ;
VAL_ 667 ICR_largeOccupantPresenceRaw 3 "SBRStatus_SEAT_SNA" 2 "SBRStatus_SEAT_FAULTED" 1 "SBRStatus_SEAT_OCCUPIED" 0 "SBRStatus_SEAT_UNOCCUPIED" ;
VAL_ 667 ICR_largeOccupantPresenceFilt 3 "SBRStatus_SEAT_SNA" 2 "SBRStatus_SEAT_FAULTED" 1 "SBRStatus_SEAT_OCCUPIED" 0 "SBRStatus_SEAT_UNOCCUPIED" ;
VAL_ 667 ICR_childPresenceFunctionality 2 "CHILD_PRESENCE_SNA" 1 "CHILD_PRESENCE_ENABLED" 0 "CHILD_PRESENCE_DISABLED" ;
VAL_ 667 ICR_userPresenceFunctionality 2 "CHILD_PRESENCE_SNA" 1 "CHILD_PRESENCE_ENABLED" 0 "CHILD_PRESENCE_DISABLED" ;
VAL_ 667 ICR_userPresenceMLOutput 255 "SNA" ;
VAL_ 667 ICR_userPresenceRaw 3 "SBRStatus_SEAT_SNA" 2 "SBRStatus_SEAT_FAULTED" 1 "SBRStatus_SEAT_OCCUPIED" 0 "SBRStatus_SEAT_UNOCCUPIED" ;
VAL_ 667 ICR_userPresenceFilt 3 "SBRStatus_SEAT_SNA" 2 "SBRStatus_SEAT_FAULTED" 1 "SBRStatus_SEAT_OCCUPIED" 0 "SBRStatus_SEAT_UNOCCUPIED" ;
VAL_ 536 ICR_occupancy1LRaw 3 "SBRStatus_SEAT_SNA" 2 "SBRStatus_SEAT_FAULTED" 1 "SBRStatus_SEAT_OCCUPIED" 0 "SBRStatus_SEAT_UNOCCUPIED" ;
VAL_ 536 ICR_occupancy1RRaw 3 "SBRStatus_SEAT_SNA" 2 "SBRStatus_SEAT_FAULTED" 1 "SBRStatus_SEAT_OCCUPIED" 0 "SBRStatus_SEAT_UNOCCUPIED" ;
VAL_ 536 ICR_occupancy1LFilt 3 "SBRStatus_SEAT_SNA" 2 "SBRStatus_SEAT_FAULTED" 1 "SBRStatus_SEAT_OCCUPIED" 0 "SBRStatus_SEAT_UNOCCUPIED" ;
VAL_ 536 ICR_occupancy1RFilt 3 "SBRStatus_SEAT_SNA" 2 "SBRStatus_SEAT_FAULTED" 1 "SBRStatus_SEAT_OCCUPIED" 0 "SBRStatus_SEAT_UNOCCUPIED" ;
VAL_ 536 ICR_occupancy2LFilt 3 "SBRStatus_SEAT_SNA" 2 "SBRStatus_SEAT_FAULTED" 1 "SBRStatus_SEAT_OCCUPIED" 0 "SBRStatus_SEAT_UNOCCUPIED" ;
VAL_ 536 ICR_occupancy2CFilt 3 "SBRStatus_SEAT_SNA" 2 "SBRStatus_SEAT_FAULTED" 1 "SBRStatus_SEAT_OCCUPIED" 0 "SBRStatus_SEAT_UNOCCUPIED" ;
VAL_ 536 ICR_occupancy2RFilt 3 "SBRStatus_SEAT_SNA" 2 "SBRStatus_SEAT_FAULTED" 1 "SBRStatus_SEAT_OCCUPIED" 0 "SBRStatus_SEAT_UNOCCUPIED" ;
VAL_ 536 ICR_occupancy1RFiltExp 3 "SBRStatus_SEAT_SNA" 2 "SBRStatus_SEAT_FAULTED" 1 "SBRStatus_SEAT_OCCUPIED" 0 "SBRStatus_SEAT_UNOCCUPIED" ;
VAL_ 670 ICR_classification1RFilt 4 "OCCUPANT_CLASSIFICATION_OCCUPIED_ALLOW" 3 "OCCUPANT_CLASSIFICATION_OCCUPIED_INHIBIT" 2 "OCCUPANT_CLASSIFICATION_EMPTY" 1 "OCCUPANT_CLASSIFICATION_INIT" 0 "OCCUPANT_CLASSIFICATION_SNA" ;
VAL_ 670 ICR_classification1LRaw 4 "OCCUPANT_CLASSIFICATION_OCCUPIED_ALLOW" 3 "OCCUPANT_CLASSIFICATION_OCCUPIED_INHIBIT" 2 "OCCUPANT_CLASSIFICATION_EMPTY" 1 "OCCUPANT_CLASSIFICATION_INIT" 0 "OCCUPANT_CLASSIFICATION_SNA" ;
VAL_ 670 ICR_classification1RRaw 4 "OCCUPANT_CLASSIFICATION_OCCUPIED_ALLOW" 3 "OCCUPANT_CLASSIFICATION_OCCUPIED_INHIBIT" 2 "OCCUPANT_CLASSIFICATION_EMPTY" 1 "OCCUPANT_CLASSIFICATION_INIT" 0 "OCCUPANT_CLASSIFICATION_SNA" ;
VAL_ 670 ICR_classification1LMLOutput 255 "SNA" ;
VAL_ 670 ICR_classification1RMLOutput 255 "SNA" ;
VAL_ 670 ICR_classification1LqF 1 "OCCUPANT_CLASSIFICATION_NOT_FAULTED" 0 "OCCUPANT_CLASSIFICATION_FAULTED" ;
VAL_ 670 ICR_blockageClutterFar -16 "SNA" ;
VAL_ 670 ICR_blockageClutterNear -16 "SNA" ;
VAL_ 670 ICR_classification1LFilt 4 "OCCUPANT_CLASSIFICATION_OCCUPIED_ALLOW" 3 "OCCUPANT_CLASSIFICATION_OCCUPIED_INHIBIT" 2 "OCCUPANT_CLASSIFICATION_EMPTY" 1 "OCCUPANT_CLASSIFICATION_INIT" 0 "OCCUPANT_CLASSIFICATION_SNA" ;
VAL_ 670 ICR_classification1RqF 1 "OCCUPANT_CLASSIFICATION_NOT_FAULTED" 0 "OCCUPANT_CLASSIFICATION_FAULTED" ;
VAL_ 670 ICR_classification1LLatched 4 "OCCUPANT_CLASSIFICATION_OCCUPIED_ALLOW" 3 "OCCUPANT_CLASSIFICATION_OCCUPIED_INHIBIT" 2 "OCCUPANT_CLASSIFICATION_EMPTY" 1 "OCCUPANT_CLASSIFICATION_INIT" 0 "OCCUPANT_CLASSIFICATION_SNA" ;
VAL_ 670 ICR_classification1RLatched 4 "OCCUPANT_CLASSIFICATION_OCCUPIED_ALLOW" 3 "OCCUPANT_CLASSIFICATION_OCCUPIED_INHIBIT" 2 "OCCUPANT_CLASSIFICATION_EMPTY" 1 "OCCUPANT_CLASSIFICATION_INIT" 0 "OCCUPANT_CLASSIFICATION_SNA" ;
VAL_ 664 ICR_sensorMode 15 "ICR_SENSOR_INTERFACE_MODE_ERROR" 7 "ICR_SENSOR_INTERFACE_MODE_LPM_TEST" 6 "ICR_SENSOR_INTERFACE_MODE_OCCUPANCY_DETECTION" 5 "ICR_SENSOR_INTERFACE_MODE_HPM_TEST" 4 "ICR_SENSOR_INTERFACE_MODE_CALIBRATION" 3 "ICR_SENSOR_INTERFACE_MODE_CW" 2 "ICR_SENSOR_MODE_END_OF_LINE_TEST" 1 "ICR_SENSOR_MODE_INTRUSTION" 0 "ICR_SENSOR_MODE_SENSOR_STOPPED" ;
VAL_ 664 ICR_blocked 2 "ICR_BLOCKED_TRUE" 1 "ICR_BLOCKED_FALSE" 0 "ICR_BLOCKED_SNA" ;
VAL_ 664 ICR_algoVersion 37 "ICR_ALGO_VERSION_FUTURE_RELEASE_37" 36 "ICR_ALGO_VERSION_v06112025" 35 "ICR_ALGO_VERSION_v04232025" 34 "ICR_ALGO_VERSION_v03192025" 33 "ICR_ALGO_VERSION_v02142025" 32 "ICR_ALGO_VERSION_v01222025" 31 "ICR_ALGO_VERSION_v10072024" 30 "ICR_ALGO_VERSION_v08282024" 29 "ICR_ALGO_VERSION_v07172024" 28 "ICR_ALGO_VERSION_v06122024" 27 "ICR_ALGO_VERSION_v04242024" 26 "ICR_ALGO_VERSION_v03142024" 25 "ICR_ALGO_VERSION_v01312024" 24 "ICR_ALGO_VERSION_v12192023" 23 "ICR_ALGO_VERSION_v10252023" 22 "ICR_ALGO_VERSION_v10112023" 21 "ICR_ALGO_VERSION_v09222023" 20 "ICR_ALGO_VERSION_V08302023" 19 "ICR_ALGO_VERSION_V07172023" 18 "ICR_ALGO_VERSION_V06152023" 17 "ICR_ALGO_VERSION_V06072023" 16 "ICR_ALGO_VERSION_V05192023" 15 "ICR_ALGO_VERSION_V04262023" 14 "ICR_ALGO_VERSION_V1222" 13 "ICR_ALGO_VERSION_V1125" 12 "ICR_ALGO_VERSION_V1118" 11 "ICR_ALGO_VERSION_V1103" 10 "ICR_ALGO_VERSION_V1013" 9 "ICR_ALGO_VERSION_V1006" 8 "ICR_ALGO_VERSION_V927" 7 "ICR_ALGO_VERSION_V902" 6 "ICR_ALGO_VERSION_V826" 5 "ICR_ALGO_VERSION_V803" 4 "ICR_ALGO_VERSION_V715" 3 "ICR_ALGO_VERSION_V711" 2 "ICR_ALGO_VERSION_V204" 1 "ICR_ALGO_VERSION_EXPERIMENTAL" 0 "ICR_ALGO_VERSION_NONE" ;
VAL_ 664 ICR_intrusionStatus 2 "INSTRUSION_STATUS_INTRUSION_DETECTED" 1 "INSTRUSION_STATUS_NONE" 0 "INSTRUSION_STATUS_UNKNOWN" ;
VAL_ 1012 LS_lightShowIndex 24 "LightShowMux24" 23 "LightShowMux23" 22 "LightShowMux22" 21 "LightShowMux21" 20 "LightShowMux20" 19 "LightShowMux19" 18 "LightShowMux18" 17 "LightShowMux17" 16 "LightShowMux16" 15 "LightShowMux15" 14 "LightShowMux14" 13 "LightShowMux13" 12 "LightShowMux12" 11 "LightShowMux11" 10 "LightShowMux10" 9 "LightShowMux9" 8 "LightShowMux8" 7 "LightShowMux7" 6 "LightShowMux6" 5 "LightShowMux5" 4 "LightShowMux4" 3 "LightShowMux3" 2 "LightShowMux2" 1 "LightShowMux1" 0 "LightShowMux0" ;
VAL_ 1012 LS_lightLeftRampedChannel1Durati 3 "TWO_SECONDS" 2 "ONE_SECOND" 1 "HALF_SECOND" 0 "INSTANT" ;
VAL_ 1012 LS_lightLeftRampedChannel2Durati 3 "TWO_SECONDS" 2 "ONE_SECOND" 1 "HALF_SECOND" 0 "INSTANT" ;
VAL_ 1012 LS_lightLeftRampedChannel3Durati 3 "TWO_SECONDS" 2 "ONE_SECOND" 1 "HALF_SECOND" 0 "INSTANT" ;
VAL_ 1012 LS_lightLeftRampedChannel4Durati 3 "TWO_SECONDS" 2 "ONE_SECOND" 1 "HALF_SECOND" 0 "INSTANT" ;
VAL_ 1012 LS_lightLeftRampedChannel5Durati 3 "TWO_SECONDS" 2 "ONE_SECOND" 1 "HALF_SECOND" 0 "INSTANT" ;
VAL_ 1012 LS_lightLeftRampedChannel6Durati 3 "TWO_SECONDS" 2 "ONE_SECOND" 1 "HALF_SECOND" 0 "INSTANT" ;
VAL_ 1012 LS_lightLeftRampedChannel7Durati 3 "TWO_SECONDS" 2 "ONE_SECOND" 1 "HALF_SECOND" 0 "INSTANT" ;
VAL_ 1012 LS_lightRightRampedChannel1Durat 3 "TWO_SECONDS" 2 "ONE_SECOND" 1 "HALF_SECOND" 0 "INSTANT" ;
VAL_ 1012 LS_lightRightRampedChannel2Durat 3 "TWO_SECONDS" 2 "ONE_SECOND" 1 "HALF_SECOND" 0 "INSTANT" ;
VAL_ 1012 LS_lightRightRampedChannel3Durat 3 "TWO_SECONDS" 2 "ONE_SECOND" 1 "HALF_SECOND" 0 "INSTANT" ;
VAL_ 1012 LS_lightRightRampedChannel4Durat 3 "TWO_SECONDS" 2 "ONE_SECOND" 1 "HALF_SECOND" 0 "INSTANT" ;
VAL_ 1012 LS_lightRightRampedChannel5Durat 3 "TWO_SECONDS" 2 "ONE_SECOND" 1 "HALF_SECOND" 0 "INSTANT" ;
VAL_ 1012 LS_lightRightRampedChannel6Durat 3 "TWO_SECONDS" 2 "ONE_SECOND" 1 "HALF_SECOND" 0 "INSTANT" ;
VAL_ 1012 LS_lightRightRampedChannel7Durat 3 "TWO_SECONDS" 2 "ONE_SECOND" 1 "HALF_SECOND" 0 "INSTANT" ;
VAL_ 1012 LS_mirrorRequestLeft 4 "HOLIDAY_PARTY_STOP" 3 "HOLIDAY_PARTY_CLOSE" 2 "HOLIDAY_PARTY_DANCE" 1 "HOLIDAY_PARTY_OPEN" 0 "HOLIDAY_PARTY_IDLE" ;
VAL_ 1012 LS_mirrorRequestRight 4 "HOLIDAY_PARTY_STOP" 3 "HOLIDAY_PARTY_CLOSE" 2 "HOLIDAY_PARTY_DANCE" 1 "HOLIDAY_PARTY_OPEN" 0 "HOLIDAY_PARTY_IDLE" ;
VAL_ 1012 LS_liftgateRequest 4 "HOLIDAY_PARTY_STOP" 3 "HOLIDAY_PARTY_CLOSE" 2 "HOLIDAY_PARTY_DANCE" 1 "HOLIDAY_PARTY_OPEN" 0 "HOLIDAY_PARTY_IDLE" ;
VAL_ 1012 LS_windowRequestLF 4 "HOLIDAY_PARTY_STOP" 3 "HOLIDAY_PARTY_CLOSE" 2 "HOLIDAY_PARTY_DANCE" 1 "HOLIDAY_PARTY_OPEN" 0 "HOLIDAY_PARTY_IDLE" ;
VAL_ 1012 LS_windowRequestLR 4 "HOLIDAY_PARTY_STOP" 3 "HOLIDAY_PARTY_CLOSE" 2 "HOLIDAY_PARTY_DANCE" 1 "HOLIDAY_PARTY_OPEN" 0 "HOLIDAY_PARTY_IDLE" ;
VAL_ 1012 LS_windowRequestRF 4 "HOLIDAY_PARTY_STOP" 3 "HOLIDAY_PARTY_CLOSE" 2 "HOLIDAY_PARTY_DANCE" 1 "HOLIDAY_PARTY_OPEN" 0 "HOLIDAY_PARTY_IDLE" ;
VAL_ 1012 LS_windowRequestRR 4 "HOLIDAY_PARTY_STOP" 3 "HOLIDAY_PARTY_CLOSE" 2 "HOLIDAY_PARTY_DANCE" 1 "HOLIDAY_PARTY_OPEN" 0 "HOLIDAY_PARTY_IDLE" ;
VAL_ 1012 LS_presentingHandleRequestLF 4 "HOLIDAY_PARTY_STOP" 3 "HOLIDAY_PARTY_CLOSE" 2 "HOLIDAY_PARTY_DANCE" 1 "HOLIDAY_PARTY_OPEN" 0 "HOLIDAY_PARTY_IDLE" ;
VAL_ 1012 LS_presentingHandleRequestLR 4 "HOLIDAY_PARTY_STOP" 3 "HOLIDAY_PARTY_CLOSE" 2 "HOLIDAY_PARTY_DANCE" 1 "HOLIDAY_PARTY_OPEN" 0 "HOLIDAY_PARTY_IDLE" ;
VAL_ 1012 LS_presentingHandleRequestRF 4 "HOLIDAY_PARTY_STOP" 3 "HOLIDAY_PARTY_CLOSE" 2 "HOLIDAY_PARTY_DANCE" 1 "HOLIDAY_PARTY_OPEN" 0 "HOLIDAY_PARTY_IDLE" ;
VAL_ 1012 LS_presentingHandleRequestRR 4 "HOLIDAY_PARTY_STOP" 3 "HOLIDAY_PARTY_CLOSE" 2 "HOLIDAY_PARTY_DANCE" 1 "HOLIDAY_PARTY_OPEN" 0 "HOLIDAY_PARTY_IDLE" ;
VAL_ 1012 LS_powerFrontDoorRequestLeft 4 "HOLIDAY_PARTY_STOP" 3 "HOLIDAY_PARTY_CLOSE" 2 "HOLIDAY_PARTY_DANCE" 1 "HOLIDAY_PARTY_OPEN" 0 "HOLIDAY_PARTY_IDLE" ;
VAL_ 1012 LS_powerFrontDoorRequestRight 4 "HOLIDAY_PARTY_STOP" 3 "HOLIDAY_PARTY_CLOSE" 2 "HOLIDAY_PARTY_DANCE" 1 "HOLIDAY_PARTY_OPEN" 0 "HOLIDAY_PARTY_IDLE" ;
VAL_ 1012 LS_falconDoorRequestLeft 4 "HOLIDAY_PARTY_STOP" 3 "HOLIDAY_PARTY_CLOSE" 2 "HOLIDAY_PARTY_DANCE" 1 "HOLIDAY_PARTY_OPEN" 0 "HOLIDAY_PARTY_IDLE" ;
VAL_ 1012 LS_falconDoorRequestRight 4 "HOLIDAY_PARTY_STOP" 3 "HOLIDAY_PARTY_CLOSE" 2 "HOLIDAY_PARTY_DANCE" 1 "HOLIDAY_PARTY_OPEN" 0 "HOLIDAY_PARTY_IDLE" ;
VAL_ 1012 LS_chargePortRequest 3 "REQUEST_SNA" 2 "REQUEST_CLOSE" 1 "REQUEST_OPEN" 0 "REQUEST_NONE" ;
VAL_ 1012 LS_suspensionRequest 3 "SUSPENSION_REQUEST_SNA" 2 "SUSPENSION_REQUEST_LOWER" 1 "SUSPENSION_REQUEST_RAISE" 0 "SUSPENSION_REQUEST_NONE" ;
